[part 1 of 3: package /RB/PT/PCT_TopLvlComposition/SwComponentTypes]
AUTOSAR XML (schema 4-0-3)
package /RB/PT/PCT_TopLvlComposition/SwComponentTypes
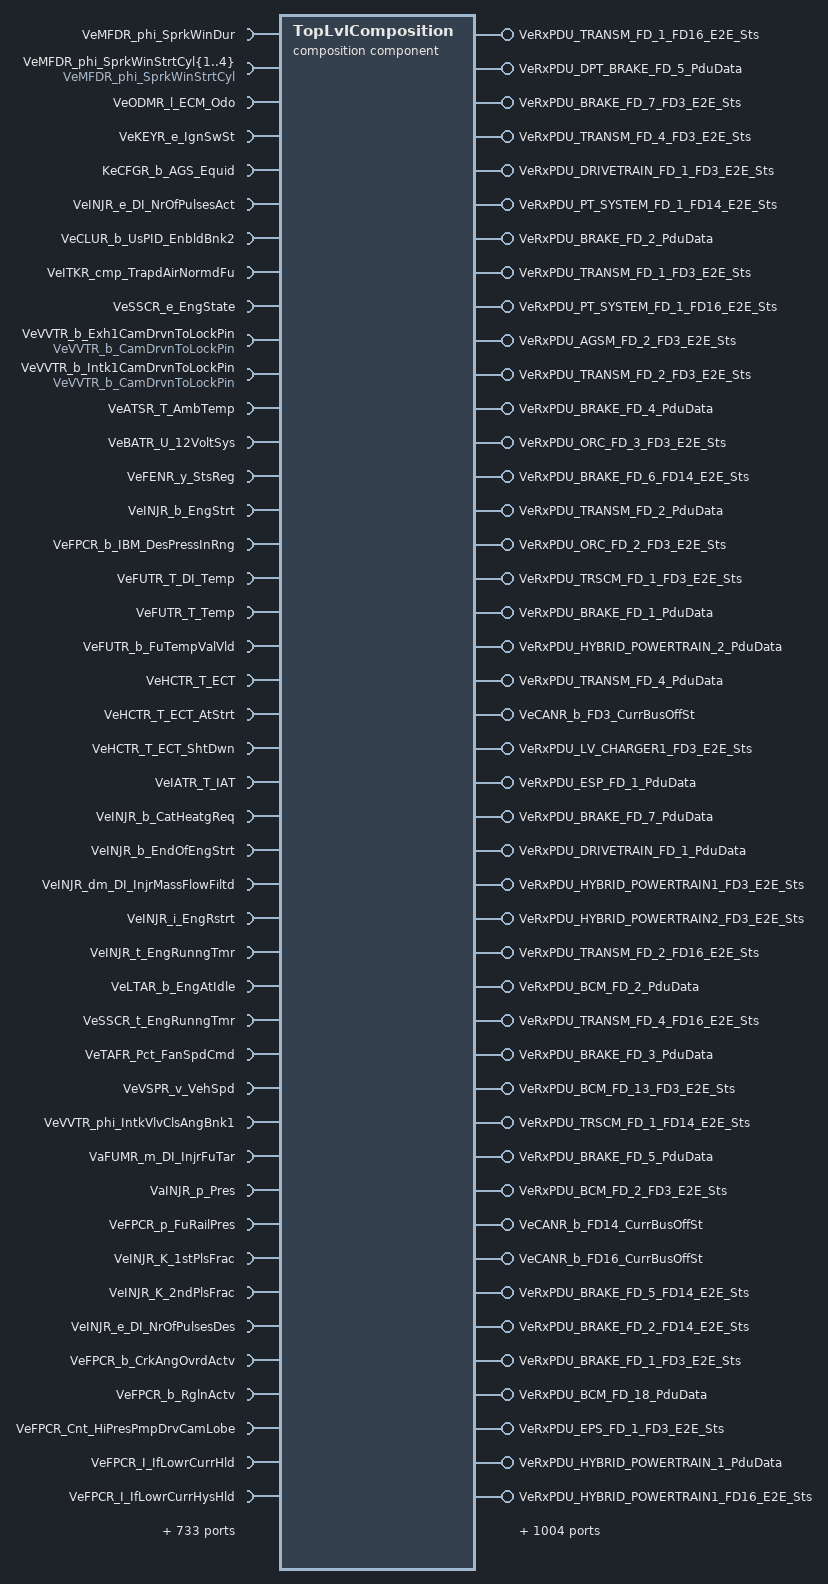
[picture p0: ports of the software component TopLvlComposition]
  composition sw component type TopLvlComposition
    59 x provide port:
      VeRxPDU_TRANSM_FD_1_FD16_E2E_Sts: provided-interface=VeRxPDU_TRANSM_FD_1_FD16_E2E_Sts
      VeRxPDU_DPT_BRAKE_FD_5_PduData: provided-interface=VeRxPDU_DPT_BRAKE_FD_5_PduData
      VeRxPDU_BRAKE_FD_7_FD3_E2E_Sts: provided-interface=VeRxPDU_BRAKE_FD_7_FD3_E2E_Sts
      VeRxPDU_TRANSM_FD_4_FD3_E2E_Sts: provided-interface=VeRxPDU_TRANSM_FD_4_FD3_E2E_Sts
      VeRxPDU_DRIVETRAIN_FD_1_FD3_E2E_Sts: provided-interface=VeRxPDU_DRIVETRAIN_FD_1_FD3_E2E_Sts
      VeRxPDU_PT_SYSTEM_FD_1_FD14_E2E_Sts: provided-interface=VeRxPDU_PT_SYSTEM_FD_1_FD14_E2E_Sts
      VeRxPDU_BRAKE_FD_2_PduData: provided-interface=VeRxPDU_BRAKE_FD_2_PduData
      VeRxPDU_TRANSM_FD_1_FD3_E2E_Sts: provided-interface=VeRxPDU_TRANSM_FD_1_FD3_E2E_Sts
      VeRxPDU_PT_SYSTEM_FD_1_FD16_E2E_Sts: provided-interface=VeRxPDU_PT_SYSTEM_FD_1_FD16_E2E_Sts
      VeRxPDU_AGSM_FD_2_FD3_E2E_Sts: provided-interface=VeRxPDU_AGSM_FD_2_FD3_E2E_Sts
      VeRxPDU_TRANSM_FD_2_FD3_E2E_Sts: provided-interface=VeRxPDU_TRANSM_FD_2_FD3_E2E_Sts
      VeRxPDU_BRAKE_FD_4_PduData: provided-interface=VeRxPDU_BRAKE_FD_4_PduData
      VeRxPDU_ORC_FD_3_FD3_E2E_Sts: provided-interface=VeRxPDU_ORC_FD_3_FD3_E2E_Sts
      VeRxPDU_BRAKE_FD_6_FD14_E2E_Sts: provided-interface=VeRxPDU_BRAKE_FD_6_FD14_E2E_Sts
      VeRxPDU_TRANSM_FD_2_PduData: provided-interface=VeRxPDU_TRANSM_FD_2_PduData
      VeRxPDU_ORC_FD_2_FD3_E2E_Sts: provided-interface=VeRxPDU_ORC_FD_2_FD3_E2E_Sts
      VeRxPDU_TRSCM_FD_1_FD3_E2E_Sts: provided-interface=VeRxPDU_TRSCM_FD_1_FD3_E2E_Sts
      VeRxPDU_BRAKE_FD_1_PduData: provided-interface=VeRxPDU_BRAKE_FD_1_PduData
      VeRxPDU_HYBRID_POWERTRAIN_2_PduData: provided-interface=VeRxPDU_HYBRID_POWERTRAIN_2_PduData
      VeRxPDU_TRANSM_FD_4_PduData: provided-interface=VeRxPDU_TRANSM_FD_4_PduData
      VeCANR_b_FD3_CurrBusOffSt: provided-interface=VeCANR_b_FD3_CurrBusOffSt
      VeRxPDU_LV_CHARGER1_FD3_E2E_Sts: provided-interface=VeRxPDU_LV_CHARGER1_FD3_E2E_Sts
      VeRxPDU_ESP_FD_1_PduData: provided-interface=VeRxPDU_ESP_FD_1_PduData
      VeRxPDU_BRAKE_FD_7_PduData: provided-interface=VeRxPDU_BRAKE_FD_7_PduData
      VeRxPDU_DRIVETRAIN_FD_1_PduData: provided-interface=VeRxPDU_DRIVETRAIN_FD_1_PduData
      VeRxPDU_HYBRID_POWERTRAIN1_FD3_E2E_Sts: provided-interface=VeRxPDU_HYBRID_POWERTRAIN1_FD3_E2E_Sts
      VeRxPDU_HYBRID_POWERTRAIN2_FD3_E2E_Sts: provided-interface=VeRxPDU_HYBRID_POWERTRAIN2_FD3_E2E_Sts
      VeRxPDU_TRANSM_FD_2_FD16_E2E_Sts: provided-interface=VeRxPDU_TRANSM_FD_2_FD16_E2E_Sts
      VeRxPDU_BCM_FD_2_PduData: provided-interface=VeRxPDU_BCM_FD_2_PduData
      VeRxPDU_TRANSM_FD_4_FD16_E2E_Sts: provided-interface=VeRxPDU_TRANSM_FD_4_FD16_E2E_Sts
      VeRxPDU_BRAKE_FD_3_PduData: provided-interface=VeRxPDU_BRAKE_FD_3_PduData
      VeRxPDU_BCM_FD_13_FD3_E2E_Sts: provided-interface=VeRxPDU_BCM_FD_13_FD3_E2E_Sts
      VeRxPDU_TRSCM_FD_1_FD14_E2E_Sts: provided-interface=VeRxPDU_TRSCM_FD_1_FD14_E2E_Sts
      VeRxPDU_BRAKE_FD_5_PduData: provided-interface=VeRxPDU_BRAKE_FD_5_PduData
      VeRxPDU_BCM_FD_2_FD3_E2E_Sts: provided-interface=VeRxPDU_BCM_FD_2_FD3_E2E_Sts
      VeCANR_b_FD14_CurrBusOffSt: provided-interface=VeCANR_b_FD14_CurrBusOffSt
      VeCANR_b_FD16_CurrBusOffSt: provided-interface=VeCANR_b_FD16_CurrBusOffSt
      VeRxPDU_BRAKE_FD_5_FD14_E2E_Sts: provided-interface=VeRxPDU_BRAKE_FD_5_FD14_E2E_Sts
      VeRxPDU_BRAKE_FD_2_FD14_E2E_Sts: provided-interface=VeRxPDU_BRAKE_FD_2_FD14_E2E_Sts
      VeRxPDU_BRAKE_FD_1_FD3_E2E_Sts: provided-interface=VeRxPDU_BRAKE_FD_1_FD3_E2E_Sts
      VeRxPDU_BCM_FD_18_PduData: provided-interface=VeRxPDU_BCM_FD_18_PduData
      VeRxPDU_EPS_FD_1_FD3_E2E_Sts: provided-interface=VeRxPDU_EPS_FD_1_FD3_E2E_Sts
      VeRxPDU_HYBRID_POWERTRAIN_1_PduData: provided-interface=VeRxPDU_HYBRID_POWERTRAIN_1_PduData
      VeRxPDU_HYBRID_POWERTRAIN1_FD16_E2E_Sts: provided-interface=VeRxPDU_HYBRID_POWERTRAIN1_FD16_E2E_Sts
      VeRxPDU_HYBRID_POWERTRAIN2_FD16_E2E_Sts: provided-interface=VeRxPDU_HYBRID_POWERTRAIN2_FD16_E2E_Sts
      VeRxPDU_HYBRID_POWERTRAIN_5_PduData: provided-interface=VeRxPDU_HYBRID_POWERTRAIN_5_PduData
      VeRxPDU_BRAKE_FD_5_FD3_E2E_Sts: provided-interface=VeRxPDU_BRAKE_FD_5_FD3_E2E_Sts
      VeRxPDU_HYBRID_POWERTRAIN5_FD3_E2E_Sts: provided-interface=VeRxPDU_HYBRID_POWERTRAIN5_FD3_E2E_Sts
      VeRxPDU_HYBRID_POWERTRAIN5_FD16_E2E_Sts: provided-interface=VeRxPDU_HYBRID_POWERTRAIN5_FD16_E2E_Sts
      VeRxPDU_ADAS_FD_INFO_FD14_E2E_Sts: provided-interface=VeRxPDU_ADAS_FD_INFO_FD14_E2E_Sts
      VeRxPDU_BRAKE_FD_3_FD3_E2E_Sts: provided-interface=VeRxPDU_BRAKE_FD_3_FD3_E2E_Sts
      VeRxPDU_BCM_FD_9_FD3_E2E_Sts: provided-interface=VeRxPDU_BCM_FD_9_FD3_E2E_Sts
      VeRxPDU_BRAKE_FD_2_FD3_E2E_Sts: provided-interface=VeRxPDU_BRAKE_FD_2_FD3_E2E_Sts
      VeRxPDU_BRAKE_FD_4_FD3_E2E_Sts: provided-interface=VeRxPDU_BRAKE_FD_4_FD3_E2E_Sts
      VeRxPDU_DPT_BRAKE_FD_2_PduData: provided-interface=VeRxPDU_DPT_BRAKE_FD_2_PduData
      VeRxPDU_BCM_FD_18_FD3_E2E_Sts: provided-interface=VeRxPDU_BCM_FD_18_FD3_E2E_Sts
      VeRxPDU_TRANSM_FD_1_PduData: provided-interface=VeRxPDU_TRANSM_FD_1_PduData
      VeLISR_h_DigIonSnsRes1: provided-interface=VeLISR_h_DigIonSnsRes
      VeLISR_h_DigIonSnsRes2: provided-interface=VeLISR_h_DigIonSnsRes
    11 x require port:
      VeMFDR_phi_SprkWinDur: required-interface=VeMFDR_phi_SprkWinDur
      VeMFDR_phi_SprkWinStrtCyl{1..4}: required-interface=VeMFDR_phi_SprkWinStrtCyl
      VeODMR_l_ECM_Odo: required-interface=VeODMR_l_ECM_Odo
      VeKEYR_e_IgnSwSt: required-interface=VeKEYR_e_IgnSwSt
      KeCFGR_b_AGS_Equid: required-interface=KeCFGR_b_AGS_Equid
      VeINJR_e_DI_NrOfPulsesAct: required-interface=VeINJR_e_DI_NrOfPulsesAct
      VeCLUR_b_UsPID_EnbldBnk2: required-interface=VeCLUR_b_UsPID_EnbldBnk2
      VeITKR_cmp_TrapdAirNormdFu: required-interface=VeITKR_cmp_TrapdAirNormdFu
    5 x provide port, all with provided-interface=IFMdulPwrMod:
      MdulPwrMod_{0..3}_Q_1
      MdulPwrMod_1_B_1
    require port VeSSCR_e_EngState: required-interface=VeSSCR_e_EngState
    provide port VeLBPR_p_BaroPress: provided-interface=VeLBPR_p_BaroPress
    require port VeVVTR_b_Exh1CamDrvnToLockPin: required-interface=VeVVTR_b_CamDrvnToLockPin
    require port VeVVTR_b_Intk1CamDrvnToLockPin: required-interface=VeVVTR_b_CamDrvnToLockPin
    72 x provide port:
      VeCAMR_b_Exh1CamInLimpIn: provided-interface=VeCAMR_b_CamInLimpIn
      VeCAMR_b_Intk1CamInLimpIn: provided-interface=VeCAMR_b_CamInLimpIn
      VeCAMR_b_IsExh1CamLockd: provided-interface=VeXXXR_b_IsLockd
      VeCAMR_b_IsIntk1CamLockd: provided-interface=VeXXXR_b_IsLockd
      VeCAMR_phi_Exh1CCLAdjdLkpn: provided-interface=VeCAMR_phi_CCL_AdjdLkpn
      VeCAMR_phi_Exh1CCLPosn: provided-interface=VeCAMR_phi_CCL_Posn
      VeCAMR_phi_Intk1CCLAdjdLkpn: provided-interface=VeCAMR_phi_CCL_AdjdLkpn
      VeCAMR_phi_Intk1CCLPosn: provided-interface=VeCAMR_phi_CCL_Posn
      VeCRKR_b_CrksftUnlckdInRun: provided-interface=VeCRKR_b_CrksftUnlckdInRun
      VeCRKR_b_IsCrksftLockd: provided-interface=VeXXXR_b_IsLockd
      VeCRKR_t_EPP_Prd: provided-interface=VeEPSR_t_EngPwrPlsPrd
      VeEPSR_Cnt_AirPrdtnFuCalcn_Eve: provided-interface=VeEPSR_Cnt_AirPrdtnFuCalcn_Eve
      VeEPSR_Cnt_BDCC_Eve: provided-interface=VeEPSR_Cnt_BDCC_Eve
      VeEPSR_Cnt_BDCE_Eve: provided-interface=VeEPSR_Cnt_BDCE_Eve
      VeEPSR_Cnt_EngStopdEve: provided-interface=VeEPSR_Cnt_EngStopdEve
      VeEPSR_Cnt_FastPahTrqCalcn_Eve: provided-interface=VeEPSR_Cnt_FastPahTrqCalcn_Eve
      VeEPSR_Cnt_FwdRotDtctdEve: provided-interface=VeEPSR_Cnt_FwdRotDtctdEve
      VeEPSR_Cnt_MidEngPwrPlsEve: provided-interface=VeEPSR_Cnt_MidEngPwrPlsEve
      VeEPSR_Cnt_SyncnEve: provided-interface=VeEPSR_Cnt_SyncnEve
      VeEPSR_Cnt_TDCI_Eve: provided-interface=VeEPSR_Cnt_TDCI_Eve
      VeEPSR_Cnt_TDCP_1_Eve: provided-interface=VeEPSR_Cnt_TDCP_1_Eve
      VeEPSR_Cnt_TDCP_Eve: provided-interface=VeEPSR_Cnt_TDCP_Eve
      VeEPSR_b_ESS_SyncStopNotAllwd: provided-interface=VeEPSR_b_ESS_SyncStopNotAllwd
      VeEPSR_b_EngPosnIsFullySyncd: provided-interface=VeEPSR_b_EngPosnIsFullySyncd
      VeEPSR_b_EngRvsRotActv: provided-interface=VeEPSR_b_EngRvsRotActv
      VeEPSR_t_DynFuCtrlWin_EngRotPrd: provided-interface=VeEPSR_t_EngRotPrd
      VeEPSR_t_EngPwrPlsPrd: provided-interface=VeEPSR_t_EngPwrPlsPrd
      VeEPSR_t_MisfWin{1..3}_EngRotPrd: provided-interface=VeEPSR_t_EngRotPrd
      VeRPMR_dn_EngAcceltn: provided-interface=VeRPMR_dn_EngAcceltn
      VeRPMR_dn_EngAcceltnNotFiltd: provided-interface=VeRPMR_dn_EngAcceltnNotFiltd
      VeRPMR_n_EngSpd: provided-interface=VeRPMR_n_EngSpd
      VeRPMR_n_EngSpdFastRate: provided-interface=VeRPMR_n_EngSpdFastRate
      VeRPMR_n_EngSpdResl1: provided-interface=VeRPMR_n_EngSpdResl1
      WrCamCrksftDifExh1: provided-interface=CamCrksftDifSR
      WrCamCrksftDifIntk1: provided-interface=CamCrksftDifSR
      EngMtnMod: provided-interface=IFEngMtnMod
      EngSpdMod: provided-interface=IFEngSpdMod
      CamCrksftDifCmnCS: provided-interface=CamCrksftDifCmnCS
      GetCAMR_b_Exh1CamInLimpIn: provided-interface=GetCAMR_b_CamInLimpIn
      GetCAMR_b_Intk1CamInLimpIn: provided-interface=GetCAMR_b_CamInLimpIn
      GetCAMR_b_IsExh1CamLockd: provided-interface=IFCamPosnEtpuIfCS_IsLockd
      GetCAMR_b_IsIntk1CamLockd: provided-interface=IFCamPosnEtpuIfCS_IsLockd
      GetCAMR_i_Exh1CamEdgeIdx: provided-interface=GetCAMR_i_CamEdgeIdx
      GetCRKR_Cnt_CrksftToothCnt: provided-interface=GetCRKR_Cnt_CrksftToothCnt
      GetCRKR_b_CrksftFltPrsnt: provided-interface=GetCRKR_b_CrksftFltPrsnt
      GetCRKR_b_CrksftIntmLimpIn: provided-interface=GetCRKR_b_CrksftIntmLimpIn
      GetCRKR_b_IsCrksftFwdRotDtctd: provided-interface=GetCRKR_b_IsCrksftFwdRotDtctd
      GetCRKR_b_IsCrksftMtnDtctd: provided-interface=GetCRKR_b_IsCrksftMtnDtctd
      GetCRKR_t_EPP_Prd: provided-interface=GetCRKR_t_EPP_Prd
      GetEPSR_b_EngPosnIsFullySyncd: provided-interface=GetEPSR_b_EngPosnIsFullySyncd
      GetEPSR_b_EngSynchronousEveEnbld: provided-interface=GetEPSR_b_EngSynchronousEveEnbld
      GetEPSR_i_BDCC_FgSeqAtAng: provided-interface=GetEPSR_i_BDCC_FgSeqAtAng
      GetEPSR_i_BDCE_FgSeqAtAng: provided-interface=GetEPSR_i_BDCE_FgSeqAtAng
      GetEPSR_i_CylInFgSeq: provided-interface=GetEPSR_i_CylInFgSeq
      GetEPSR_i_FgSeqAtAng: provided-interface=GetEPSR_i_FgSeqAtAng
      GetEPSR_i_NextCyl: provided-interface=GetEPSR_i_NextCyl
      GetEPSR_i_NextInFgSeq: provided-interface=GetEPSR_i_NextInFgSeq
      GetEPSR_i_PrevInFgSeq: provided-interface=GetEPSR_i_PrevInFgSeq
      GetEPSR_i_TDCP_CylAtAng: provided-interface=GetEPSR_i_TDCP_CylAtAng
      GetEPSR_i_TDCP_FgSeqAtAng: provided-interface=GetEPSR_i_TDCP_FgSeqAtAng
      GetEPSR_phi_BDCC_AngOfCyl: provided-interface=GetEPSR_phi_BDCC_AngOfCyl
      GetEPSR_phi_BDCE_AngOfCyl: provided-interface=GetEPSR_phi_BDCE_AngOfCyl
      GetEPSR_phi_EngPosn: provided-interface=GetEPSR_phi_EngPosn
      GetEPSR_phi_FastPahTrqCalcn_AngOfCyl: provided-interface=GetEPSR_phi_FastPahTrqCalcn_AngOfCyl
      GetEPSR_t_EngPwrPlsPrd: provided-interface=GetEPSR_t_EngPwrPlsPrd
      GetVCMR_b_VVA_ActWrkgModCod: provided-interface=GetVCMR_b_VVA_ActWrkgModCod
      GetLLSR_t_IgnMaxDwell: provided-interface=GetLLSR_t_IgnMaxDwell
      SetLLSR_IgnAng: provided-interface=SetLLSR_IgnAng
      SetLLSR_IgnDwell: provided-interface=SetLLSR_IgnDwell
      SetLLSR_IgnMultiStrike: provided-interface=SetLLSR_IgnMultiStrike
    22 x require port:
      VeATSR_T_AmbTemp: required-interface=VeATSR_T_AmbTemp
      VeBATR_U_12VoltSys: required-interface=VeBATR_U_12VoltSys
      VeFENR_y_StsReg: required-interface=VeFENR_y_StsReg
      VeINJR_b_EngStrt: required-interface=VeINJR_b_EngStrt
      VeFPCR_b_IBM_DesPressInRng: required-interface=VeFPCR_b_IBM_DesPressInRng
      VeFUTR_T_DI_Temp: required-interface=VeFUTR_T_DI_Temp
      VeFUTR_T_Temp: required-interface=VeFUTR_T_Temp
      VeFUTR_b_FuTempValVld: required-interface=VeFUTR_b_FuTempValVld
      VeHCTR_T_ECT: required-interface=VeHCTR_T_ECT
      VeHCTR_T_ECT_AtStrt: required-interface=VeHCTR_T_ECT_AtStrt
      VeHCTR_T_ECT_ShtDwn: required-interface=VeHCTR_T_ECT_ShtDwn
      VeIATR_T_IAT: required-interface=VeIATR_T_IAT
      VeINJR_b_CatHeatgReq: required-interface=VeINJR_b_CatHeatgReq
      VeINJR_b_EndOfEngStrt: required-interface=VeINJR_b_EndOfEngStrt
      VeINJR_dm_DI_InjrMassFlowFiltd: required-interface=VeINJR_dm_DI_InjrMassFlowFiltd
      VeINJR_i_EngRstrt: required-interface=VeINJR_i_EngRstrt
      VeINJR_t_EngRunngTmr: required-interface=VeINJR_t_EngRunngTmr
      VeLTAR_b_EngAtIdle: required-interface=VeLTAR_b_EngAtIdle
      VeSSCR_t_EngRunngTmr: required-interface=VeSSCR_t_EngRunngTmr
      VeTAFR_Pct_FanSpdCmd: required-interface=VeTAFR_Pct_FanSpdCmd
      VeVSPR_v_VehSpd: required-interface=VeVSPR_v_VehSpd
      VeVVTR_phi_IntkVlvClsAngBnk1: required-interface=VeVVTR_phi_IntkVlvClsAngBnk1
    provide port VeIBMR_b_CVO_RailSpReqEnbl: provided-interface=VeIBMR_b_CVO_RailSpReqEnbl
    provide port VeIBMR_p_FuRailPresSetPt: provided-interface=VeIBMR_p_FuRailPresSetPt
    6 x require port:
      VaFUMR_m_DI_InjrFuTar: required-interface=VaFUMR_m_DI_InjrFuTar
      VaINJR_p_Pres: required-interface=VaINJR_p_Pres
      VeFPCR_p_FuRailPres: required-interface=VeFPCR_p_FuRailPres
      VeINJR_K_1stPlsFrac: required-interface=VeINJR_K_1stPlsFrac
      VeINJR_K_2ndPlsFrac: required-interface=VeINJR_K_2ndPlsFrac
      VeINJR_e_DI_NrOfPulsesDes: required-interface=VeINJR_e_DI_NrOfPulsesDes
    126 x provide port:
      GetLLFR_b_FuDlvdCylDI: provided-interface=GetLLFR_b_FuDlvdCyl
      GetLLFR_b_InjAngEndCfgDI: provided-interface=GetLLFR_b_InjAngEndCfg
      GetLLFR_b_InjrEnblReqdForCylDI: provided-interface=GetLLFR_b_InjrEnblReqdForCyl
      GetLLFR_b_InjrEnbldDI: provided-interface=GetLLFR_b_InjrEnbld
      GetLLFR_phi_InjAngDI: provided-interface=GetLLFR_phi_InjAng
      GetLLFR_phi_InjrHardMaxAngDI: provided-interface=GetLLFR_phi_InjrHardMaxAng
      GetLLFR_phi_InjrHardMinAngDI: provided-interface=GetLLFR_phi_InjrHardMinAng
      GetLLFR_t_InjrPlsWidthDlvdDI: provided-interface=GetLLFR_t_InjrPlsWidthDlvd
      SetLLFR_ImdtEnblInjrDI: provided-interface=SetLLFR_ImdtEnblInjr
      SetLLFR_InjAngDI: provided-interface=SetLLFR_InjAng
      SetLLFR_InjAngEndCfgDI: provided-interface=SetLLFR_InjAngEndCfg
      SetLLFR_InjrDsblDI: provided-interface=SetLLFR_InjrDsbl
      SetLLFR_InjrMaxAngDI: provided-interface=SetLLFR_InjrMaxAng
      SetLLFR_InjrMinAngDI: provided-interface=SetLLFR_InjrMinAng
      GetLLFR_Cnt_InjrMaxNumPulses: variation-point={short-label=VP_GetLLFR_Cnt_InjrMaxNumPulses_T4EVO, sw-syscond=( /RB/PT/Common/SwSystemconsts/Adjustables/PSSC009T4EVO_SC == 1)}, provided-interface=GetLLFR_Cnt_InjrMaxNumPulses
      GetLLFR_b_AllInjrEnbld: variation-point={short-label=VP_GetLLFR_b_AllInjrEnbld_T4EVO, sw-syscond=( /RB/PT/Common/SwSystemconsts/Adjustables/PSSC009T4EVO_SC == 1)}, provided-interface=GetLLFR_b_AllInjrEnbld
      GetLLFR_b_AreAnyInjrEnbld: variation-point={short-label=VP_GetLLFR_b_AreAnyInjrEnbld_T4EVO, sw-syscond=( /RB/PT/Common/SwSystemconsts/Adjustables/PSSC009T4EVO_SC == 1)}, provided-interface=GetLLFR_b_AreAnyInjrEnbld
      GetLLFR_b_AreAnyInjrOn: variation-point={short-label=VP_GetLLFR_b_AreAnyInjrOn_T4EVO, sw-syscond=( /RB/PT/Common/SwSystemconsts/Adjustables/PSSC009T4EVO_SC == 1)}, provided-interface=GetLLFR_b_AreAnyInjrOn
      GetLLFR_b_FuDlvdCyl: variation-point={short-label=VP_GetLLFR_b_FuDlvdCyl_T4EVO, sw-syscond=( /RB/PT/Common/SwSystemconsts/Adjustables/PSSC009T4EVO_SC == 1)}, provided-interface=GetLLFR_b_FuDlvdCyl
      GetLLFR_b_InjAngEndCfg: variation-point={short-label=VP_GetLLFR_b_InjAngEndCfg_T4EVO, sw-syscond=( /RB/PT/Common/SwSystemconsts/Adjustables/PSSC009T4EVO_SC == 1)}, provided-interface=GetLLFR_b_InjAngEndCfg
      GetLLFR_b_InjrConjRstrApply: variation-point={short-label=VP_GetLLFR_b_InjrConjRstrApply_T4EVO, sw-syscond=( /RB/PT/Common/SwSystemconsts/Adjustables/PSSC009T4EVO_SC == 1)}, provided-interface=GetLLFR_b_InjrConjRstrApply
      GetLLFR_b_InjrConjRstrDoNotApply: variation-point={short-label=VP_GetLLFR_b_InjrConjRstrDoNotApply_T4EVO, sw-syscond=( /RB/PT/Common/SwSystemconsts/Adjustables/PSSC009T4EVO_SC == 1)}, provided-interface=GetLLFR_b_InjrConjRstrDoNotApply
      GetLLFR_b_InjrDsbld: variation-point={short-label=VP_GetLLFR_b_InjrDsbld_T4EVO, sw-syscond=( /RB/PT/Common/SwSystemconsts/Adjustables/PSSC009T4EVO_SC == 1)}, provided-interface=GetLLFR_b_InjrDsbld
      GetLLFR_b_InjrEnblReqdForCyl: variation-point={short-label=VP_GetLLFR_b_InjrEnblReqdForCyl_T4EVO, sw-syscond=( /RB/PT/Common/SwSystemconsts/Adjustables/PSSC009T4EVO_SC == 1)}, provided-interface=GetLLFR_b_InjrEnblReqdForCyl
      GetLLFR_b_InjrEnbld: variation-point={short-label=VP_GetLLFR_b_InjrEnbld_T4EVO, sw-syscond=( /RB/PT/Common/SwSystemconsts/Adjustables/PSSC009T4EVO_SC == 1)}, provided-interface=GetLLFR_b_InjrEnbld
      GetLLFR_phi_InjAng: variation-point={short-label=VP_GetLLFR_phi_InjAng_T4EVO, sw-syscond=( /RB/PT/Common/SwSystemconsts/Adjustables/PSSC009T4EVO_SC == 1)}, provided-interface=GetLLFR_phi_InjAng
      GetLLFR_phi_InjrHardMaxAng: variation-point={short-label=VP_GetLLFR_phi_InjrHardMaxAng_T4EVO, sw-syscond=( /RB/PT/Common/SwSystemconsts/Adjustables/PSSC009T4EVO_SC == 1)}, provided-interface=GetLLFR_phi_InjrHardMaxAng
      GetLLFR_phi_InjrHardMinAng: variation-point={short-label=VP_GetLLFR_phi_InjrHardMinAng_T4EVO, sw-syscond=( /RB/PT/Common/SwSystemconsts/Adjustables/PSSC009T4EVO_SC == 1)}, provided-interface=GetLLFR_phi_InjrHardMinAng
      GetLLFR_t_InjrPlsWidthDlvd: variation-point={short-label=VP_GetLLFR_t_InjrPlsWidthDlvd_T4EVO, sw-syscond=( /RB/PT/Common/SwSystemconsts/Adjustables/PSSC009T4EVO_SC == 1)}, provided-interface=GetLLFR_t_InjrPlsWidthDlvd
      SetLLFR_ImdtDsblAllInjr: variation-point={short-label=VP_SetLLFR_ImdtDsblAllInjr_T4EVO, sw-syscond=( /RB/PT/Common/SwSystemconsts/Adjustables/PSSC009T4EVO_SC == 1)}, provided-interface=SetLLFR_ImdtDsblAllInjr
      SetLLFR_ImdtEnblInjr: variation-point={short-label=VP_SetLLFR_ImdtEnblInjr_T4EVO, sw-syscond=( /RB/PT/Common/SwSystemconsts/Adjustables/PSSC009T4EVO_SC == 1)}, provided-interface=SetLLFR_ImdtEnblInjr
      SetLLFR_InjAng: variation-point={short-label=VP_SetLLFR_InjAng_T4EVO, sw-syscond=( /RB/PT/Common/SwSystemconsts/Adjustables/PSSC009T4EVO_SC == 1)}, provided-interface=SetLLFR_InjAng
      SetLLFR_InjAngDelt: variation-point={short-label=VP_SetLLFR_InjAngDelt_T4EVO, sw-syscond=( /RB/PT/Common/SwSystemconsts/Adjustables/PSSC009T4EVO_SC == 1)}, provided-interface=SetLLFR_InjAngDelt
      SetLLFR_InjAngEndCfg: variation-point={short-label=VP_SetLLFR_InjAngEndCfg_T4EVO, sw-syscond=( /RB/PT/Common/SwSystemconsts/Adjustables/PSSC009T4EVO_SC == 1)}, provided-interface=SetLLFR_InjAngEndCfg
      SetLLFR_InjrAllw0PlsWidthCmd: variation-point={short-label=VP_SetLLFR_InjrAllw0PlsWidthCmd_T4EVO, sw-syscond=( /RB/PT/Common/SwSystemconsts/Adjustables/PSSC009T4EVO_SC == 1)}, provided-interface=SetLLFR_InjrAllw0PlsWidthCmd
      SetLLFR_InjrDeltLimCfg: variation-point={short-label=VP_SSetLLFR_InjrDeltLimCfg_T4EVO, sw-syscond=( /RB/PT/Common/SwSystemconsts/Adjustables/PSSC009T4EVO_SC == 1)}, provided-interface=SetLLFR_InjrDeltLimCfg
      SetLLFR_InjrDsbl: variation-point={short-label=VP_SetLLFR_InjrDsbl_T4EVO, sw-syscond=( /RB/PT/Common/SwSystemconsts/Adjustables/PSSC009T4EVO_SC == 1)}, provided-interface=SetLLFR_InjrDsbl
      SetLLFR_InjrMaxAng: variation-point={short-label=VP_SetLLFR_InjrMaxAng_T4EVO, sw-syscond=( /RB/PT/Common/SwSystemconsts/Adjustables/PSSC009T4EVO_SC == 1)}, provided-interface=SetLLFR_InjrMaxAng
      SetLLFR_InjrMinAng: variation-point={short-label=VP_SetLLFR_InjrMinAng_T4EVO, sw-syscond=( /RB/PT/Common/SwSystemconsts/Adjustables/PSSC009T4EVO_SC == 1)}, provided-interface=SetLLFR_InjrMinAng
      SetLLFR_InjrMinPlsWidth: variation-point={short-label=VP_SetLLFR_InjrMinPlsWidth_T4EVO, sw-syscond=( /RB/PT/Common/SwSystemconsts/Adjustables/PSSC009T4EVO_SC == 1)}, provided-interface=SetLLFR_InjrMinPlsWidth
      SetLLFR_InjrMinTiBtwnPls: variation-point={short-label=VP_SetLLFR_InjrMinTiBtwnPls_T4EVO, sw-syscond=( /RB/PT/Common/SwSystemconsts/Adjustables/PSSC009T4EVO_SC == 1)}, provided-interface=SetLLFR_InjrMinTiBtwnPls
      SetLLFR_InjrPlsMd: variation-point={short-label=VP_SetLLFR_InjrPlsMd_T4EVO, sw-syscond=( /RB/PT/Common/SwSystemconsts/Adjustables/PSSC009T4EVO_SC == 1)}, provided-interface=SetLLFR_InjrPlsMd
      SetLLFR_InjrPlsOffs: variation-point={short-label=VP_SetLLFR_InjrPlsOffs_T4EVO, sw-syscond=( /RB/PT/Common/SwSystemconsts/Adjustables/PSSC009T4EVO_SC == 1)}, provided-interface=SetLLFR_InjrPlsOffs
      SetLLFR_InjrPlsSeprnDly: variation-point={short-label=VP_SetLLFR_InjrPlsSeprnDly_T4EVO, sw-syscond=( /RB/PT/Common/SwSystemconsts/Adjustables/PSSC009T4EVO_SC == 1)}, provided-interface=SetLLFR_InjrPlsSeprnDly
      SetLLFR_InjrPlsWidth: variation-point={short-label=VP_SetLLFR_InjrPlsWidth_T4EVO, sw-syscond=( /RB/PT/Common/SwSystemconsts/Adjustables/PSSC009T4EVO_SC == 1)}, provided-interface=SetLLFR_InjrPlsWidth
      SetLLFR_InjrSubPlsCmd: variation-point={short-label=VP_SetLLFR_InjrSubPlsCmd_T4EVO, sw-syscond=( /RB/PT/Common/SwSystemconsts/Adjustables/PSSC009T4EVO_SC == 1)}, provided-interface=SetLLFR_InjrSubPlsCmd
      ActuateLLFR_InjrAsyncPls: variation-point={short-label=VP_ActuateLLFR_InjrAsyncPls_T4EVO, sw-syscond=( /RB/PT/Common/SwSystemconsts/Adjustables/PSSC009T4EVO_SC == 1)}, provided-interface=ActuateLLFR_InjrAsyncPls
      WgPosn1: provided-interface=IFAdcInpRawVal
      VeADCR_U_WgPosn1: provided-interface=VsADCR_e_CnvnRes
      AirCdngPSnsr: provided-interface=IFAdcInpRawVal
      ColdCrkCasePSnsr: provided-interface=IFAdcInpRawVal
      CrkBattMonr: provided-interface=IFAdcInpRawVal
      EngCooltT: provided-interface=IFAdcInpRawVal
      FuTankPSnsr: provided-interface=IFAdcInpRawVal
      GdiFuRailP1: provided-interface=IFAdcInpRawVal
      HoodAjar: provided-interface=IFAdcInpRawVal
      IntkAirT: variation-point={short-label=VP_IntkAirT_T4EVO, sw-syscond=( /RB/PT/Common/SwSystemconsts/Adjustables/PSSC009T4EVO_SC == 1)}, provided-interface=IFAdcInpRawVal
      LoPFuSnsr: provided-interface=IFAdcInpRawVal
      CooltInletTemp: provided-interface=IFAdcInpRawVal
      MnfldAirP: provided-interface=IFAdcInpRawVal
      MnfldGasT: variation-point={short-label=VP_MnfldGasT_T4EVO, sw-syscond=( /RB/PT/Common/SwSystemconsts/Adjustables/PSSC009T4EVO_SC == 1)}, provided-interface=IFAdcInpRawVal
      BrkPdlPosnSnsr: variation-point={short-label=VP_BrkPdlPosnSnsr_T4EVO, sw-syscond=( /RB/PT/Common/SwSystemconsts/Adjustables/PSSC009T4EVO_SC == 1)}, provided-interface=IFAdcInpRawVal
      EngSwtBatt: provided-interface=IFAdcInpRawVal
      OilPSnsr: provided-interface=IFAdcInpRawVal
      OilTSnsr: provided-interface=IFAdcInpRawVal
      PedlValSnsr1: provided-interface=IFAdcInpRawVal
      SysU12Volt: provided-interface=IFAdcInpRawVal
      ThrIntkGasT: provided-interface=IFAdcInpRawVal
      ThrIntkP: provided-interface=IFAdcInpRawVal
      ThrPosnSnsr1: provided-interface=IFAdcInpRawVal
      ThrPosnSnsr2: provided-interface=IFAdcInpRawVal
      VeADCR_U_AirCdngPresSnsr: provided-interface=VsADCR_e_CnvnRes
      VeADCR_U_CldCrkCasePresSnsr: provided-interface=VsADCR_e_CnvnRes
      PedlValSnsr2: provided-interface=IFAdcInpRawVal
      VeADCR_U_CrkBattMonr: provided-interface=VsADCR_e_CnvnRes
      VeADCR_U_EngCooltTemp: provided-interface=VsADCR_e_CnvnRes
      VeADCR_U_FuTankPresSnsr: provided-interface=VsADCR_e_CnvnRes
      VeADCR_U_GDI_FuRail1Pres: provided-interface=VsADCR_e_CnvnRes
      VeADCR_U_HoodAjar: provided-interface=VsADCR_e_CnvnRes
      VeADCR_U_IntkAirTemp: variation-point={short-label=VP_VeADCR_U_IntkAirTemp_T4EVO, sw-syscond=( /RB/PT/Common/SwSystemconsts/Adjustables/PSSC009T4EVO_SC == 1)}, provided-interface=VsADCR_e_CnvnRes
      VeADCR_U_LoPresFuSnsr: provided-interface=VsADCR_e_CnvnRes
      VeADCR_U_LTR_TempSnsr: provided-interface=VsADCR_e_CnvnRes
      VeADCR_U_MnfdAirPres: provided-interface=VsADCR_e_CnvnRes
      VeADCR_U_EngSwtBatt: provided-interface=VsADCR_e_CnvnRes
      VeADCR_U_MnfdGasTemp: variation-point={short-label=VP_VeADCR_U_MnfdGasTemp_T4EVO, sw-syscond=( /RB/PT/Common/SwSystemconsts/Adjustables/PSSC009T4EVO_SC == 1)}, provided-interface=VsADCR_e_CnvnRes
      VeADCR_U_BrkPdlPosnSnsr: variation-point={short-label=VP_VeADCR_U_BrkPdlPosnSnsr_T4EVO, sw-syscond=( /RB/PT/Common/SwSystemconsts/Adjustables/PSSC009T4EVO_SC == 1)}, provided-interface=VsADCR_e_CnvnRes
      VeADCR_U_OilPresSnsr: provided-interface=VsADCR_e_CnvnRes
      VeADCR_U_OilTempSnsr: provided-interface=VsADCR_e_CnvnRes
      VeADCR_U_PdlValSnsr1: provided-interface=VsADCR_e_CnvnRes
      VeADCR_U_SysVolt12Volt: provided-interface=VsADCR_e_CnvnRes
      VeADCR_U_PdlValSnsr2: provided-interface=VsADCR_e_CnvnRes
      PedlValSnsr2Aux: provided-interface=IFAdcInpRawVal
      VeADCR_U_ThrIntkGasTempSns: provided-interface=VsADCR_e_CnvnRes
      VeADCR_U_ThrIntkPresSns: provided-interface=VsADCR_e_CnvnRes
      VeADCR_U_TPS1: provided-interface=VsADCR_e_CnvnRes
      VeADCR_U_TPS2: provided-interface=VsADCR_e_CnvnRes
      VeADCR_U_PdlValSnsr2Aux: variation-point={short-label=VP_VeADCR_U_PdlValSnsr2Aux_T4EVO, sw-syscond=( /RB/PT/Common/SwSystemconsts/Adjustables/PSSC009T4EVO_SC == 1)}, provided-interface=VsADCR_e_CnvnRes
      VsADCR_U_CalInp1: provided-interface=VsADCR_e_CnvnRes
      CalInp1: provided-interface=IFAdcInpRawVal
      VsADCR_U_CalInp2: provided-interface=VsADCR_e_CnvnRes
      CalInp2: provided-interface=IFAdcInpRawVal
      VeADCR_U_C3WV: provided-interface=VsADCR_e_CnvnRes
      Coolt3WayVlv: provided-interface=IFAdcInpRawVal
      VeADCR_U_PFIFuRailTemp: provided-interface=VsADCR_e_CnvnRes
      GetADCR_U_PFIFuRailTempAdcInp: provided-interface=IFAdcInpRawVal
      VeADCR_U_PFIFuRailPress: provided-interface=VsADCR_e_CnvnRes
      GetADCR_U_PFIFuRailPressAdcInp: provided-interface=IFAdcInpRawVal
      VeADCR_U_CluSns: provided-interface=VsADCR_e_CnvnRes
      GetADCR_U_CluSnsAdcInp: provided-interface=IFAdcInpRawVal
      VeADCR_U_OilShutOffValveFb: provided-interface=VsADCR_e_CnvnRes
      GetADCR_U_OilShutOffValveFbAdcInp: provided-interface=IFAdcInpRawVal
      VeLLKR_Cnt_MeasmtWin1_SwKnkCh{1..3}: provided-interface=VeLLKR_Cnt_MeasmtWin
      VeLLKR_Cnt_MeasmtWin2_SwKnkCh{1..3}: provided-interface=VeLLKR_Cnt_MeasmtWin
      RequestLLKR_Measmt_SwKnkCh{1..3}: provided-interface=RequestLLKR_Measmt
      UpdateLLKR_FiltCoeff_SwKnkCh{1..3}: provided-interface=UpdateLLKR_FiltCoeff
      UpdateLLKR_MeasmtWinData_SwKnkCh{1..3}: provided-interface=UpdateLLKR_MeasmtWinData
    11 x require port:
      VeFPCR_b_CrkAngOvrdActv: required-interface=VeFPCR_b_CrkAngOvrdActv
      VeFPCR_b_RglnActv: required-interface=VeFPCR_b_RglnActv
      VeFPCR_Cnt_HiPresPmpDrvCamLobe: required-interface=VeFPCR_Cnt_HiPresPmpDrvCamLobe
      VeFPCR_I_IfLowrCurrHld: required-interface=VeFPCR_I_IfLowrCurrHld
      VeFPCR_I_IfLowrCurrHysHld: required-interface=VeFPCR_I_IfLowrCurrHysHld
      VeFPCR_I_IfLowrCurrHysPullIn: required-interface=VeFPCR_I_IfLowrCurrHysPullIn
      VeFPCR_I_IfLowrCurrPullIn: required-interface=VeFPCR_I_IfLowrCurrPullIn
      VeFPCR_phi_IfCrkAng: required-interface=VeFPCR_phi_IfCrkAng
      VeFPCR_phi_IfCrkAngOffs: required-interface=VeFPCR_phi_IfCrkAngOffs
      VeFPCR_phi_IfHldCrkAng: required-interface=VeFPCR_phi_IfHldCrkAng
      VeFPCR_t_IfLowrCurrPullInTi: required-interface=VeFPCR_t_IfLowrCurrPullInTi
    9 x provide port:
      VeLWRR_I_PmpCellUs10MsBnk1: provided-interface=VeLWRR_I_PmpCellUs10MsBnk1
      VeLWRR_I_PmpCellUs10MsBnk2: provided-interface=VeLWRR_I_PmpCellUs10MsBnk2
      VeLWRR_I_PmpCellUsMidEPP_Bnk1: provided-interface=VeLWRR_I_PmpCellUsMidEPP_Bnk1
      VeLWRR_I_PmpCellUsTDC_Bnk1: provided-interface=VeLWRR_I_PmpCellUsTDC_Bnk1
      VeLWRR_I_PmpCellUsTDC_Bnk2: provided-interface=VeLWRR_I_PmpCellUsTDC_Bnk2
      VeLWRR_R_WRO2_CellResistUsBnk1: provided-interface=VeLWRR_R_WRO2_CellResistUsBnk1
      VeLLTR_t_EvapSysPSwtTi: provided-interface=VeLLTR_t_EvapSysPSwtTi
      VeRxPDU_DPT_BRAKE_FD_6_PduData: provided-interface=VeRxPDU_DPT_BRAKE_FD_6_PduData
      VeCANR_b_CCAN12_CurrBusOffSt: provided-interface=VeCANR_b_CCAN12_CurrBusOffSt
    21 x require port:
      SendCANR_CRC_ENGINE1_FD14: required-interface=SendCANR_CRC_ENGINE1_FD14
      SendCANR_MC_ENG1_FD14: required-interface=SendCANR_MC_ENG1_FD14
      SendCANR_ThrmlMngmtActvW_FD14: required-interface=SendCANR_ThrmlMngmtActvW_FD14
      SendCANR_CRC_ENGINE3_FD14: required-interface=SendCANR_CRC_ENGINE3_FD14
      SendCANR_ISASts_FD14: required-interface=SendCANR_ISASts_FD14
      SendCANR_MC_ENG3_FD14: required-interface=SendCANR_MC_ENG3_FD14
      SendCANR_Override_FD14: required-interface=SendCANR_Override_FD14
      SendCANR_SpeedLimitSts_FD14: required-interface=SendCANR_SpeedLimitSts_FD14
      SendCANR_CRC_ENGINE7_FD14: required-interface=SendCANR_CRC_ENGINE7_FD14
      SendCANR_MC_ENG7_FD14: required-interface=SendCANR_MC_ENG7_FD14
      SendCANR_ECM_TRSC_Resp_FD14: required-interface=SendCANR_ECM_TRSC_Resp_FD14
      SendCANR_CRC_ENGINE1_FD14Vld: required-interface=SendCANR_CRC_ENGINE1_FD14Vld
      SendCANR_MC_ENG1_FD14Vld: required-interface=SendCANR_MC_ENG1_FD14Vld
      SendCANR_ThrmlMngmtActvW_FD14Vld: required-interface=SendCANR_ThrmlMngmtActvW_FD14Vld
      SendCANR_CRC_ENGINE3_FD14Vld: required-interface=SendCANR_CRC_ENGINE3_FD14Vld
      SendCANR_ISASts_FD14Vld: required-interface=SendCANR_ISASts_FD14Vld
      SendCANR_MC_ENG3_FD14Vld: required-interface=SendCANR_MC_ENG3_FD14Vld
      SendCANR_Override_FD14Vld: required-interface=SendCANR_Override_FD14Vld
      SendCANR_CRC_ENGINE7_FD14Vld: required-interface=SendCANR_CRC_ENGINE7_FD14Vld
      SendCANR_MC_ENG7_FD14Vld: required-interface=SendCANR_MC_ENG7_FD14Vld
      SendCANR_ECM_TRSC_Resp_FD14Vld: required-interface=SendCANR_ECM_TRSC_Resp_FD14Vld
    12 x provide port:
      VeCANR_y_MsgCtr_ADAS_FD_HMIFD14: provided-interface=VeCANR_y_MsgCtr_ADAS_FD_HMIFD14
      VeCANR_y_CRC_ADAS_FD_HMI_FD14: provided-interface=VeCANR_y_CRC_ADAS_FD_HMI_FD14
      VeCANR_v_Set_Speed_MPH: provided-interface=VeCANR_v_Set_Speed_MPH
      VeCANR_v_Set_Speed_KPH_FD14: provided-interface=VeCANR_v_Set_Speed_KPH_FD14
      VeCANR_e_SelectSpdSts_FD14: provided-interface=VeCANR_e_SelectSpdSts_FD14
      VeCANR_b_Set_Speed_MPH_TO: provided-interface=VeCANR_b_Set_Speed_MPH_TO
      VeCANR_b_Set_Speed_KPH_FD14TO: provided-interface=VeCANR_b_Set_Speed_KPH_FD14TO
      VeCANR_b_SelectSpdSts_FD14TO: provided-interface=VeCANR_b_SelectSpdSts_FD14TO
      VeCANR_b_PrpnSystemActive_FD14TO: provided-interface=VeCANR_b_PrpnSystemActive_FD14TO
      VeCANR_b_PrpnSystemActive_FD14: provided-interface=VeCANR_b_PrpnSystemActive_FD14
      VeCANR_b_MsgCtr_ADAS_FD_HMIFD14TO: provided-interface=VeCANR_b_MsgCtr_ADAS_FD_HMIFD14TO
      VeCANR_b_CRC_ADAS_FD_HMI_FD14TO: provided-interface=VeCANR_b_CRC_ADAS_FD_HMI_FD14TO
    37 x require port:
      SendCANR_SpeedLimitSts_FD14Vld: required-interface=SendCANR_SpeedLimitSts_FD14Vld
      SendCANR_MntncSts_FD3Vld: required-interface=SendCANR_MntncSts_FD3Vld
      SendCANR_MntncSts_FD3: required-interface=SendCANR_MntncSts_FD3
      SendCANR_MinEngSpdCap_FD3Vld: required-interface=SendCANR_MinEngSpdCap_FD3Vld
      SendCANR_MinEngSpdCap_FD3: required-interface=SendCANR_MinEngSpdCap_FD3
      SendCANR_MdsActforANC_FD3Vld: required-interface=SendCANR_MdsActforANC_FD3Vld
      SendCANR_MdsActforANC_FD3: required-interface=SendCANR_MdsActforANC_FD3
      SendCANR_MdsAct_FD3Vld: required-interface=SendCANR_MdsAct_FD3Vld
      SendCANR_MdsAct_FD3: required-interface=SendCANR_MdsAct_FD3
      SendCANR_MC_OBDCONTENTFRAME_FD3Vld: required-interface=SendCANR_MC_OBDCONTENTFRAME_FD3Vld
      SendCANR_MC_OBDCONTENTFRAME_FD3: required-interface=SendCANR_MC_OBDCONTENTFRAME_FD3
      SendCANR_MC_ENGINE_HYBD_FD_4FD3Vld: required-interface=SendCANR_MC_ENGINE_HYBD_FD_4FD3Vld
      SendCANR_MC_ENGINE_HYBD_FD_4FD3: required-interface=SendCANR_MC_ENGINE_HYBD_FD_4FD3
      SendCANR_MC_ENGINE_HYBD_FD_3FD3Vld: required-interface=SendCANR_MC_ENGINE_HYBD_FD_3FD3Vld
      SendCANR_MC_ENGINE_HYBD_FD_3FD3: required-interface=SendCANR_MC_ENGINE_HYBD_FD_3FD3
      SendCANR_MC_ENG8_FD3Vld: required-interface=SendCANR_MC_ENG8_FD3Vld
      SendCANR_MC_ENG8_FD3: required-interface=SendCANR_MC_ENG8_FD3
      SendCANR_MC_ENG7_FD3Vld: required-interface=SendCANR_MC_ENG7_FD3Vld
      SendCANR_MC_ENG7_FD3: required-interface=SendCANR_MC_ENG7_FD3
      SendCANR_MC_ENG6_FD3Vld: required-interface=SendCANR_MC_ENG6_FD3Vld
      SendCANR_MC_ENG6_FD3: required-interface=SendCANR_MC_ENG6_FD3
      SendCANR_MC_ENG3_FD3Vld: required-interface=SendCANR_MC_ENG3_FD3Vld
      SendCANR_MC_ENG3_FD3: required-interface=SendCANR_MC_ENG3_FD3
      SendCANR_MC_ENG1_FD3Vld: required-interface=SendCANR_MC_ENG1_FD3Vld
      SendCANR_MC_ENG1_FD3: required-interface=SendCANR_MC_ENG1_FD3
      SendCANR_MaxEngSpdCap_FD3Vld: required-interface=SendCANR_MaxEngSpdCap_FD3Vld
      SendCANR_MaxEngSpdCap_FD3: required-interface=SendCANR_MaxEngSpdCap_FD3
      SendCANR_MAP_4_BAR_FD3: required-interface=SendCANR_MAP_4_BAR_FD3
      SendCANR_Man_PFW_Timer_FD3Vld: required-interface=SendCANR_Man_PFW_Timer_FD3Vld
      SendCANR_Man_PFW_Timer_FD3: required-interface=SendCANR_Man_PFW_Timer_FD3
      SendCANR_Man_PFW_Stat_FD3Vld: required-interface=SendCANR_Man_PFW_Stat_FD3Vld
      SendCANR_Man_PFW_Stat_FD3: required-interface=SendCANR_Man_PFW_Stat_FD3
      SendCANR_ECM_THA_Resp_FD14Vld: required-interface=SendCANR_ECM_THA_Resp_FD14Vld
      SendCANR_ECM_THA_Resp_FD14: required-interface=SendCANR_ECM_THA_Resp_FD14
      SendCANR_DrvAway_IndicationsFD3Vld: required-interface=SendCANR_DrvAway_IndicationsFD3Vld
      SendCANR_DrvAway_IndicationsFD3: required-interface=SendCANR_DrvAway_IndicationsFD3
      SendCANR_MAP_4_BAR_FD3Vld: required-interface=SendCANR_MAP_4_BAR_FD3Vld
    71 x provide port:
      VeLWRR_R_WRO2_CellResistUsBnk2: provided-interface=VeLWRR_R_WRO2_CellResistUsBnk2
      VeDIOR_b_BrkSwDigInpFiltdVal: variation-point={short-label=VP_VeDIOR_b_BrkSwDigInpFiltdVal_T4EVO, sw-syscond=( /RB/PT/Common/SwSystemconsts/Adjustables/PSSC009T4EVO_SC == 1)}, provided-interface=VeDIOR_b_DigInpFiltdVal
      VeDIOR_b_BrkSwDigInpImdtVal: variation-point={short-label=VP_VeDIOR_b_BrkSwDigInpImdtVal_T4EVO, sw-syscond=( /RB/PT/Common/SwSystemconsts/Adjustables/PSSC009T4EVO_SC == 1)}, provided-interface=VeDIOR_b_DigInpImdtVal
      VeDIOR_b_IgnRunStrtSwDigInpFiltdVal: provided-interface=VeDIOR_b_DigInpFiltdVal
      VeDIOR_b_DynoFuDsblReqSwDigInpImdtVal: variation-point={short-label=VP_VeDIOR_b_DynoFuDsblReqSwDigInpImdtVal_T4EVO, sw-syscond=( /RB/PT/Common/SwSystemconsts/Adjustables/PSSC009T4EVO_SC == 1)}, provided-interface=VeDIOR_b_DigInpImdtVal
      VeDIOR_b_DynoFuDsblReqSwDigInpFiltdVal: variation-point={short-label=VP_VeDIOR_b_DynoFuDsblReqSwDigInpFiltdVal_T4EVO, sw-syscond=( /RB/PT/Common/SwSystemconsts/Adjustables/PSSC009T4EVO_SC == 1)}, provided-interface=VeDIOR_b_DigInpFiltdVal
      VeDIOR_b_IgnRunStrtSwDigInpImdtVal: provided-interface=VeDIOR_b_DigInpImdtVal
      VeDIOR_b_NVLD_SwDigInpFiltdVal: provided-interface=VeDIOR_b_DigInpFiltdVal
      VeDIOR_b_NVLD_SwDigInpImdtVal: provided-interface=VeDIOR_b_DigInpImdtVal
      VeDIOR_b_StrtrRlyFbDigInpFiltdVal: provided-interface=VeDIOR_b_DigInpFiltdVal
      VeDIOR_b_StrtrRlyFbDigInpImdtVal: provided-interface=VeDIOR_b_DigInpImdtVal
      VeDIOR_b_ECM_WakeUpDigInpFiltdVal: provided-interface=VeDIOR_b_DigInpFiltdVal
      VeDIOR_b_ECM_WakeUpDigInpImdtVal: provided-interface=VeDIOR_b_DigInpImdtVal
      SetDIOR_b_AC_CluRlyOutpSt: provided-interface=IFIoHwAbDigOutpSetSt
      SetDIOR_b_DMTLLkPmpOutpSt: variation-point={short-label=VP_SetDIOR_b_DMTLLkPmpOutpSt_T4EVO, sw-syscond=( /RB/PT/Common/SwSystemconsts/Adjustables/PSSC009T4EVO_SC == 1)}, provided-interface=IFIoHwAbDigOutpSetSt
      SetDIOR_b_InrushCircRlyOutpSt: provided-interface=IFIoHwAbDigOutpSetSt
      SetDIOR_b_LoPresFuPmpRlyOutpSt: provided-interface=IFIoHwAbDigOutpSetSt
      SetDIOR_b_MakeUpAirVlvOutpSt: provided-interface=IFIoHwAbDigOutpSetSt
      SetDIOR_b_OBD_PurgVentVlvOutpSt: provided-interface=IFIoHwAbDigOutpSetSt
      SetDIOR_b_SrgSoln1OutpSt: provided-interface=IFIoHwAbDigOutpSetSt
      SetDIOR_b_StrtrRlyOutpSt: provided-interface=IFIoHwAbDigOutpSetSt
      SetDIOR_b_SwilEngMnt1OutpSt: provided-interface=IFIoHwAbDigOutpSetSt
      SetDIOR_b_SwilEngMnt2OutpSt: provided-interface=IFIoHwAbDigOutpSetSt
      SetDIOR_b_RadrFanRlyHiSpdOutpSt: variation-point={short-label=VP_SetDIOR_b_RadrFanRlyHiSpdOutpSt_T4EVO, sw-syscond=( /RB/PT/Common/SwSystemconsts/Adjustables/PSSC009T4EVO_SC == 1)}, provided-interface=IFIoHwAbDigOutpSetSt
      VeDIOR_e_SrgSoln1IndDiagInfo: provided-interface=IFIoHwAbDigOutpDiagInfo
      VeDIOR_e_OBD_PurgVentVlvIndDiagInfo: provided-interface=IFIoHwAbDigOutpDiagInfo
      VeDIOR_e_AC_CluRlyIndDiagInfo: provided-interface=IFIoHwAbDigOutpDiagInfo
      VeDIOR_e_LoPresFuPmpRlyIndDiagInfo: provided-interface=IFIoHwAbDigOutpDiagInfo
      VeDIOR_e_MakeUpAirVlvIndDiagInfo: provided-interface=IFIoHwAbDigOutpDiagInfo
      VeDIOR_e_SwilEngMnt1IndDiagInfo: provided-interface=IFIoHwAbDigOutpDiagInfo
      VeDIOR_e_RadrFanRlyHiSpdIndDiagInfo: provided-interface=IFIoHwAbDigOutpDiagInfo
      VeDIOR_e_StrtrRlyIndDiagInfo: provided-interface=IFIoHwAbDigOutpDiagInfo
      VeDIOR_e_InrushCircRlyIndDiagInfo: provided-interface=IFIoHwAbDigOutpDiagInfo
      VeDIOR_SrgSoln1HwDiagCmn: provided-interface=IFHwDiagCmn
      VeDIOR_OBD_PurgVentVlvHwDiagCmn: provided-interface=IFHwDiagCmn
      VeDIOR_AC_CluRlyHwDiagCmn: provided-interface=IFHwDiagCmn
      VeDIOR_LoPresFuPmpRlyHwDiagCmn: provided-interface=IFHwDiagCmn
      VeDIOR_SwilEngMnt1HwDiagCmn: provided-interface=IFHwDiagCmn
      VeDIOR_RadrFanRlyHiSpdHwDiagCmn: provided-interface=IFHwDiagCmn
      VeDIOR_StrtrRlyHwDiagCmn: provided-interface=IFHwDiagCmn
      VeDIOR_InrushCircRlyHwDiagCmn: provided-interface=IFHwDiagCmn
      VeDIOR_SrgSoln1HwDiagFltCircDtctd: provided-interface=IFHwDiagFltCirc
      VeDIOR_OBD_PurgVentVlvHwDiagFltCircDtctd: provided-interface=IFHwDiagFltCirc
      VeDIOR_AC_CluRlyHwDiagFltCircDtctd: provided-interface=IFHwDiagFltCirc
      VeDIOR_LoPresFuPmpRlyHwDiagFltCircDtctd: provided-interface=IFHwDiagFltCirc
      VeDIOR_SwilEngMnt1HwDiagFltCircDtctd: provided-interface=IFHwDiagFltCirc
      VeDIOR_RadrFanRlyHiSpdHwDiagFltCircDtctd: provided-interface=IFHwDiagFltCirc
      VeDIOR_StrtrRlyHwDiagFltCircDtctd: provided-interface=IFHwDiagFltCirc
      VeDIOR_InrushCircRlyHwDiagFltCircDtctd: provided-interface=IFHwDiagFltCirc
      VeDIOR_SrgSoln1HwDiagFltOutp: provided-interface=IFHwDiagFltOutp
      VeDIOR_OBD_PurgVentVlvHwDiagFltOutp: provided-interface=IFHwDiagFltOutp
      VeDIOR_AC_CluRlyHwDiagFltOutp: provided-interface=IFHwDiagFltOutp
      VeDIOR_LoPresFuPmpRlyHwDiagFltOutp: provided-interface=IFHwDiagFltOutp
      VeDIOR_SwilEngMnt1HwDiagFltOutp: provided-interface=IFHwDiagFltOutp
      VeDIOR_RadrFanRlyHiSpdHwDiagFltOutp: provided-interface=IFHwDiagFltOutp
      VeDIOR_StrtrRlyHwDiagFltOutp: provided-interface=IFHwDiagFltOutp
      VeDIOR_InrushCircRlyHwDiagFltOutp: provided-interface=IFHwDiagFltOutp
      ServDIOR_Hbrdg_Coold_EGR: provided-interface=IFIoHwAbHBrdgServ
      ServDIOR_Hbrdg_DP: provided-interface=IFIoHwAbHBrdgServ
      ServDIOR_Hbrdg_ETC_Motor: provided-interface=IFIoHwAbHBrdgServ
      ServDIOR_Hbrdg_Wg1: provided-interface=IFIoHwAbHBrdgServ
      VeDIOR_h_Hbrdg_Coold_EGR_Sts: provided-interface=IFIoHwAbHBrdgSts
      VeDIOR_h_Hbrdg_DP_Sts: provided-interface=IFIoHwAbHBrdgSts
      VeDIOR_h_Hbrdg_ETC_Motor_Sts: provided-interface=IFIoHwAbHBrdgSts
      VeDIOR_h_Hbrdg_Wg1_Sts: provided-interface=IFIoHwAbHBrdgSts
      VeDIOR_b_Hbrdg_Coold_EGR_DiagFltCircDtctd: provided-interface=IFHwDiagFltCirc
      VeDIOR_b_Hbrdg_ETC_Motor_DiagFltCircDtctd: provided-interface=IFHwDiagFltCirc
      VeDIOR_b_Hbrdg_DP_DiagFltCircDtctd: provided-interface=IFHwDiagFltCirc
      VeDIOR_b_Hbrdg_Wg1_DiagFltCircDtctd: provided-interface=IFHwDiagFltCirc
      VeSPLR_b_BattBackedRAM_Init: provided-interface=VeSPLR_b_BattBackedRAM_Init
      VeDEVR_b_DevlpmtToolEnbld: provided-interface=VeDEVR_b_DevlpmtToolEnbld
    require port VeFPCR_p_AbsValFiltd: required-interface=VeFPCR_p_AbsValFiltd
    require port VeMAPR_p_IntkMnfdPres: required-interface=VeMAPR_p_IntkMnfdPres
    40 x provide port:
      VeDIOR_h_FPCMFb1_PwmInp: provided-interface=VeDIOR_h_PwmInp
      VeDIOR_b_FPCM_Fb1_PWM_Inp_TO_Sts: provided-interface=VeDIOR_b_PwmInp_TiOutSts
      VeDIOR_Pct_FPCM_Fb1_PWM_Inp_DC: provided-interface=VeDIOR_Pct_PwmInp_DC
      VeDIOR_e_ElecPhsrMtrCmdOutpIndDiagInfo: variation-point={short-label=VP_VeDIOR_e_ElecPhsrMtrCmdOutpIndDiagInfo_T4EVO, sw-syscond=( /RB/PT/Common/SwSystemconsts/Adjustables/PSSC009T4EVO_SC == 1)}, provided-interface=IFIoHwAbPwmOutpDiagInfo
      SetDIOR_e_ElecPhsrMtrCmdOutpOutpOps: variation-point={short-label=VP_SetDIOR_e_ElecPhsrMtrCmdOutpOutpOps_T4EVO, sw-syscond=( /RB/PT/Common/SwSystemconsts/Adjustables/PSSC009T4EVO_SC == 1)}, provided-interface=IFIoHwAbPWMOutpSet
      VeDIOR_e_FuPmpCtlMdulCmdIndDiagInfo: provided-interface=IFIoHwAbPwmOutpDiagInfo
      SetDIOR_e_FuPmpCtlMdulCmdOutpOps: provided-interface=IFIoHwAbPWMOutpSet
      SetDIOR_e_PurgSolnOutpOps: provided-interface=IFIoHwAbPWMOutpSet
      VeDIOR_e_PurgSolnIndDiagInfo: provided-interface=IFIoHwAbPwmOutpDiagInfo
      SetDIOR_e_RadrFanCtrlPwmOutpOps: provided-interface=IFIoHwAbPWMOutpSet
      VeDIOR_e_RadrFanCtrlPwmIndDiagInfo: provided-interface=IFIoHwAbPwmOutpDiagInfo
      SetDIOR_e_VvtExh1OutpOps: provided-interface=IFIoHwAbPWMOutpSet
      VeDIOR_e_VvtExh1IndDiagInfo: provided-interface=IFIoHwAbPwmOutpDiagInfo
      SetDIOR_e_VarOilSolnOutpOps: provided-interface=IFIoHwAbPWMOutpSet
      VeDIOR_e_VarOilSolnIndDiagInfo: provided-interface=IFIoHwAbPwmOutpDiagInfo
      VeDIOR_PurgSoln_HwDiagFltOutp: provided-interface=IFHwDiagFltOutp
      VeDIOR_RadrFanCtrlPwm_HwDiagFltOutp: provided-interface=IFHwDiagFltOutp
      VeDIOR_VarOilSoln_HwDiagFltOutp: provided-interface=IFHwDiagFltOutp
      VeDIOR_VvtExh1_HwDiagFltOutp: provided-interface=IFHwDiagFltOutp
      VeDIOR_ElecPhsrMtrCmd_HwDiagFltOutp: variation-point={short-label=VP_VeDIOR_ElecPhsrMtrCmd_HwDiagFltOutp_T4EVO, sw-syscond=( /RB/PT/Common/SwSystemconsts/Adjustables/PSSC009T4EVO_SC == 1)}, provided-interface=IFHwDiagFltOutp
      VeDIOR_PurgSoln_HwDiagCmn: provided-interface=IFHwDiagCmn
      VeDIOR_RadrFanCtrlPwm_HwDiagCmn: provided-interface=IFHwDiagCmn
      VeDIOR_VarOilSoln_HwDiagCmn: provided-interface=IFHwDiagCmn
      VeDIOR_VvtExh1_HwDiagCmn: provided-interface=IFHwDiagCmn
      VeDIOR_ElecPhsrMtrCmd_HwDiagCmn: variation-point={short-label=VP_VeDIOR_ElecPhsrMtrCmd_HwDiagCmn_T4EVO, sw-syscond=( /RB/PT/Common/SwSystemconsts/Adjustables/PSSC009T4EVO_SC == 1)}, provided-interface=IFHwDiagCmn
      VeDIOR_ElecPhsrMtrCmd_HwDiagFltCircDtctd: variation-point={short-label=VP_VeDIOR_ElecPhsrMtrCmd_HwDiagFltCircDtctd_T4EVO, sw-syscond=( /RB/PT/Common/SwSystemconsts/Adjustables/PSSC009T4EVO_SC == 1)}, provided-interface=IFHwDiagFltCirc
      VeDIOR_FuPmpCtlMdulCmd_HwDiagFltCircDtctd: provided-interface=IFHwDiagFltCirc
      VeDIOR_PurgSoln_HwDiagFltCircDtctd: provided-interface=IFHwDiagFltCirc
      VeDIOR_RadrFanCtrlPwm_HwDiagFltCircDtctd: provided-interface=IFHwDiagFltCirc
      VeDIOR_VarOilSoln_HwDiagFltCircDtctd: provided-interface=IFHwDiagFltCirc
      VeDIOR_VvtExh1_HwDiagFltCircDtctd: provided-interface=IFHwDiagFltCirc
      VeDIOR_FuPmpCtlMdulCmd_HwDiagFltOutp: provided-interface=IFHwDiagFltOutp
      VeDIOR_FuPmpCtlMdulCmd_HwDiagCmn: provided-interface=IFHwDiagCmn
      VeSPLR_b_BattDiscnctSts: provided-interface=VeSPLR_b_BattDiscnctSts
      VeSPLR_g_PwrSplyInfo: provided-interface=VeSPLR_g_PwrSplyInfo
      VeSPLR_b_PwrSplyDiagInfo: provided-interface=VeSPLR_b_PwrSplyDiagInfo
      PwrSplyOps: provided-interface=IFPwrSplyOps
      GetSNTR_e_DP_VlvPosnSns: provided-interface=GetSNTR_MsgData
      GetSNTR_e_MAF_Hum_Snsr: provided-interface=GetSNTR_MsgData
      GetSNTR_e_EGRCoolr_DeltAbsPresSnsr: provided-interface=GetSNTR_MsgData
    require port KeCFGR_b_MAF_Hum_SnsrEquid: required-interface=IO_ChEquid
    require port KeCFGR_b_EGRCoolr_DeltAbsPresSnsrEquid: required-interface=IO_ChEquid
    require port KeCFGR_b_DP_VlvPosnSnsChEquid: required-interface=IO_ChEquid
    16 x provide port:
      VeRPMR_b_EngStopd: provided-interface=VeRPMR_b_EngStopd
      VeEPSR_Cnt_PreMidEPP_Eve: provided-interface=VeEPSR_Cnt_PreMidEPP_Eve
      VeEPSR_Cnt_NewBurstAvailEve: provided-interface=VeEPSR_Cnt_NewBurstAvailEve
      VeRPMR_b_PrimSpdSnsrFailr: provided-interface=VeRPMR_b_SpdSnsrFailr
      VeRPMR_b_SecdSpdSnsrFailr: provided-interface=VeRPMR_b_SpdSnsrFailr
      VeEPSR_Cnt_SyncnLostEve: provided-interface=VeEPSR_Cnt_SyncnLostEve
      GetCRKR_Cnt_CamBurstCnt: provided-interface=GetCRKR_Cnt_CamBurstCnt
      GetEPSR_i_FgSeqOfCyl: provided-interface=GetEPSR_i_FgSeqOfCyl
      GetEPSR_i_PrevCyl: provided-interface=GetEPSR_i_PrevCyl
      GetRPMR_b_EngStopd: provided-interface=GetRPMR_b_EngStopd
      GetRPMR_b_EngStrtThdExcdd: provided-interface=GetRPMR_b_EngStrtThdExcdd
      GetCAMR_e_Exh1CamSt: provided-interface=IFCamPosnEtpuIfCS_GetSt
      VeCAMR_b_ElecPhsrDirIntk1: provided-interface=VeCAMR_b_ElecPhsrDir
      VeCAMR_cnt_ElecPhsrFbTotDstIntk1: provided-interface=VeCAMR_cnt_ElecPhsrFbTotDst
      VeCAMR_t_ElecPhsrFbMeasFrqIntk1: provided-interface=VeCAMR_t_ElecPhsrFbMeasFrq
      VeINJR_b_RelsCond_CVO_BasAdpn: provided-interface=VeINJR_b_RelsCond_CVO_BasAdpn
    require port VeINJR_b_RelsCL_Ctrl: required-interface=VeINJR_b_RelsCL_Ctrl
    require port VeINJR_b_Rels_CVO_BasAdpn: required-interface=VeINJR_b_Rels_CVO_BasAdpn
    14 x provide port:
      VeLWRR_b_WRO2_RdyUsBnk1: provided-interface=VeLWRR_b_WRO2_RdyUsBnk1
      VeLWRR_b_WRO2_RdyUsBnk2: provided-interface=VeLWRR_b_WRO2_RdyUsBnk2
      VeOXSR_U_FiltdOutpVoltDsBnk1: provided-interface=VeOXSR_U_FiltdOutpVoltDsBnk1
      VeOXSR_U_FiltdOutpVoltDsBnk2: provided-interface=VeOXSR_U_FiltdOutpVoltDsBnk2
      VeOXSR_U_OutpVoltDsBnk1: provided-interface=VeOXSR_U_OutpVoltDsBnk1
      VeOXSR_U_OutpVoltDsBnk2: provided-interface=VeOXSR_U_OutpVoltDsBnk2
      VeOXSR_b_RdngRdyDsBnk1: provided-interface=VeOXSR_b_RdngRdyDsBnk1
      VeOXSR_b_RdngRdyDsBnk2: provided-interface=VeOXSR_b_RdngRdyDsBnk2
      VeOXTR_T_DsBnk1Temp: provided-interface=VeOXTR_T_DsBnk1Temp
      VeOXTR_T_DsBnk2Temp: provided-interface=VeOXTR_T_DsBnk2Temp
      VeOXTR_T_UsBnk1Temp: provided-interface=VeOXTR_T_UsBnk1Temp
      VeOXTR_T_UsBnk2Temp: provided-interface=VeOXTR_T_UsBnk2Temp
      VeWRSR_b_ResistCalcnVldUsBnk1: provided-interface=VeWRSR_b_ResistCalcnVldUsBnk1
      VeWRSR_b_ResistCalcnVldUsBnk2: provided-interface=VeWRSR_b_ResistCalcnVldUsBnk2
    12 x require port:
      VeBARR_p_Baro: required-interface=VeBARR_p_Baro
      VeCATR_T_CatTempBnk1: required-interface=VeCATR_T_CatTempBnk1
      VeCATR_T_CatTempBnk2: required-interface=VeCATR_T_CatTempBnk2
      VeEEQR_r_ExhPhiTarBnk1: required-interface=VeEEQR_r_ExhPhiTarBnk1
      VeEXHR_T_UsCatTempBnk1: required-interface=VeEXHR_T_UsCatTempBnk1
      VeEXHR_T_UsCatTempBnk2: required-interface=VeEXHR_T_UsCatTempBnk2
      VeEXHR_dm_ExhMassFlowBnk1: required-interface=VeEXHR_dm_ExhMassFlowBnk1
      VeEXHR_dm_ExhMassFlowBnk2: required-interface=VeEXHR_dm_ExhMassFlowBnk2
      VeEXHR_dm_UsCatMassFlowBnk1: required-interface=VeEXHR_dm_UsCatMassFlowBnk1
      VeFSOR_b_EngInFullFSO: required-interface=VeFSOR_b_EngInFullFSO
      VeSPDR_b_EngSpdCtrlIsActv: required-interface=VeSPDR_b_EngSpdCtrlIsActv
      VeEXHR_dm_UsCatMassFlowBnk2: required-interface=VeEXHR_dm_UsCatMassFlowBnk2
    19 x provide port:
      KeCRKR_b_BidrnlPosnSnsrEquid: parameter-provide-com-spec{init-value=KeCRKR_b_BidrnlPosnSnsrEquid_KeCRKR_b_BidrnlPosnSnsrEquid:0, parameter=KeCRKR_b_BidrnlPosnSnsrEquid}, provided-interface=KeCRKR_b_BidrnlPosnSnsrEquid
      VeDIOR_h_AllGrPosnSnsr1_PwmInp: provided-interface=VeDIOR_h_PwmInp
      VeDIOR_h_AllGrPosnSnsr2_PwmInp: provided-interface=VeDIOR_h_PwmInp
      VeDIOR_Pct_AllGrPosnSnsr1_PWM_Inp_DC: provided-interface=VeDIOR_Pct_PwmInp_DC
      VeDIOR_Pct_AllGrPosnSnsr2_PWM_Inp_DC: provided-interface=VeDIOR_Pct_PwmInp_DC
      VeDIOR_b_AllGrPosnSnsr1_PWM_Inp_TO_Sts: provided-interface=VeDIOR_b_PwmInp_TiOutSts
      VeDIOR_b_AllGrPosnSnsr2_PWM_Inp_TO_Sts: provided-interface=VeDIOR_b_PwmInp_TiOutSts
      VeCAMR_t_CamTiInSpdWinExh1: provided-interface=VeCAMR_t_CamTiInSpdWin
      VeCAMR_t_CamTiInSpdWinIntk1: provided-interface=VeCAMR_t_CamTiInSpdWin
      VeRPMR_b_SpdSnsrCohrncyFailr: provided-interface=VeRPMR_b_SpdSnsrFailr
      VeRPMR_b_CrksftSpdSnsrCohrncy: provided-interface=SpdSnsrCohrncy
      VeRPMR_b_Exh1CamSpdSnsrCohrncy: provided-interface=SpdSnsrCohrncy
      VeRPMR_b_Intk1CamSpdSnsrCohrncy: provided-interface=SpdSnsrCohrncy
      VeRPMR_e_EngSpdChkSts: provided-interface=VeRPMR_e_EngSpdChkSts
      VeRPMR_e_PrimSecdSpdSnsrSts: provided-interface=VeRPMR_e_PrimSecdSpdSnsrSts
      VeDIOR_SwilEngMnt2_HwDiagCmn: provided-interface=IFHwDiagCmn
      VeDIOR_SwilEngMnt2_HwDiagFltCircDtctd: provided-interface=IFHwDiagFltCirc
      VeDIOR_SwilEngMnt2_HwDiagFltOutp: provided-interface=IFHwDiagFltOutp
      GetCRKR_b_CrksftUnlckdInRun: provided-interface=GetCRKR_b_CrksftUnlckdInRun
    48 x require port:
      KeCFGR_b_WgPosn1AdcInpEquid: required-interface=IO_ChEquid
      KeCFGR_b_AirCdngPSnsrAdcInpEquid: required-interface=IO_ChEquid
      KeCFGR_b_CcoldCrkCasePSnsrAdcInpEquid: required-interface=IO_ChEquid
      KeCFGR_b_CrkBattMonrAdcInpEquid: required-interface=IO_ChEquid
      KeCFGR_b_EngCooltTAdcInpEquid: required-interface=IO_ChEquid
      KeCFGR_b_FuTankPSnsrAdcInpEquid: required-interface=IO_ChEquid
      KeCFGR_b_GdiFuRailP1AdcInpEquid: required-interface=IO_ChEquid
      KeCFGR_b_VarGeomTrbFbAdcInpEquid: required-interface=IO_ChEquid
      KeCFGR_b_HoodAjarAdcInpEquid: required-interface=IO_ChEquid
      KeCFGR_b_IntkAirTAdcInpEquid: variation-point={short-label=VP_KeCFGR_b_IntkAirTAdcInpEquid_T4EVO, sw-syscond=( /RB/PT/Common/SwSystemconsts/Adjustables/PSSC009T4EVO_SC == 1)}, required-interface=IO_ChEquid
      KeCFGR_b_LoPFuSnsrAdcInpEquid: required-interface=IO_ChEquid
      KeCFGR_b_CooltInletTempAdcInpEquid: required-interface=IO_ChEquid
      KeCFGR_b_MnfldAirPAdcInpEquid: required-interface=IO_ChEquid
      KeCFGR_b_EngSwtBattAdcInpEquid: required-interface=IO_ChEquid
      KeCFGR_b_MnfldGasTAdcInpEquid: variation-point={short-label=VP_KeCFGR_b_MnfldGasTAdcInpEquid_T4EVO, sw-syscond=( /RB/PT/Common/SwSystemconsts/Adjustables/PSSC009T4EVO_SC == 1)}, required-interface=IO_ChEquid
      KeCFGR_b_BrkPdlPosnSnsrAdcInpEquid: variation-point={short-label=VP_KeCFGR_b_BrkPdlPosnSnsrAdcInpEquid_T4EVO, sw-syscond=( /RB/PT/Common/SwSystemconsts/Adjustables/PSSC009T4EVO_SC == 1)}, required-interface=IO_ChEquid
      KeCFGR_b_OilPSnsrAdcInpEquid: required-interface=IO_ChEquid
      KeCFGR_b_OilTSnsrAdcInpEquid: required-interface=IO_ChEquid
      KeCFGR_b_PedlValSnsr1AdcInpEquid: required-interface=IO_ChEquid
      KeCFGR_b_SysU12VoltAdcInpEquid: required-interface=IO_ChEquid
      KeCFGR_b_PedlValSnsr2AdcInpEquid: required-interface=IO_ChEquid
      KeCFGR_b_ThrIntkGasTAdcInpEquid: required-interface=IO_ChEquid
      KeCFGR_b_ThrIntkPAdcInpEquid: required-interface=IO_ChEquid
      KeCFGR_b_ThrPosnSnsr1AdcInpEquid: required-interface=IO_ChEquid
      KeCFGR_b_ThrPosnSnsr2AdcInpEquid: required-interface=IO_ChEquid
      KeCFGR_b_CoolInletTempAdcInpEquid: required-interface=IO_ChEquid
      KeCFGR_b_CalInp2AdcInpEquid: required-interface=IO_ChEquid
      KeCFGR_b_CalInp1AdcInpEquid: required-interface=IO_ChEquid
      KeCFGR_b_Coolt3WayVlvAdcInpEquid: required-interface=IO_ChEquid
      KeCFGR_b_PFIFuRailTempAdcInpEquid: required-interface=IO_ChEquid
      KeCFGR_b_PFIFuRailPressAdcInpEquid: required-interface=IO_ChEquid
      KeCFGR_b_CluSnsAdcInpEquid: required-interface=IO_ChEquid
      KeCFGR_b_OilShutOffValveFbAdcInpEquid: required-interface=IO_ChEquid
      KeCFGR_b_BrkSwDigInpEquid: variation-point={short-label=VP_KeCFGR_b_BrkSwDigInpEquid_T4EVO, sw-syscond=( /RB/PT/Common/SwSystemconsts/Adjustables/PSSC009T4EVO_SC == 1)}, required-interface=IO_ChEquid
      KeCFGR_b_IgnRunStrtDigInpEquid: required-interface=IO_ChEquid
      KeCFGR_b_NVLDDigInpEquid: required-interface=IO_ChEquid
      KeCFGR_b_StrtrRlyFbDigInpEquid: required-interface=IO_ChEquid
      KeCFGR_b_ECM_WakeUpDigInpEquid: required-interface=IO_ChEquid
      KeCFGR_b_DynoFuDsblReqDigInpEquid: variation-point={short-label=VP_KeCFGR_b_DynoFuDsblReqDigInpEquid_T4EVO, sw-syscond=( /RB/PT/Common/SwSystemconsts/Adjustables/PSSC009T4EVO_SC == 1)}, required-interface=IO_ChEquid
      KeCFGR_b_CluInterLockDigInpEquid: required-interface=IO_ChEquid
      KeCFGR_b_WgHbrdgEquid: required-interface=IO_ChEquid
      KeDIOR_b_ETC_Equid: required-interface=IO_ChEquid
      KeDIOR_b_Coold_EGR_Equid: required-interface=IO_ChEquid
      KeDIOR_b_DP_Equid: required-interface=IO_ChEquid
      KeCFGR_b_VarGeomTrbEquid: required-interface=IO_ChEquid
      KsSNTR_h_MAF_Hum_Snsr_SENTCfg: required-interface=SENTIfCfg
      KsSNTR_h_DP_VlvPosnSns_SENTCfg: required-interface=SENTIfCfg
      KsSNTR_h_EGRCoolr_DeltAbsPresSnsr_SENTCfg: required-interface=SENTIfCfg
    14 x provide port:
      VeDIOR_t_ECM_WakeUpDigInpOffTi: provided-interface=VeDIOR_t_DigInpOffTi
      VeDIOR_b_CluInterLockSwDigInpFiltdVal: provided-interface=VeDIOR_b_DigInpFiltdVal
      VeDIOR_b_CluInterLockSwDigInpImdtVal: provided-interface=VeDIOR_b_DigInpImdtVal
      VeDIOR_t_CluInterLockSwDigInpOffTi: provided-interface=VeDIOR_t_DigInpOffTi
      VeDIOR_AlterFieCtrl_HwDiagCmn: provided-interface=IFHwDiagCmn
      SetDIOR_e_AlterFieCtrlOutpOps: provided-interface=IFIoHwAbPWMOutpSet
      VeDIOR_e_AlterFieCtrlIndDiagInfo: provided-interface=IFIoHwAbPwmOutpDiagInfo
      VeDIOR_AlterFieCtrl_HwDiagFltCircDtctd: provided-interface=IFHwDiagFltCirc
      VeDIOR_AlterFieCtrl_HwDiagFltOutp: provided-interface=IFHwDiagFltOutp
      VeDIOR_HTR_MeclWtrPmpActr_HwDiagCmn: provided-interface=IFHwDiagCmn
      SetDIOR_e_HTR_MeclWtrPmpActrOutpOps: provided-interface=IFIoHwAbPWMOutpSet
      VeDIOR_e_HTR_MeclWtrPmpActrIndDiagInfo: provided-interface=IFIoHwAbPwmOutpDiagInfo
      VeDIOR_HTR_MeclWtrPmpActr_HwDiagFltCircDtctd: provided-interface=IFHwDiagFltCirc
      VeDIOR_HTR_MeclWtrPmpActr_HwDiagFltOutp: provided-interface=IFHwDiagFltOutp
    8 x require port, all with required-interface=IO_ChEquid:
      KeCFGR_b_ElecPhsrMtrCmd_ChEquid
      KeCFGR_b_FuPmpCtlMdulCmd_ChEquid
      KeCFGR_b_PurgSoln_ChEquid
      KeCFGR_b_RadrFanCtrlPwm_ChEquid
      KeCFGR_b_VarOilSoln_ChEquid
      KeCFGR_b_VvtExh1_ChEquid
      KeCFGR_b_AlterFieCtrl_ChEquid
      KeCFGR_b_HTR_MeclWtrPmpActr_ChEquid
    provide port GetLLSR_phi_IgnAng: provided-interface=GetLLSR_phi_IgnAng
    provide port GetLLSR_b_IgnPinSts: provided-interface=GetLLSR_b_IgnPinSts
    4 x require port:
      VeACRR_Pct_PdlPosn: required-interface=VeACRR_Pct_PdlPosn
      VeSSCR_t_TotEngLifeTiRunngTmr: required-interface=VeSSCR_t_TotEngLifeTiRunngTmr
      EeODMR_l_Servid_9TotDistLifeTi: required-interface=EeODMR_l_Servid_9TotDistLifeTi
      VeODMR_l_VehOdo: required-interface=VeODMR_l_VehOdo
    135 x provide port:
      VeDIOR_b_Hbrdg_VarGeomTrb_DiagCmn: provided-interface=IFHwDiagCmn
      VeDIOR_b_Hbrdg_VarGeomTrb_DiagFltCircDftlDtctd: provided-interface=IFHwDiagFltCircDftl
      VeDIOR_b_Hbrdg_VarGeomTrb_DiagFltCircDtctd: provided-interface=IFHwDiagFltCirc
      VeDIOR_b_Hbrdg_VarGeomTrb_DiagFltOutp: provided-interface=IFHwDiagFltOutp
      VeDIOR_h_Hbrdg_VarGeomTrb_Sts: provided-interface=IFIoHwAbHBrdgSts
      ServDIOR_Hbrdg_VarGeomTrb: provided-interface=IFIoHwAbHBrdgServ
      Pp_BasSvrApl_stCarShpConf: provided-interface=BasSvrApl_stCarShpConf
      Pp_BasSvrAppl_AutonomyLvl: provided-interface=BasSvrAppl_AutonomyLvl
      Pp_BasSvrAppl_CrsCtlLogic: provided-interface=BasSvrAppl_CrsCtlLogic
      Pp_BasSvrAppl_lTire: provided-interface=BasSvrAppl_lTire
      Pp_BasSvrAppl_st4LoBtn: provided-interface=BasSvrAppl_st4LoBtn
      Pp_BasSvrAppl_stAdapCrCtl: provided-interface=BasSvrAppl_stAdaptCtrl
      Pp_BasSvrAppl_stAdvdDrvrProgBtn: provided-interface=BasSvrAppl_stAdvdDrvrProgBtn
      Pp_BasSvrAppl_stAntiInclSens: provided-interface=BasSvrAppl_stAntiInclSens
      Pp_BasSvrAppl_stASCMPrsnt: provided-interface=BasSvrAppl_stASCMPrsnt
      Pp_BasSvrAppl_stAxlRat: provided-interface=BasSvrAppl_stAxlRat
      Pp_BasSvrAppl_stbsm_fnct_1hdc: provided-interface=BasSvrAppl_stbsm_fnct_1hdc
      Pp_BasSvrAppl_stCANNod0Pres: provided-interface=BasSvrAppl_stCANNode0Pres
      Pp_BasSvrAppl_stCANNode10Pres: provided-interface=BasSvrAppl_stCANNode10Pres
      Pp_BasSvrAppl_stCANNode11Pres: provided-interface=BasSvrAppl_stCANNode11Pres
      Pp_BasSvrAppl_stCANNode124Pres: provided-interface=BasSvrAppl_stCANNode124Pres
      Pp_BasSvrAppl_stCANNode13Pres: provided-interface=BasSvrAppl_stCANNode13Pres
      Pp_BasSvrAppl_stCANNode1Pres: provided-interface=BasSvrAppl_stCANNode1Pres
      Pp_BasSvrAppl_stCANNode22Pres: provided-interface=BasSvrAppl_stCANNode22Pres
      Pp_BasSvrAppl_stCANNode26Pres: provided-interface=BasSvrAppl_stCANNode26Pres
      Pp_BasSvrAppl_stCANNode2Pres: provided-interface=BasSvrAppl_stCANNode2Pres
      Pp_BasSvrAppl_stCANNode3Pres: provided-interface=BasSvrAppl_stCANNode3Pres
      Pp_BasSvrAppl_stCANNode53Pres: provided-interface=BasSvrAppl_stCANNode53Pres
      Pp_BasSvrAppl_stCANNode57Pres: provided-interface=BasSvrAppl_stCANNode57Pres
      Pp_BasSvrAppl_stCANNode65Pres: provided-interface=BasSvrAppl_stCANNode65Pres
      Pp_BasSvrAppl_stCANNode6Pres: provided-interface=BasSvrAppl_stCANNode6Pres
      Pp_BasSvrAppl_stClimateTyp: provided-interface=BasSvrAppl_stClimateTyp
      Pp_BasSvrAppl_stCrCtlPres: provided-interface=BasSvrAppl_stCrCtlPres
      Pp_BasSvrAppl_stCtyCode: provided-interface=BasSvrAppl_stCtyCode
      Pp_BasSvrAppl_stDriverSide: provided-interface=BasSvrAppl_stDriverSide
      Pp_BasSvrAppl_stDrvModes: provided-interface=BasSvrAppl_stDrvModes
      Pp_BasSvrAppl_stDrvStyleSel: provided-interface=BasSvrAppl_stDrvStyleSel
      Pp_BasSvrAppl_stDTCMPrsnt: provided-interface=BasSvrAppl_stDTCMPrsnt
      Pp_BasSvrAppl_stEngType: provided-interface=BasSvrAppl_stEngType
      Pp_BasSvrAppl_stEOLNode0Pres: provided-interface=BasSvrAppl_stEOLNode0Pres
      Pp_BasSvrAppl_stEOLNode105Pres: provided-interface=BasSvrAppl_stEOLNode105Pres
      Pp_BasSvrAppl_stEOLNode10Pres: provided-interface=BasSvrAppl_stEOLNode10Pres
      Pp_BasSvrAppl_stEOLNode112Pres: provided-interface=BasSvrAppl_stEOLNode112Pres
      Pp_BasSvrAppl_stEOLNode119Pres: provided-interface=BasSvrAppl_stEOLNode119Pres
      Pp_BasSvrAppl_stEOLNode11Pres: provided-interface=BasSvrAppl_stEOLNode11Pres
      Pp_BasSvrAppl_stEOLNode120Pres: provided-interface=BasSvrAppl_stEOLNode120Pres
      Pp_BasSvrAppl_stEOLNode124Pres: provided-interface=BasSvrAppl_stEOLNode124Pres
      Pp_BasSvrAppl_stEOLNode126Pres: provided-interface=BasSvrAppl_stEOLNode126Pres
      Pp_BasSvrAppl_stEOLNode127Pres: provided-interface=BasSvrAppl_stEOLNode127Pres
      Pp_BasSvrAppl_stEOLNode17Pres: provided-interface=BasSvrAppl_stEOLNode17Pres
      Pp_BasSvrAppl_stEOLNode18Pres: provided-interface=BasSvrAppl_stEOLNode18Pres
      Pp_BasSvrAppl_stEOLNode1Pres: provided-interface=BasSvrAppl_stEOLNode1Pres
      Pp_BasSvrAppl_stEOLNode{22..24}Pres: provided-interface=BasSvrAppl_stEOLNode{22..24}Pres
      Pp_BasSvrAppl_stEOLNode26Pres: provided-interface=BasSvrAppl_stEOLNode26Pres
      Pp_BasSvrAppl_stEOLNode27Pres: provided-interface=BasSvrAppl_stEOLNode27Pres
      Pp_BasSvrAppl_stEOLNode29Pres: provided-interface=BasSvrAppl_stEOLNode29Pres
      Pp_BasSvrAppl_stEOLNode2Pres: provided-interface=BasSvrAppl_stEOLNode2Pres
      Pp_BasSvrAppl_stEOLNode31Pres: provided-interface=BasSvrAppl_stEOLNode31Pres
      Pp_BasSvrAppl_stEOLNode35Pres: provided-interface=BasSvrAppl_stEOLNode35Pres
      Pp_BasSvrAppl_stEOLNode36Pres: provided-interface=BasSvrAppl_stEOLNode36Pres
      Pp_BasSvrAppl_stEOLNode3Pres: provided-interface=BasSvrAppl_stEOLNode3Pres
      Pp_BasSvrAppl_stEOLNode46Pres: provided-interface=BasSvrAppl_stEOLNode46Pres
      Pp_BasSvrAppl_stEOLNode50Pres: provided-interface=BasSvrAppl_stEOLNode50Pres
      Pp_BasSvrAppl_stEOLNode53Pres: provided-interface=BasSvrAppl_stEOLNode53Pres
      Pp_BasSvrAppl_stEOLNode{60..63}Pres: provided-interface=BasSvrAppl_stEOLNode{60..63}Pres
      Pp_BasSvrAppl_stEOLNode65Pres: provided-interface=BasSvrAppl_stEOLNode65Pres
      Pp_BasSvrAppl_stEOLNode67Pres: provided-interface=BasSvrAppl_stEOLNode67Pres
      Pp_BasSvrAppl_stEOLNode69Pres: provided-interface=BasSvrAppl_stEOLNode69Pres
      Pp_BasSvrAppl_stEOLNode6Pres: provided-interface=BasSvrAppl_stEOLNode6Pres
      Pp_BasSvrAppl_stEOLNode70Pres: provided-interface=BasSvrAppl_stEOLNode70Pres
      Pp_BasSvrAppl_stEOLNode74Pres: provided-interface=BasSvrAppl_stEOLNode74Pres
      Pp_BasSvrAppl_stEOLNode75Pres: provided-interface=BasSvrAppl_stEOLNode75Pres
      Pp_BasSvrAppl_stEOLNode78Pres: provided-interface=BasSvrAppl_stEOLNode78Pres
      Pp_BasSvrAppl_stEOLNode79Pres: provided-interface=BasSvrAppl_stEOLNode79Pres
      Pp_BasSvrAppl_stEOLNode7Pres: provided-interface=BasSvrAppl_stEOLNode7Pres
      Pp_BasSvrAppl_stEOLNode83Pres: provided-interface=BasSvrAppl_stEOLNode83Pres
      Pp_BasSvrAppl_stEOLNode84Pres: provided-interface=BasSvrAppl_stEOLNode84Pres
      Pp_BasSvrAppl_stEOLNode8Pres: provided-interface=BasSvrAppl_stEOLNode8Pres
      Pp_BasSvrAppl_stEOLNode90Pres: provided-interface=BasSvrAppl_stEOLNode90Pres
      Pp_BasSvrAppl_stEOLNode91Pres: provided-interface=BasSvrAppl_stEOLNode91Pres
      Pp_BasSvrAppl_stEOLNode{93..98}Pres: provided-interface=BasSvrAppl_stEOLNode{93..98}Pres
      Pp_BasSvrAppl_stFuelType: provided-interface=BasSvrAppl_stFuelType
      Pp_BasSvrAppl_stGearBoxTyp: provided-interface=BasSvrAppl_stGearBoxTyp
      Pp_BasSvrAppl_stGearBoxVarTyp: provided-interface=BasSvrAppl_stGearBoxVarTyp
      Pp_BasSvrAppl_stGearShiftIdctr: provided-interface=BasSvrAppl_stGearShiftIdctr
      Pp_BasSvrAppl_stgGearBox: provided-interface=BasSvrAppl_stgGearBox
      Pp_BasSvrAppl_stHybridType: provided-interface=BasSvrAppl_stHybridType
      Pp_BasSvrAppl_stIgnPreStrtLogic: provided-interface=BasSvrAppl_stIgnPreStrtLogic
      Pp_BasSvrAppl_stKeylsGo: provided-interface=BasSvrAppl_stKeylsGo
      Pp_BasSvrAppl_stNrOfDoor: provided-interface=BasSvrAppl_stNrOfDoor
      Pp_BasSvrAppl_stPAMCfg: provided-interface=BasSvrAppl_stPAMCfg
      Pp_BasSvrAppl_stPrkBrkSysVar: provided-interface=BasSvrAppl_stPrkBrkSysVar
      Pp_BasSvrAppl_stProxiConfigCode: provided-interface=BasSvrAppl_stProxiConfigCode
      Pp_BasSvrAppl_stProxiProductionDate: provided-interface=BasSvrAppl_stProxiProductionDate
      Pp_BasSvrAppl_stProxiTesterCode: provided-interface=BasSvrAppl_stProxiTesterCode
      Pp_BasSvrAppl_stPtlAutPrkgSys: provided-interface=BasSvrAppl_stPtlAutPrkgSys
      Pp_BasSvrAppl_stRemoteStart: provided-interface=BasSvrAppl_stRemoteStart
      Pp_BasSvrAppl_stSAMPres: provided-interface=BasSvrAppl_stSAMPres
      Pp_BasSvrAppl_stShftrTypeVar: provided-interface=BasSvrAppl_stShftrTypeVar
      Pp_BasSvrAppl_stSRT: provided-interface=BasSvrAppl_stSRT
      Pp_BasSvrAppl_stStpStrtlPres: provided-interface=BasSvrAppl_stStpStrtlPres
      Pp_BasSvrAppl_stTHRat: provided-interface=BasSvrAppl_stTHRat
      Pp_BasSvrAppl_stTrrnSelMode: provided-interface=BasSvrAppl_stTrrnSelMode
      Pp_BasSvrAppl_stVehLineConf: provided-interface=BasSvrAppl_stVehLineConf
      Pp_DcmDspUDS_ratSpdMtrTolr: provided-interface=DcmDspUDS_ratSpdMtrTolr
      Pp_DcmDspUDS_rTCaseLow: provided-interface=DcmDspUDS_rTCaseLow
      Pp_DcmDspUDS_stCANNod24Pres: provided-interface=DcmDspUDS_stCANNod24Pres
      Pp_DcmDspUDS_stDrvTrnVar: provided-interface=DcmDspUDS_stDrvTrnVar
      Pp_DcmDspUDS_stFOTATyp: provided-interface=DcmDspUDS_stFOTATyp
      Pp_DcmDspUDS_stHillDscntCtrl: provided-interface=DcmDspUDS_stHillDscntCtrl
      Pp_DcmDspUDS_stIncrSpdConst: provided-interface=DcmDspUDS_stIncrSpdConst
      Pp_DcmDspUDS_stLLimPres: provided-interface=DcmDspUDS_stLLimPres
      Pp_DcmDspUDS_stMdlYr: provided-interface=DcmDspUDS_stMdlYr
      Pp_DcmDspUDS_stProxiConfigCodeTstrVal: provided-interface=DcmDspUDS_stProxiConfigCodeTstrVal
      Pp_DcmDspUds_stSelSpdCtrlFeat: provided-interface=DcmDspUds_stSelSpdCtrlFeat
      Pp_DcmDspUDS_stTachoFiltgTyp: provided-interface=DcmDspUDS_stTachoFiltgTyp
      Pp_DcmDspUDS_stTrlrHitchAssiPres: provided-interface=DcmDspUDS_stTrlrHitchAssiPres
      Pp_DcmDspUDS_stTrlrRvsSteerPres: provided-interface=DcmDspUDS_stTrlrRvsSteerPres
      Pp_DcmDspUDS_stTSR: provided-interface=DcmDspUDS_stTSR
      VeDIOR_h_ElecPhsrDiag_PwmInp: provided-interface=VeDIOR_h_PwmInp
      VeDIOR_Pct_ElecPhsrDiag_PWM_Inp_DC: provided-interface=VeDIOR_Pct_PwmInp_DC
      VeDIOR_b_ElecPhsrDiag_PWM_Inp_TO_Sts: provided-interface=VeDIOR_b_PwmInp_TiOutSts
      VeDIOR_h_OilLvlSnsr_PwmInp: provided-interface=VeDIOR_h_PwmInp
      VeDIOR_Pct_OilLvlSnsr_PWM_Inp_DC: provided-interface=VeDIOR_Pct_PwmInp_DC
      VeDIOR_b_OilLvlSnsr_PWM_Inp_TO_Sts: provided-interface=VeDIOR_b_PwmInp_TiOutSts
    16 x require port, all with required-interface=IO_ChEquid:
      KeCFGR_b_OilLvlSnsr_ChEquid
      KeCFGR_b_ElecPhsrDiag_ChEquid
      KeCFGR_b_SwKnkCddCh{1..3}Equid
      KeCFGR_b_StrtrRly_ChEquid
      KeCFGR_b_DMTLLkPmp_ChEquid
      KeCFGR_b_SwilEngMnt1_ChEquid
      KeCFGR_b_SrgSoln1_ChEquid
      KeCFGR_b_SwilEngMnt2_ChEquid
      KeCFGR_b_VapBlockingVlv_ChEquid
      KeCFGR_b_OBD_PurgVentVlv_ChEquid
      KeCFGR_b_InrushCircRly_ChEquid
      KeCFGR_b_AC_CluRly_ChEquid
      KeCFGR_b_LoPresFuPmpRly_ChEquid
      KeCFGR_b_FPCMFb1_ChEquid
    6 x provide port:
      VeADCR_U_FiveVoltAux: provided-interface=VsADCR_e_CnvnRes
      VeADCR_U_FiveVoltOutp: provided-interface=VsADCR_e_CnvnRes
      FiveVoltAux: provided-interface=IFAdcInpRawVal
      FiveVoltOutp: provided-interface=IFAdcInpRawVal
      CheckSPLR_b_BattBackedRAM_Init: provided-interface=CheckSPLR_b_BattBackedRAM_Init
      VeSPLR_b_MdulIdVld: provided-interface=VeSPLR_b_MdulIdVld
    require port KeCFGR_b_FiveVoltAuxAdcInpEquid: required-interface=IO_ChEquid
    require port KeCFGR_b_FiveVoltOutpAdcInpEquid: required-interface=IO_ChEquid
    require port KeCFGR_b_FiveVoltSnsAdcInpEquid: required-interface=IO_ChEquid
    38 x provide port:
      FiveVoltSns: provided-interface=IFAdcInpRawVal
      VeADCR_U_FiveVoltSns: provided-interface=VsADCR_e_CnvnRes
      VeADCR_U_VarGeomTrbFb: provided-interface=VsADCR_e_CnvnRes
      GetADCR_U_VarGeomTrbFb: provided-interface=IFAdcInpRawVal
      VeDIOR_t_BrkSwDigInpOffTi: provided-interface=VeDIOR_t_DigInpOffTi
      VeDIOR_t_DynoFuDsblReqSwDigInpOffTi: provided-interface=VeDIOR_t_DigInpOffTi
      VeDIOR_t_IgnRunStrtSwDigInpOffTi: provided-interface=VeDIOR_t_DigInpOffTi
      VeDIOR_t_NVLD_SwDigInpOffTi: provided-interface=VeDIOR_t_DigInpOffTi
      VeDIOR_t_StrtrRlyFbDigInpOffTi: provided-interface=VeDIOR_t_DigInpOffTi
      VeDIOR_e_SwilEngMnt2IndDiagInfo: provided-interface=IFIoHwAbDigOutpDiagInfo
      VeDIOR_MakeUpAirVlv_HwDiagCmn: provided-interface=IFHwDiagCmn
      VeDIOR_MakeUpAirVlv_HwDiagFltCircDtctd: provided-interface=IFHwDiagFltCirc
      VeDIOR_MakeUpAirVlv_HwDiagFltOutp: provided-interface=IFHwDiagFltOutp
      SetDIOR_b_OilShutOffVlvOutpSt: provided-interface=IFIoHwAbDigOutpSetSt
      VeDIOR_e_OilShutOffVlvIndDiagInfo: provided-interface=IFIoHwAbDigOutpDiagInfo
      VeDIOR_OilShutOffVlv_HwDiagCmn: provided-interface=IFHwDiagCmn
      VeDIOR_OilShutOffVlv_HwDiagFltCircDtctd: provided-interface=IFHwDiagFltCirc
      VeDIOR_OilShutOffVlv_HwDiagFltOutp: provided-interface=IFHwDiagFltOutp
      SetDIOR_b_SecdAirShutOffSoln1OutpSt: provided-interface=IFIoHwAbDigOutpSetSt
      VeDIOR_e_SecdAirShutOffSoln1IndDiagInfo: provided-interface=IFIoHwAbDigOutpDiagInfo
      VeDIOR_SecdAirShutOffSoln1_HwDiagCmn: provided-interface=IFHwDiagCmn
      VeDIOR_SecdAirShutOffSoln1_HwDiagFltCircDtctd: provided-interface=IFHwDiagFltCirc
      VeDIOR_SecdAirShutOffSoln1_HwDiagFltOutp: provided-interface=IFHwDiagFltOutp
      SetDIOR_b_SecdAirPmpRlyOutpSt: provided-interface=IFIoHwAbDigOutpSetSt
      VeDIOR_e_SecdAirPmpRlyIndDiagInfo: provided-interface=IFIoHwAbDigOutpDiagInfo
      VeDIOR_SecdAirPmpRly_HwDiagCmn: provided-interface=IFHwDiagCmn
      VeDIOR_SecdAirPmpRly_HwDiagFltCircDtctd: provided-interface=IFHwDiagFltCirc
      VeDIOR_SecdAirPmpRly_HwDiagFltOutp: provided-interface=IFHwDiagFltOutp
      SetDIOR_b_VapBlockingVlvOutpSt: provided-interface=IFIoHwAbDigOutpSetSt
      VeDIOR_e_VapBlockingVlvIndDiagInfo: provided-interface=IFIoHwAbDigOutpDiagInfo
      VeDIOR_VapBlockingVlv_HwDiagCmn: provided-interface=IFHwDiagCmn
      VeDIOR_VapBlockingVlv_HwDiagFltCircDtctd: provided-interface=IFHwDiagFltCirc
      VeDIOR_VapBlockingVlv_HwDiagFltOutp: provided-interface=IFHwDiagFltOutp
      SetDIOR_b_ElectcVacPmpRlyOutpSt: provided-interface=IFIoHwAbDigOutpSetSt
      VeDIOR_e_ElectcVacPmpRlyIndDiagInfo: provided-interface=IFIoHwAbDigOutpDiagInfo
      VeDIOR_ElectcVacPmpRly_HwDiagCmn: provided-interface=IFHwDiagCmn
      VeDIOR_ElectcVacPmpRly_HwDiagFltCircDtctd: provided-interface=IFHwDiagFltCirc
      VeDIOR_ElectcVacPmpRly_HwDiagFltOutp: provided-interface=IFHwDiagFltOutp
    6 x require port, all with required-interface=IO_ChEquid:
      KeCFGR_b_MakeUpAirVlv_ChEquid
      KeCFGR_b_RadrFanRlyHiSpd_ChEquid
      KeCFGR_b_OilShutOffVlv_ChEquid
      KeCFGR_b_SecdAirShutOffSoln1_ChEquid
      KeCFGR_b_SecdAirPmpRly_ChEquid
      KeCFGR_b_ElectcVacPmpRly_ChEquid
    12 x provide port:
      VeDIOR_b_Hbrdg_Coold_EGR_DiagCmn: provided-interface=IFHwDiagCmn
      VeDIOR_b_Hbrdg_Coold_EGR_DiagFltCircDftlDtctd: provided-interface=IFHwDiagFltCircDftl
      VeDIOR_b_Hbrdg_Coold_EGR_DiagFltOutp: provided-interface=IFHwDiagFltOutp
      VeDIOR_b_Hbrdg_DP_DiagCmn: provided-interface=IFHwDiagCmn
      VeDIOR_b_Hbrdg_DP_DiagFltCircDftlDtctd: provided-interface=IFHwDiagFltCircDftl
      VeDIOR_b_Hbrdg_DP_DiagFltOutp: provided-interface=IFHwDiagFltOutp
      VeDIOR_b_Hbrdg_ETC_Motor_DiagCmn: provided-interface=IFHwDiagCmn
      VeDIOR_b_Hbrdg_ETC_Motor_DiagFltCircDftlDtctd: provided-interface=IFHwDiagFltCircDftl
      VeDIOR_b_Hbrdg_ETC_Motor_DiagFltOutp: provided-interface=IFHwDiagFltOutp
      VeDIOR_b_Hbrdg_Wg1_DiagCmn: provided-interface=IFHwDiagCmn
      VeDIOR_b_Hbrdg_Wg1_DiagFltCircDftlDtctd: provided-interface=IFHwDiagFltCircDftl
      VeDIOR_b_Hbrdg_Wg1_DiagFltOutp: provided-interface=IFHwDiagFltOutp
    require port KeCFGR_b_AllGrPosnSnsr1_ChEquid: required-interface=IO_ChEquid
    require port KeCFGR_b_AllGrPosnSnsr2_ChEquid: required-interface=IO_ChEquid
    5 x provide port, all with provided-interface=IFCmplxPwmInpVal:
      VeDIOR_t_FPCM_Fb1_PWM_Inp_PrdPW_Cohrnt
      VeDIOR_t_OilLvlSnsr_PWM_Inp_PrdPW_Cohrnt
      VeDIOR_t_AllGrPosnSnsr1_PWM_Inp_PrdPW_Cohrnt
      VeDIOR_t_AllGrPosnSnsr2_PWM_Inp_PrdPW_Cohrnt
      VeDIOR_t_ElecPhsrDiag_PWM_Inp_PrdPW_Cohrnt
    require port VeBATR_U_12VoltSysAct: required-interface=VeBATR_U_12VoltSysAct
    require port VeBATR_U_12VoltSysSw: required-interface=VeBATR_U_12VoltSysSw
    require port VeFLVR_Pct_FuLvlSca: required-interface=VeFLVR_Pct_FuLvlSca
    8 x provide port:
      VeDMRR_g_EnblCondSts: provided-interface=VeDMRR_g_EnblCondSts
      GetDIOR_b_IgnRunStrtSwFiltdVal: provided-interface=IFDigInpVal
      GetDMRR_g_EnblCondSts: provided-interface=GetDMRR_g_EnblCondSts
      VeDIDR_Cnt_Mode4Rst: provided-interface=IF_rbm_Dsm_Conf_FcmClrCntr
      VeCANR_b_CRC_Hyb_Therm_Cmd_FD16TO: provided-interface=VeCANR_b_CRC_Hyb_Therm_Cmd_FD16TO
      VeCANR_b_MC_Hyb_Therm_Cmd_FD16TO: provided-interface=VeCANR_b_MC_Hyb_Therm_Cmd_FD16TO
      VeCANR_y_CRC_Hyb_Therm_Cmd_FD16: provided-interface=VeCANR_y_CRC_Hyb_Therm_Cmd_FD16
      VeCANR_y_MC_Hyb_Therm_Cmd_FD16: provided-interface=VeCANR_y_MC_Hyb_Therm_Cmd_FD16
    573 x require port:
      SendCANR_AccelPdlPosn_OBD_FD16: required-interface=SendCANR_AccelPdlPosn_OBD_FD16
      SendCANR_AccelPdlPosn_OBD_FD16Vld: required-interface=SendCANR_AccelPdlPosn_OBD_FD16Vld
      SendCANR_AtmrcPressure_W_FD16: required-interface=SendCANR_AtmrcPressure_W_FD16
      SendCANR_AtmrcPressure_W_FD16Vld: required-interface=SendCANR_AtmrcPressure_W_FD16Vld
      SendCANR_AtmrcPrsrFailSts_WFD16: required-interface=SendCANR_AtmrcPrsrFailSts_WFD16
      SendCANR_AtmrcPrsrFailSts_WFD16Vld: required-interface=SendCANR_AtmrcPrsrFailSts_WFD16Vld
      SendCANR_CARB_PERM_FD16: required-interface=SendCANR_CARB_PERM_FD16
      SendCANR_CARB_PERM_FD16Vld: required-interface=SendCANR_CARB_PERM_FD16Vld
      SendCANR_CRC_ENGINE1_FD16: required-interface=SendCANR_CRC_ENGINE1_FD16
      SendCANR_CRC_ENGINE1_FD16Vld: required-interface=SendCANR_CRC_ENGINE1_FD16Vld
      SendCANR_CRC_ENGINE3_FD16: required-interface=SendCANR_CRC_ENGINE3_FD16
      SendCANR_CRC_ENGINE3_FD16Vld: required-interface=SendCANR_CRC_ENGINE3_FD16Vld
      SendCANR_CRC_ENGINE6_FD16: required-interface=SendCANR_CRC_ENGINE6_FD16
      SendCANR_CRC_ENGINE6_FD16Vld: required-interface=SendCANR_CRC_ENGINE6_FD16Vld
      SendCANR_CRC_ENGINE7_FD16: required-interface=SendCANR_CRC_ENGINE7_FD16
      SendCANR_CRC_ENGINE7_FD16Vld: required-interface=SendCANR_CRC_ENGINE7_FD16Vld
      SendCANR_CRC_ENGINE8_FD16: required-interface=SendCANR_CRC_ENGINE8_FD16
      SendCANR_CRC_ENGINE8_FD16Vld: required-interface=SendCANR_CRC_ENGINE8_FD16Vld
      SendCANR_CRC_ENG_HYBD_FD_3FD16: required-interface=SendCANR_CRC_ENG_HYBD_FD_3FD16
      SendCANR_CRC_ENG_HYBD_FD_3FD16Vld: required-interface=SendCANR_CRC_ENG_HYBD_FD_3FD16Vld
      SendCANR_CRC_ENG_HYBD_FD_4FD16: required-interface=SendCANR_CRC_ENG_HYBD_FD_4FD16
      SendCANR_CRC_ENG_HYBD_FD_4FD16Vld: required-interface=SendCANR_CRC_ENG_HYBD_FD_4FD16Vld
      SendCANR_CRC_OBDCNTNFRAMEFD16: required-interface=SendCANR_CRC_OBDCNTNFRAMEFD16
      SendCANR_CRC_OBDCNTNFRAMEFD16Vld: required-interface=SendCANR_CRC_OBDCNTNFRAMEFD16Vld
      SendCANR_CarbWarmUp_FD16: required-interface=SendCANR_CarbWarmUp_FD16
      SendCANR_CarbWarmUp_FD16Vld: required-interface=SendCANR_CarbWarmUp_FD16Vld
      SendCANR_CldStrtDenominatorFD16: required-interface=SendCANR_CldStrtDenominatorFD16
      SendCANR_CldStrtDenominatorFD16Vld: required-interface=SendCANR_CldStrtDenominatorFD16Vld
      SendCANR_CompressorSts_FD16: required-interface=SendCANR_CompressorSts_FD16
      SendCANR_CompressorSts_FD16Vld: required-interface=SendCANR_CompressorSts_FD16Vld
      SendCANR_CruiseControlSts_FD16: required-interface=SendCANR_CruiseControlSts_FD16
      SendCANR_CruiseControlSts_FD16Vld: required-interface=SendCANR_CruiseControlSts_FD16Vld
      SendCANR_CruiseCtrlLampSts_FD16: required-interface=SendCANR_CruiseCtrlLampSts_FD16
      SendCANR_CruiseCtrlLampSts_FD16Vld: required-interface=SendCANR_CruiseCtrlLampSts_FD16Vld
      SendCANR_EngCltTmpV_FD16: required-interface=SendCANR_EngCltTmpV_FD16
      SendCANR_EngCltTmpV_FD16Vld: required-interface=SendCANR_EngCltTmpV_FD16Vld
      SendCANR_EngCltTmp_FD16: required-interface=SendCANR_EngCltTmp_FD16
      SendCANR_EngCltTmp_FD16Vld: required-interface=SendCANR_EngCltTmp_FD16Vld
      SendCANR_EngMaxRPM_W_FD16: required-interface=SendCANR_EngMaxRPM_W_FD16
      SendCANR_EngMaxRPM_W_FD16Vld: required-interface=SendCANR_EngMaxRPM_W_FD16Vld
      SendCANR_EngOffTmPTV_FD16: required-interface=SendCANR_EngOffTmPTV_FD16
      SendCANR_EngOffTmPTV_FD16Vld: required-interface=SendCANR_EngOffTmPTV_FD16Vld
      SendCANR_EngOffTmPT_FD16: required-interface=SendCANR_EngOffTmPT_FD16
      SendCANR_EngOffTmPT_FD16Vld: required-interface=SendCANR_EngOffTmPT_FD16Vld
      SendCANR_EngOilTempFD16: required-interface=SendCANR_EngOilTempFD16
      SendCANR_EngOilTempFD16Vld: required-interface=SendCANR_EngOilTempFD16Vld
      SendCANR_EngSpd_FD16: required-interface=SendCANR_EngSpd_FD16
      SendCANR_EngSpd_FD16Vld: required-interface=SendCANR_EngSpd_FD16Vld
      SendCANR_EngTqACCCapabilityFD16: required-interface=SendCANR_EngTqACCCapabilityFD16
      SendCANR_EngTqACCCapabilityFD16Vld: required-interface=SendCANR_EngTqACCCapabilityFD16Vld
      SendCANR_EngTqCapbltyMaxTqFD16: required-interface=SendCANR_EngTqCapbltyMaxTqFD16
      SendCANR_EngTqCapbltyMaxTqFD16Vld: required-interface=SendCANR_EngTqCapbltyMaxTqFD16Vld
      SendCANR_EngTqCapbltyMinTqFD16: required-interface=SendCANR_EngTqCapbltyMinTqFD16
      SendCANR_EngTqCapbltyMinTqFD16Vld: required-interface=SendCANR_EngTqCapbltyMinTqFD16Vld
      SendCANR_EngTqCpbtEngOpMdFD16: required-interface=SendCANR_EngTqCpbtEngOpMdFD16
      SendCANR_EngTqCpbtEngOpMdFD16Vld: required-interface=SendCANR_EngTqCpbtEngOpMdFD16Vld
      SendCANR_EngTqCpbtFrmCntrFD16: required-interface=SendCANR_EngTqCpbtFrmCntrFD16
      SendCANR_EngTqCpbtFrmCntrFD16Vld: required-interface=SendCANR_EngTqCpbtFrmCntrFD16Vld
      SendCANR_EngTqCpbtMaxOffTqFD16: required-interface=SendCANR_EngTqCpbtMaxOffTqFD16
      SendCANR_EngTqCpbtMaxOffTqFD16Vld: required-interface=SendCANR_EngTqCpbtMaxOffTqFD16Vld
      SendCANR_EngTqCpbtMinRunTqFD16: required-interface=SendCANR_EngTqCpbtMinRunTqFD16
      SendCANR_EngTqCpbtMinRunTqFD16Vld: required-interface=SendCANR_EngTqCpbtMinRunTqFD16Vld
      SendCANR_EngTqCpbtRefEngSpdFD16: required-interface=SendCANR_EngTqCpbtRefEngSpdFD16
      SendCANR_EngTqCpbtRefEngSpdFD16Vld: required-interface=SendCANR_EngTqCpbtRefEngSpdFD16Vld
      SendCANR_EngineOFFTime_FD16: required-interface=SendCANR_EngineOFFTime_FD16
      SendCANR_EngineOFFTime_FD16Vld: required-interface=SendCANR_EngineOFFTime_FD16Vld
      SendCANR_EngineWaterTemp_FD16: required-interface=SendCANR_EngineWaterTemp_FD16
      SendCANR_EngineWaterTemp_FD16Vld: required-interface=SendCANR_EngineWaterTemp_FD16Vld
      SendCANR_GenDenominator_FD16: required-interface=SendCANR_GenDenominator_FD16
      SendCANR_GenDenominator_FD16Vld: required-interface=SendCANR_GenDenominator_FD16Vld
      SendCANR_IgnCntrTrue_FD16: required-interface=SendCANR_IgnCntrTrue_FD16
      SendCANR_IgnCntrTrue_FD16Vld: required-interface=SendCANR_IgnCntrTrue_FD16Vld
      SendCANR_Inp_ICC_Fail_FD16: required-interface=SendCANR_Inp_ICC_Fail_FD16
      SendCANR_Inp_ICC_Fail_FD16Vld: required-interface=SendCANR_Inp_ICC_Fail_FD16Vld
      SendCANR_InputsGDFail_FD16: required-interface=SendCANR_InputsGDFail_FD16
      SendCANR_InputsGDFail_FD16Vld: required-interface=SendCANR_InputsGDFail_FD16Vld
      SendCANR_LoadOBD_FD16: required-interface=SendCANR_LoadOBD_FD16
      SendCANR_LoadOBD_FD16Vld: required-interface=SendCANR_LoadOBD_FD16Vld
      SendCANR_MC_ENG1FD16: required-interface=SendCANR_MC_ENG1FD16
      SendCANR_MC_ENG1FD16Vld: required-interface=SendCANR_MC_ENG1FD16Vld
      SendCANR_MC_ENG7_FD16: required-interface=SendCANR_MC_ENG7_FD16
      SendCANR_MC_ENG7_FD16Vld: required-interface=SendCANR_MC_ENG7_FD16Vld
      SendCANR_MC_ENG8_FD16: required-interface=SendCANR_MC_ENG8_FD16
      SendCANR_MC_ENG8_FD16Vld: required-interface=SendCANR_MC_ENG8_FD16Vld
      SendCANR_MC_ENGINE3_FD16: required-interface=SendCANR_MC_ENGINE3_FD16
      SendCANR_MC_ENGINE3_FD16Vld: required-interface=SendCANR_MC_ENGINE3_FD16Vld
      SendCANR_MC_ENG_HYBD_FD_3FD16: required-interface=SendCANR_MC_ENG_HYBD_FD_3FD16
      SendCANR_MC_ENG_HYBD_FD_3FD16Vld: required-interface=SendCANR_MC_ENG_HYBD_FD_3FD16Vld
      SendCANR_MC_ENG_HYBD_FD_4FD16: required-interface=SendCANR_MC_ENG_HYBD_FD_4FD16
      SendCANR_MC_ENG_HYBD_FD_4FD16Vld: required-interface=SendCANR_MC_ENG_HYBD_FD_4FD16Vld
      SendCANR_MC_OBDCONTENTFRAMEFD16: required-interface=SendCANR_MC_OBDCONTENTFRAMEFD16
      SendCANR_MC_OBDCONTENTFRAMEFD16Vld: required-interface=SendCANR_MC_OBDCONTENTFRAMEFD16Vld
      SendCANR_MaxEngSpdCap_FD16: required-interface=SendCANR_MaxEngSpdCap_FD16
      SendCANR_MaxEngSpdCap_FD16Vld: required-interface=SendCANR_MaxEngSpdCap_FD16Vld
      SendCANR_MdsAct_FD16: required-interface=SendCANR_MdsAct_FD16
      SendCANR_MdsAct_FD16Vld: required-interface=SendCANR_MdsAct_FD16Vld
      SendCANR_MinEngSpdCap_FD16: required-interface=SendCANR_MinEngSpdCap_FD16
      SendCANR_MinEngSpdCap_FD16Vld: required-interface=SendCANR_MinEngSpdCap_FD16Vld
      SendCANR_MsgCtr_ENGINE6_FD16: required-interface=SendCANR_MsgCtr_ENGINE6_FD16
      SendCANR_MsgCtr_ENGINE6_FD16Vld: required-interface=SendCANR_MsgCtr_ENGINE6_FD16Vld
      SendCANR_OAT_PT_EstV_FD16: required-interface=SendCANR_OAT_PT_EstV_FD16
      SendCANR_OAT_PT_EstV_FD16Vld: required-interface=SendCANR_OAT_PT_EstV_FD16Vld
      SendCANR_OAT_PT_Est_FD16: required-interface=SendCANR_OAT_PT_Est_FD16
      SendCANR_OAT_PT_Est_FD16Vld: required-interface=SendCANR_OAT_PT_Est_FD16Vld
      SendCANR_SelectorSysFailStsFD16: required-interface=SendCANR_SelectorSysFailStsFD16
      SendCANR_SelectorSysFailStsFD16Vld: required-interface=SendCANR_SelectorSysFailStsFD16Vld
      SendCANR_ServiceHybSys_FD16: required-interface=SendCANR_ServiceHybSys_FD16
      SendCANR_ServiceHybSys_FD16Vld: required-interface=SendCANR_ServiceHybSys_FD16Vld
      SendCANR_SpStDispstat_FD16: required-interface=SendCANR_SpStDispstat_FD16
      SendCANR_SpStDispstat_FD16Vld: required-interface=SendCANR_SpStDispstat_FD16Vld
      SendCANR_SpStSwStat_FD16: required-interface=SendCANR_SpStSwStat_FD16
      SendCANR_SpStSwStat_FD16Vld: required-interface=SendCANR_SpStSwStat_FD16Vld
      SendCANR_StartRlyECMFbFaultFD16: required-interface=SendCANR_StartRlyECMFbFaultFD16
      SendCANR_StartRlyECMFbFaultFD16Vld: required-interface=SendCANR_StartRlyECMFbFaultFD16Vld
      SendCANR_TerModeDesiredStatFD16: required-interface=SendCANR_TerModeDesiredStatFD16
      SendCANR_TerModeDesiredStatFD16Vld: required-interface=SendCANR_TerModeDesiredStatFD16Vld
      SendCANR_TerrainHMIRq_ECM_FD16: required-interface=SendCANR_TerrainHMIRq_ECM_FD16
      SendCANR_TerrainHMIRq_ECM_FD16Vld: required-interface=SendCANR_TerrainHMIRq_ECM_FD16Vld
      SendCANR_ThrmlMngmtActive_WFD16: required-interface=SendCANR_ThrmlMngmtActive_WFD16
      SendCANR_ThrmlMngmtActive_WFD16Vld: required-interface=SendCANR_ThrmlMngmtActive_WFD16Vld
      SendCANR_TransWarmUpMin_RPMFD16: required-interface=SendCANR_TransWarmUpMin_RPMFD16
      SendCANR_TransWarmUpMin_RPMFD16Vld: required-interface=SendCANR_TransWarmUpMin_RPMFD16Vld
      SendCANR_TransWarmUpReq_FD16: required-interface=SendCANR_TransWarmUpReq_FD16
      SendCANR_TransWarmUpReq_FD16Vld: required-interface=SendCANR_TransWarmUpReq_FD16Vld
      SendCANR_TrnModeStat_ECMFD16: required-interface=SendCANR_TrnModeStat_ECMFD16
      SendCANR_TrnModeStat_ECMFD16Vld: required-interface=SendCANR_TrnModeStat_ECMFD16Vld
      SendCANR_Trns_DrvMdReq_ECM_FD16: required-interface=SendCANR_Trns_DrvMdReq_ECM_FD16
      SendCANR_Trns_DrvMdReq_ECM_FD16Vld: required-interface=SendCANR_Trns_DrvMdReq_ECM_FD16Vld
      SendCANR_VehicleSetSpeed_W_FD16: required-interface=SendCANR_VehicleSetSpeed_W_FD16
      SendCANR_VehicleSetSpeed_W_FD16Vld: required-interface=SendCANR_VehicleSetSpeed_W_FD16Vld
      SendCANR_ACPressureFailSts_FD3: required-interface=SendCANR_ACPressureFailSts_FD3
      SendCANR_ACPressureFailSts_FD3Vld: required-interface=SendCANR_ACPressureFailSts_FD3Vld
      SendCANR_ACPressure_FD3: required-interface=SendCANR_ACPressure_FD3
      SendCANR_ACPressure_FD3Vld: required-interface=SendCANR_ACPressure_FD3Vld
      SendCANR_AFTER_RUN_STATUS_FD3: required-interface=SendCANR_AFTER_RUN_STATUS_FD3
      SendCANR_AFTER_RUN_STATUS_FD3Vld: required-interface=SendCANR_AFTER_RUN_STATUS_FD3Vld
      SendCANR_AGS2Posn_FD3: required-interface=SendCANR_AGS2Posn_FD3
      SendCANR_AGS2Posn_FD3Vld: required-interface=SendCANR_AGS2Posn_FD3Vld
      SendCANR_AGSposn_FD3: required-interface=SendCANR_AGSposn_FD3
      SendCANR_AGSposn_FD3Vld: required-interface=SendCANR_AGSposn_FD3Vld
      SendCANR_AM_ECM_Prsnt_FD3: required-interface=SendCANR_AM_ECM_Prsnt_FD3
      SendCANR_AM_ECM_Prsnt_FD3Vld: required-interface=SendCANR_AM_ECM_Prsnt_FD3Vld
      SendCANR_AccelPdlPosn_OBD_FD3: required-interface=SendCANR_AccelPdlPosn_OBD_FD3
      SendCANR_AccelPdlPosn_OBD_FD3Vld: required-interface=SendCANR_AccelPdlPosn_OBD_FD3Vld
      SendCANR_AdblueRemainDist_FD3: required-interface=SendCANR_AdblueRemainDist_FD3
      SendCANR_AdblueRemainDist_FD3Vld: required-interface=SendCANR_AdblueRemainDist_FD3Vld
      SendCANR_Adblue_FL_LVL_FD3: required-interface=SendCANR_Adblue_FL_LVL_FD3
      SendCANR_Adblue_FL_LVL_FD3Vld: required-interface=SendCANR_Adblue_FL_LVL_FD3Vld
      SendCANR_Adblue_Stat_FD3: required-interface=SendCANR_Adblue_Stat_FD3
      SendCANR_Adblue_Stat_FD3Vld: required-interface=SendCANR_Adblue_Stat_FD3Vld
      SendCANR_AfterRunReq_FD3: required-interface=SendCANR_AfterRunReq_FD3
      SendCANR_AfterRunReq_FD3Vld: required-interface=SendCANR_AfterRunReq_FD3Vld
      SendCANR_AftrRnClntPmpFaiStsFD3: required-interface=SendCANR_AftrRnClntPmpFaiStsFD3
      SendCANR_AftrRnClntPmpFaiStsFD3Vld: required-interface=SendCANR_AftrRnClntPmpFaiStsFD3Vld
      SendCANR_AtmPresrFailSts_W_FD3: required-interface=SendCANR_AtmPresrFailSts_W_FD3
      SendCANR_AtmPresrFailSts_W_FD3Vld: required-interface=SendCANR_AtmPresrFailSts_W_FD3Vld
      SendCANR_AtmPressure_W_FD3: required-interface=SendCANR_AtmPressure_W_FD3
      SendCANR_AtmPressure_W_FD3Vld: required-interface=SendCANR_AtmPressure_W_FD3Vld
      SendCANR_AxleInAir_Stat_FD3: required-interface=SendCANR_AxleInAir_Stat_FD3
      SendCANR_AxleInAir_Stat_FD3Vld: required-interface=SendCANR_AxleInAir_Stat_FD3Vld
      SendCANR_BarPrsAbsV_FD3: required-interface=SendCANR_BarPrsAbsV_FD3
      SendCANR_BarPrsAbsV_FD3Vld: required-interface=SendCANR_BarPrsAbsV_FD3Vld
      SendCANR_BarPrsAbs_FD3: required-interface=SendCANR_BarPrsAbs_FD3
      SendCANR_BarPrsAbs_FD3Vld: required-interface=SendCANR_BarPrsAbs_FD3Vld
      SendCANR_BoostVacGauge_FD3: required-interface=SendCANR_BoostVacGauge_FD3
      SendCANR_BoostVacGauge_FD3Vld: required-interface=SendCANR_BoostVacGauge_FD3Vld
      SendCANR_BrkSw1Stat_FD3: required-interface=SendCANR_BrkSw1Stat_FD3
      SendCANR_BrkSw1Stat_FD3Vld: required-interface=SendCANR_BrkSw1Stat_FD3Vld
      SendCANR_BrkSw2Stat_FD3: required-interface=SendCANR_BrkSw2Stat_FD3
      SendCANR_BrkSw2Stat_FD3Vld: required-interface=SendCANR_BrkSw2Stat_FD3Vld
      SendCANR_CARB_PERM_FD3: required-interface=SendCANR_CARB_PERM_FD3
      SendCANR_CARB_PERM_FD3Vld: required-interface=SendCANR_CARB_PERM_FD3Vld
      SendCANR_CC_SetSpdDspl_KPH_FD3: required-interface=SendCANR_CC_SetSpdDspl_KPH_FD3
      SendCANR_CC_SetSpdDspl_KPH_FD3Vld: required-interface=SendCANR_CC_SetSpdDspl_KPH_FD3Vld
      SendCANR_CC_SetSpdDspl_MPH_FD3: required-interface=SendCANR_CC_SetSpdDspl_MPH_FD3
      SendCANR_CC_SetSpdDspl_MPH_FD3Vld: required-interface=SendCANR_CC_SetSpdDspl_MPH_FD3Vld
      SendCANR_COOLING_REQ_STATUS_FD3: required-interface=SendCANR_COOLING_REQ_STATUS_FD3
      SendCANR_COOLING_REQ_STATUS_FD3Vld: required-interface=SendCANR_COOLING_REQ_STATUS_FD3Vld
      SendCANR_CRC_ENGINE1_FD3: required-interface=SendCANR_CRC_ENGINE1_FD3
      SendCANR_CRC_ENGINE1_FD3Vld: required-interface=SendCANR_CRC_ENGINE1_FD3Vld
      SendCANR_CRC_ENGINE3_FD3: required-interface=SendCANR_CRC_ENGINE3_FD3
      SendCANR_CRC_ENGINE3_FD3Vld: required-interface=SendCANR_CRC_ENGINE3_FD3Vld
      SendCANR_CRC_ENGINE6_FD3: required-interface=SendCANR_CRC_ENGINE6_FD3
      SendCANR_CRC_ENGINE6_FD3Vld: required-interface=SendCANR_CRC_ENGINE6_FD3Vld
      SendCANR_CRC_ENGINE7_FD3: required-interface=SendCANR_CRC_ENGINE7_FD3
      SendCANR_CRC_ENGINE7_FD3Vld: required-interface=SendCANR_CRC_ENGINE7_FD3Vld
      SendCANR_CRC_ENGINE8_FD3: required-interface=SendCANR_CRC_ENGINE8_FD3
      SendCANR_CRC_ENGINE8_FD3Vld: required-interface=SendCANR_CRC_ENGINE8_FD3Vld
      SendCANR_CRC_ENGINE_HYB_FD_3FD3: required-interface=SendCANR_CRC_ENGINE_HYB_FD_3FD3
      SendCANR_CRC_ENGINE_HYB_FD_3FD3Vld: required-interface=SendCANR_CRC_ENGINE_HYB_FD_3FD3Vld
      SendCANR_CRC_ENGINE_HYB_FD_4FD3: required-interface=SendCANR_CRC_ENGINE_HYB_FD_4FD3
      SendCANR_CRC_ENGINE_HYB_FD_4FD3Vld: required-interface=SendCANR_CRC_ENGINE_HYB_FD_4FD3Vld
      SendCANR_CRC_OBDCONTENTFRAMEFD3: required-interface=SendCANR_CRC_OBDCONTENTFRAMEFD3
      SendCANR_CRC_OBDCONTENTFRAMEFD3Vld: required-interface=SendCANR_CRC_OBDCONTENTFRAMEFD3Vld
      SendCANR_CarbWarmUp_FD3: required-interface=SendCANR_CarbWarmUp_FD3
      SendCANR_CarbWarmUp_FD3Vld: required-interface=SendCANR_CarbWarmUp_FD3Vld
      SendCANR_CatHtgStateActive_FD3: required-interface=SendCANR_CatHtgStateActive_FD3
      SendCANR_CatHtgStateActive_FD3Vld: required-interface=SendCANR_CatHtgStateActive_FD3Vld
      SendCANR_CatTempMaint_FD3: required-interface=SendCANR_CatTempMaint_FD3
      SendCANR_CatTempMaint_FD3Vld: required-interface=SendCANR_CatTempMaint_FD3Vld
      SendCANR_CldStrtDenominator_FD3: required-interface=SendCANR_CldStrtDenominator_FD3
      SendCANR_CldStrtDenominator_FD3Vld: required-interface=SendCANR_CldStrtDenominator_FD3Vld
      SendCANR_CompressorSts_FD3: required-interface=SendCANR_CompressorSts_FD3
      SendCANR_CompressorSts_FD3Vld: required-interface=SendCANR_CompressorSts_FD3Vld
      SendCANR_CoolLo_FD3: required-interface=SendCANR_CoolLo_FD3
      SendCANR_CoolLo_FD3Vld: required-interface=SendCANR_CoolLo_FD3Vld
      SendCANR_CoolVlvPos_FD3: required-interface=SendCANR_CoolVlvPos_FD3
      SendCANR_CoolVlvPos_FD3Vld: required-interface=SendCANR_CoolVlvPos_FD3Vld
      SendCANR_CountDown_FD3: required-interface=SendCANR_CountDown_FD3
      SendCANR_CountDown_FD3Vld: required-interface=SendCANR_CountDown_FD3Vld
      SendCANR_CruiseCntrlLampStsFD3: required-interface=SendCANR_CruiseCntrlLampStsFD3
      SendCANR_CruiseCntrlLampStsFD3Vld: required-interface=SendCANR_CruiseCntrlLampStsFD3Vld
      SendCANR_CruiseControlSts_FD3: required-interface=SendCANR_CruiseControlSts_FD3
      SendCANR_CruiseControlSts_FD3Vld: required-interface=SendCANR_CruiseControlSts_FD3Vld
      SendCANR_DEF_LOW_FD3: required-interface=SendCANR_DEF_LOW_FD3
      SendCANR_DEF_LOW_FD3Vld: required-interface=SendCANR_DEF_LOW_FD3Vld
      SendCANR_DPF_Man_Stat_FD3: required-interface=SendCANR_DPF_Man_Stat_FD3
      SendCANR_DPF_Man_Stat_FD3Vld: required-interface=SendCANR_DPF_Man_Stat_FD3Vld
      SendCANR_DefFuelEcon_FD3: required-interface=SendCANR_DefFuelEcon_FD3
      SendCANR_DefFuelEcon_FD3Vld: required-interface=SendCANR_DefFuelEcon_FD3Vld
      SendCANR_DistOilLifeRst_FD3: required-interface=SendCANR_DistOilLifeRst_FD3
      SendCANR_DistOilLifeRst_FD3Vld: required-interface=SendCANR_DistOilLifeRst_FD3Vld
      SendCANR_DrvAway_Alert_FD3: required-interface=SendCANR_DrvAway_Alert_FD3
      SendCANR_DrvAway_Alert_FD3Vld: required-interface=SendCANR_DrvAway_Alert_FD3Vld
      SendCANR_DrvAway_Inhibit_FD3: required-interface=SendCANR_DrvAway_Inhibit_FD3
      SendCANR_DrvAway_Inhibit_FD3Vld: required-interface=SendCANR_DrvAway_Inhibit_FD3Vld
      SendCANR_EB_ACC_AVLBL_FD3: required-interface=SendCANR_EB_ACC_AVLBL_FD3
      SendCANR_EB_ACC_AVLBL_FD3Vld: required-interface=SendCANR_EB_ACC_AVLBL_FD3Vld
      SendCANR_EB_Pwr_FD3: required-interface=SendCANR_EB_Pwr_FD3
      SendCANR_EB_Pwr_FD3Vld: required-interface=SendCANR_EB_Pwr_FD3Vld
      SendCANR_EB_Stat3_FD3: required-interface=SendCANR_EB_Stat3_FD3
      SendCANR_EB_Stat3_FD3Vld: required-interface=SendCANR_EB_Stat3_FD3Vld
      SendCANR_ECMWkSiteInvtrStsFD3: required-interface=SendCANR_ECMWkSiteInvtrStsFD3
      SendCANR_ECMWkSiteInvtrStsFD3Vld: required-interface=SendCANR_ECMWkSiteInvtrStsFD3Vld
      SendCANR_ECM_AirflowRequest_FD3: required-interface=SendCANR_ECM_AirflowRequest_FD3
      SendCANR_ECM_AirflowRequest_FD3Vld: required-interface=SendCANR_ECM_AirflowRequest_FD3Vld
      SendCANR_ECM_FOTA_Conflict_FD3: required-interface=SendCANR_ECM_FOTA_Conflict_FD3
      SendCANR_ECM_FOTA_Conflict_FD3Vld: required-interface=SendCANR_ECM_FOTA_Conflict_FD3Vld
      SendCANR_ECM_HMI_Timer_RQ_FD3: required-interface=SendCANR_ECM_HMI_Timer_RQ_FD3
      SendCANR_ECM_HMI_Timer_RQ_FD3Vld: required-interface=SendCANR_ECM_HMI_Timer_RQ_FD3Vld
      SendCANR_ECM_HoodAjar_FD3: required-interface=SendCANR_ECM_HoodAjar_FD3
      SendCANR_ECM_HoodAjar_FD3Vld: required-interface=SendCANR_ECM_HoodAjar_FD3Vld
      SendCANR_ECM_MSG_RQ_FD3: required-interface=SendCANR_ECM_MSG_RQ_FD3
      SendCANR_ECM_MSG_RQ_FD3Vld: required-interface=SendCANR_ECM_MSG_RQ_FD3Vld
      SendCANR_ECM_THA_Resp_FD3: required-interface=SendCANR_ECM_THA_Resp_FD3
      SendCANR_ECM_THA_Resp_FD3Vld: required-interface=SendCANR_ECM_THA_Resp_FD3Vld
      SendCANR_ECM_TRSC_Resp_FD3: required-interface=SendCANR_ECM_TRSC_Resp_FD3
      SendCANR_ECM_TRSC_Resp_FD3Vld: required-interface=SendCANR_ECM_TRSC_Resp_FD3Vld
      SendCANR_ECM_Thrml_AADReq_FD3: required-interface=SendCANR_ECM_Thrml_AADReq_FD3
      SendCANR_ECM_Thrml_AADReq_FD3Vld: required-interface=SendCANR_ECM_Thrml_AADReq_FD3Vld
      SendCANR_ECM_WARN_BTO_1_FD3: required-interface=SendCANR_ECM_WARN_BTO_1_FD3
      SendCANR_ECM_WARN_BTO_1_FD3Vld: required-interface=SendCANR_ECM_WARN_BTO_1_FD3Vld
      SendCANR_ECM_WARN_BTO_FD3: required-interface=SendCANR_ECM_WARN_BTO_FD3
      SendCANR_ECM_WARN_BTO_FD3Vld: required-interface=SendCANR_ECM_WARN_BTO_FD3Vld
      SendCANR_ECM_WARN_FD3: required-interface=SendCANR_ECM_WARN_FD3
      SendCANR_ECM_WARN_FD3Vld: required-interface=SendCANR_ECM_WARN_FD3Vld
      SendCANR_ENGINE_RESET_FD3: required-interface=SendCANR_ENGINE_RESET_FD3
      SendCANR_ENGINE_RESET_FD3Vld: required-interface=SendCANR_ENGINE_RESET_FD3Vld
      SendCANR_ESP_TrqRqEnabl_FD3: required-interface=SendCANR_ESP_TrqRqEnabl_FD3
      SendCANR_ESP_TrqRqEnabl_FD3Vld: required-interface=SendCANR_ESP_TrqRqEnabl_FD3Vld
      SendCANR_ETCFailSts_FD3: required-interface=SendCANR_ETCFailSts_FD3
      SendCANR_ETCFailSts_FD3Vld: required-interface=SendCANR_ETCFailSts_FD3Vld
      SendCANR_EngBrkStat_FD3: required-interface=SendCANR_EngBrkStat_FD3
      SendCANR_EngBrkStat_FD3Vld: required-interface=SendCANR_EngBrkStat_FD3Vld
      SendCANR_EngChmRq_FD3: required-interface=SendCANR_EngChmRq_FD3
      SendCANR_EngChmRq_FD3Vld: required-interface=SendCANR_EngChmRq_FD3Vld
      SendCANR_EngCltTmpV_FD3: required-interface=SendCANR_EngCltTmpV_FD3
      SendCANR_EngCltTmpV_FD3Vld: required-interface=SendCANR_EngCltTmpV_FD3Vld
      SendCANR_EngCltTmp_FD3: required-interface=SendCANR_EngCltTmp_FD3
      SendCANR_EngCltTmp_FD3Vld: required-interface=SendCANR_EngCltTmp_FD3Vld
      SendCANR_EngHalfCylSpdMaxLimFD3: required-interface=SendCANR_EngHalfCylSpdMaxLimFD3
      SendCANR_EngHalfCylSpdMaxLimFD3Vld: required-interface=SendCANR_EngHalfCylSpdMaxLimFD3Vld
      SendCANR_EngHalfCylSpdMinLimFD3: required-interface=SendCANR_EngHalfCylSpdMinLimFD3
      SendCANR_EngHalfCylSpdMinLimFD3Vld: required-interface=SendCANR_EngHalfCylSpdMinLimFD3Vld
      SendCANR_EngIntAirTmpV_FD3: required-interface=SendCANR_EngIntAirTmpV_FD3
      SendCANR_EngIntAirTmpV_FD3Vld: required-interface=SendCANR_EngIntAirTmpV_FD3Vld
      SendCANR_EngIntAirTmp_FD3: required-interface=SendCANR_EngIntAirTmp_FD3
      SendCANR_EngIntAirTmp_FD3Vld: required-interface=SendCANR_EngIntAirTmp_FD3Vld
      SendCANR_EngLoad_OBD_ePT_FD3: required-interface=SendCANR_EngLoad_OBD_ePT_FD3
      SendCANR_EngLoad_OBD_ePT_FD3Vld: required-interface=SendCANR_EngLoad_OBD_ePT_FD3Vld
      SendCANR_EngMaxRPM_W_FD3: required-interface=SendCANR_EngMaxRPM_W_FD3
      SendCANR_EngMaxRPM_W_FD3Vld: required-interface=SendCANR_EngMaxRPM_W_FD3Vld
      SendCANR_EngOffTmPTV_FD3: required-interface=SendCANR_EngOffTmPTV_FD3
      SendCANR_EngOffTmPTV_FD3Vld: required-interface=SendCANR_EngOffTmPTV_FD3Vld
      SendCANR_EngOffTmPT_FD3: required-interface=SendCANR_EngOffTmPT_FD3
      SendCANR_EngOffTmPT_FD3Vld: required-interface=SendCANR_EngOffTmPT_FD3Vld
      SendCANR_EngOutofFuel_FD3: required-interface=SendCANR_EngOutofFuel_FD3
      SendCANR_EngOutofFuel_FD3Vld: required-interface=SendCANR_EngOutofFuel_FD3Vld
      SendCANR_EngTqACCCapabilityFD3: required-interface=SendCANR_EngTqACCCapabilityFD3
      SendCANR_EngTqACCCapabilityFD3Vld: required-interface=SendCANR_EngTqACCCapabilityFD3Vld
      SendCANR_EngTqCapbltyMaxTq_FD3: required-interface=SendCANR_EngTqCapbltyMaxTq_FD3
      SendCANR_EngTqCapbltyMaxTq_FD3Vld: required-interface=SendCANR_EngTqCapbltyMaxTq_FD3Vld
      SendCANR_EngTqCapbltyMinTq_FD3: required-interface=SendCANR_EngTqCapbltyMinTq_FD3
      SendCANR_EngTqCapbltyMinTq_FD3Vld: required-interface=SendCANR_EngTqCapbltyMinTq_FD3Vld
      SendCANR_EngTqCpbtEngOpMd_FD3: required-interface=SendCANR_EngTqCpbtEngOpMd_FD3
      SendCANR_EngTqCpbtEngOpMd_FD3Vld: required-interface=SendCANR_EngTqCpbtEngOpMd_FD3Vld
      SendCANR_EngTqCpbtFrmCntr_FD3: required-interface=SendCANR_EngTqCpbtFrmCntr_FD3
      SendCANR_EngTqCpbtFrmCntr_FD3Vld: required-interface=SendCANR_EngTqCpbtFrmCntr_FD3Vld
      SendCANR_EngTqCpbtRefEngSpd_FD3: required-interface=SendCANR_EngTqCpbtRefEngSpd_FD3
      SendCANR_EngTqCpbtRefEngSpd_FD3Vld: required-interface=SendCANR_EngTqCpbtRefEngSpd_FD3Vld
      SendCANR_EngTqCpbtyMaxOffTqFD3: required-interface=SendCANR_EngTqCpbtyMaxOffTqFD3
      SendCANR_EngTqCpbtyMaxOffTqFD3Vld: required-interface=SendCANR_EngTqCpbtyMaxOffTqFD3Vld
      SendCANR_EngTqCpbtyMinRunTqFD3: required-interface=SendCANR_EngTqCpbtyMinRunTqFD3
      SendCANR_EngTqCpbtyMinRunTqFD3Vld: required-interface=SendCANR_EngTqCpbtyMinRunTqFD3Vld
      SendCANR_EngineMntnSts_FD3: required-interface=SendCANR_EngineMntnSts_FD3
      SendCANR_EngineMntnSts_FD3Vld: required-interface=SendCANR_EngineMntnSts_FD3Vld
      SendCANR_EngineOFFTime_FD3: required-interface=SendCANR_EngineOFFTime_FD3
      SendCANR_EngineOFFTime_FD3Vld: required-interface=SendCANR_EngineOFFTime_FD3Vld
      SendCANR_EngineOilCritical_FD3: required-interface=SendCANR_EngineOilCritical_FD3
      SendCANR_EngineOilCritical_FD3Vld: required-interface=SendCANR_EngineOilCritical_FD3Vld
      SendCANR_EngineOilLevel_FD3: required-interface=SendCANR_EngineOilLevel_FD3
      SendCANR_EngineOilLevel_FD3Vld: required-interface=SendCANR_EngineOilLevel_FD3Vld
      SendCANR_EngineOilMin_FD3: required-interface=SendCANR_EngineOilMin_FD3
      SendCANR_EngineOilMin_FD3Vld: required-interface=SendCANR_EngineOilMin_FD3Vld
      SendCANR_EngineOilOverfill_FD3: required-interface=SendCANR_EngineOilOverfill_FD3
      SendCANR_EngineOilOverfill_FD3Vld: required-interface=SendCANR_EngineOilOverfill_FD3Vld
      SendCANR_EngineOilTempFD3: required-interface=SendCANR_EngineOilTempFD3
      SendCANR_EngineOilTempFD3Vld: required-interface=SendCANR_EngineOilTempFD3Vld
      SendCANR_EngineOperatingModeFD3: required-interface=SendCANR_EngineOperatingModeFD3
      SendCANR_EngineOperatingModeFD3Vld: required-interface=SendCANR_EngineOperatingModeFD3Vld
      SendCANR_EngineWaterTemp_FD3: required-interface=SendCANR_EngineWaterTemp_FD3
      SendCANR_EngineWaterTemp_FD3Vld: required-interface=SendCANR_EngineWaterTemp_FD3Vld
      SendCANR_EstCatCnvTmp_FD3: required-interface=SendCANR_EstCatCnvTmp_FD3
      SendCANR_EstCatCnvTmp_FD3Vld: required-interface=SendCANR_EstCatCnvTmp_FD3Vld
      SendCANR_ExhaustTemperature_FD3: required-interface=SendCANR_ExhaustTemperature_FD3
      SendCANR_ExhaustTemperature_FD3Vld: required-interface=SendCANR_ExhaustTemperature_FD3Vld
      SendCANR_FANStatus_FD3: required-interface=SendCANR_FANStatus_FD3
      SendCANR_FANStatus_FD3Vld: required-interface=SendCANR_FANStatus_FD3Vld
      SendCANR_FuelConsumption_GAGFD3: required-interface=SendCANR_FuelConsumption_GAGFD3
      SendCANR_FuelConsumption_GAGFD3Vld: required-interface=SendCANR_FuelConsumption_GAGFD3Vld
      SendCANR_FuelFltrAck_FD3: required-interface=SendCANR_FuelFltrAck_FD3
      SendCANR_FuelFltrAck_FD3Vld: required-interface=SendCANR_FuelFltrAck_FD3Vld
      SendCANR_FuelFltrLeft_FD3: required-interface=SendCANR_FuelFltrLeft_FD3
      SendCANR_FuelFltrLeft_FD3Vld: required-interface=SendCANR_FuelFltrLeft_FD3Vld
      SendCANR_FuelFltrRq_FD3: required-interface=SendCANR_FuelFltrRq_FD3
      SendCANR_FuelFltrRq_FD3Vld: required-interface=SendCANR_FuelFltrRq_FD3Vld
      SendCANR_FuelMM_Sts_FD3: required-interface=SendCANR_FuelMM_Sts_FD3
      SendCANR_FuelMM_Sts_FD3Vld: required-interface=SendCANR_FuelMM_Sts_FD3Vld
      SendCANR_GF_Charge_FD3: required-interface=SendCANR_GF_Charge_FD3
      SendCANR_GF_Charge_FD3Vld: required-interface=SendCANR_GF_Charge_FD3Vld
      SendCANR_GPFServiceSts_FD3: required-interface=SendCANR_GPFServiceSts_FD3
      SendCANR_GPFServiceSts_FD3Vld: required-interface=SendCANR_GPFServiceSts_FD3Vld
      SendCANR_GearShiftIndicationFD3: required-interface=SendCANR_GearShiftIndicationFD3
      SendCANR_GearShiftIndicationFD3Vld: required-interface=SendCANR_GearShiftIndicationFD3Vld
      SendCANR_GenDenominator_FD3: required-interface=SendCANR_GenDenominator_FD3
      SendCANR_GenDenominator_FD3Vld: required-interface=SendCANR_GenDenominator_FD3Vld
      SendCANR_HOOD_AJAR_STATUS_FD3: required-interface=SendCANR_HOOD_AJAR_STATUS_FD3
      SendCANR_HOOD_AJAR_STATUS_FD3Vld: required-interface=SendCANR_HOOD_AJAR_STATUS_FD3Vld
      SendCANR_HP_MODE_STS_FD3: required-interface=SendCANR_HP_MODE_STS_FD3
      SendCANR_HP_MODE_STS_FD3Vld: required-interface=SendCANR_HP_MODE_STS_FD3Vld
      SendCANR_HighPresrFuelSysFlrFD3: required-interface=SendCANR_HighPresrFuelSysFlrFD3
      SendCANR_HighPresrFuelSysFlrFD3Vld: required-interface=SendCANR_HighPresrFuelSysFlrFD3Vld
      SendCANR_HoursOilLifeRst_FD3: required-interface=SendCANR_HoursOilLifeRst_FD3
      SendCANR_ISASts_FD3: required-interface=SendCANR_ISASts_FD3
      SendCANR_ISASts_FD3Vld: required-interface=SendCANR_ISASts_FD3Vld
      SendCANR_IdleShutDwnAppl_FD3: required-interface=SendCANR_IdleShutDwnAppl_FD3
      SendCANR_IdleShutDwnAppl_FD3Vld: required-interface=SendCANR_IdleShutDwnAppl_FD3Vld
      SendCANR_IdleShutDwnApply_FD3: required-interface=SendCANR_IdleShutDwnApply_FD3
      SendCANR_IdleShutDwnApply_FD3Vld: required-interface=SendCANR_IdleShutDwnApply_FD3Vld
      SendCANR_IgnCntrFuelEngTrue_FD3: required-interface=SendCANR_IgnCntrFuelEngTrue_FD3
      SendCANR_IgnCntrFuelEngTrue_FD3Vld: required-interface=SendCANR_IgnCntrFuelEngTrue_FD3Vld
      SendCANR_IgnCntrTrue_FD3: required-interface=SendCANR_IgnCntrTrue_FD3
      SendCANR_IgnCntrTrue_FD3Vld: required-interface=SendCANR_IgnCntrTrue_FD3Vld
      SendCANR_InpICCFuelEng_Fail_FD3: required-interface=SendCANR_InpICCFuelEng_Fail_FD3
      SendCANR_InpICCFuelEng_Fail_FD3Vld: required-interface=SendCANR_InpICCFuelEng_Fail_FD3Vld
      SendCANR_Inp_ICC_Fail_FD3: required-interface=SendCANR_Inp_ICC_Fail_FD3
      SendCANR_Inp_ICC_Fail_FD3Vld: required-interface=SendCANR_Inp_ICC_Fail_FD3Vld
      SendCANR_InputsGDFail_FD3: required-interface=SendCANR_InputsGDFail_FD3
      SendCANR_InputsGDFail_FD3Vld: required-interface=SendCANR_InputsGDFail_FD3Vld
      SendCANR_KNK_MG_TRIGGER_FD3: required-interface=SendCANR_KNK_MG_TRIGGER_FD3
      SendCANR_KNK_MG_TRIGGER_FD3Vld: required-interface=SendCANR_KNK_MG_TRIGGER_FD3Vld
      SendCANR_LTR_PumpSpeedAct_FD3: required-interface=SendCANR_LTR_PumpSpeedAct_FD3
      SendCANR_LTR_PumpSpeedAct_FD3Vld: required-interface=SendCANR_LTR_PumpSpeedAct_FD3Vld
      SendCANR_LTR_TARGET_TEMP_FD3: required-interface=SendCANR_LTR_TARGET_TEMP_FD3
      SendCANR_LTR_TARGET_TEMP_FD3Vld: required-interface=SendCANR_LTR_TARGET_TEMP_FD3Vld
      SendCANR_LeakCheckTimerValueFD3: required-interface=SendCANR_LeakCheckTimerValueFD3
      SendCANR_LeakCheckTimerValueFD3Vld: required-interface=SendCANR_LeakCheckTimerValueFD3Vld
      SendCANR_LeakTestRequest_FD3: required-interface=SendCANR_LeakTestRequest_FD3
      SendCANR_LeakTestRequest_FD3Vld: required-interface=SendCANR_LeakTestRequest_FD3Vld
      SendCANR_LeakTestSts_FD3: required-interface=SendCANR_LeakTestSts_FD3
      SendCANR_LeakTestSts_FD3Vld: required-interface=SendCANR_LeakTestSts_FD3Vld
      SendCANR_LgsDgCldStCndFltPrFD3: required-interface=SendCANR_LgsDgCldStCndFltPrFD3
      SendCANR_LgsDgCldStCndFltPrFD3Vld: required-interface=SendCANR_LgsDgCldStCndFltPrFD3Vld
      SendCANR_LgsDiagCldStrCndMetFD3: required-interface=SendCANR_LgsDiagCldStrCndMetFD3
      SendCANR_LgsDiagCldStrCndMetFD3Vld: required-interface=SendCANR_LgsDiagCldStrCndMetFD3Vld
      SendCANR_LgsDiagStdCdFltPrs_FD3: required-interface=SendCANR_LgsDiagStdCdFltPrs_FD3
      SendCANR_LgsDiagStdCdFltPrs_FD3Vld: required-interface=SendCANR_LgsDiagStdCdFltPrs_FD3Vld
      SendCANR_LgsDiagStndCondMet_FD3: required-interface=SendCANR_LgsDiagStndCondMet_FD3
      SendCANR_LgsDiagStndCondMet_FD3Vld: required-interface=SendCANR_LgsDiagStndCondMet_FD3Vld
      SendCANR_LoadOBD_FD3: required-interface=SendCANR_LoadOBD_FD3
      SendCANR_LoadOBD_FD3Vld: required-interface=SendCANR_LoadOBD_FD3Vld
      SendCANR_Lv1CrsCtrlOff_FD3: required-interface=SendCANR_Lv1CrsCtrlOff_FD3
      SendCANR_Lv1CrsCtrlOff_FD3Vld: required-interface=SendCANR_Lv1CrsCtrlOff_FD3Vld
      SendCANR_ThrottlePosition_FD3: required-interface=SendCANR_ThrottlePosition_FD3
      SendCANR_RawTPS2_FD3: required-interface=SendCANR_RawTPS2_FD3
      SendCANR_RawTPS1_FD3: required-interface=SendCANR_RawTPS1_FD3
      SendCANR_RawPVS2_FD3: required-interface=SendCANR_RawPVS2_FD3
      SendCANR_RawPVS1_FD3: required-interface=SendCANR_RawPVS1_FD3
      SendCANR_ThrmlMngmtActvW_FD3: required-interface=SendCANR_ThrmlMngmtActvW_FD3
      SendCANR_VehicleSetSpeed_W_FD3: required-interface=SendCANR_VehicleSetSpeed_W_FD3
      SendCANR_TransWarmUpMin_RPM_FD3: required-interface=SendCANR_TransWarmUpMin_RPM_FD3
      SendCANR_TransWarmUpReq_FD3: required-interface=SendCANR_TransWarmUpReq_FD3
      SendCANR_OIL_TEMP_IND_RQ_FD3: required-interface=SendCANR_OIL_TEMP_IND_RQ_FD3
      SendCANR_OIL_TEMP_CHM_RQ_FD3: required-interface=SendCANR_OIL_TEMP_CHM_RQ_FD3
      SendCANR_OIL_IND_LMP_FLSH_FD3: required-interface=SendCANR_OIL_IND_LMP_FLSH_FD3
      SendCANR_OilLifeLeft_FD3: required-interface=SendCANR_OilLifeLeft_FD3
      SendCANR_OilLifeLeftRst_FD3: required-interface=SendCANR_OilLifeLeftRst_FD3
      SendCANR_Override_FD3: required-interface=SendCANR_Override_FD3
      SendCANR_SpeedLimitSts_FD3: required-interface=SendCANR_SpeedLimitSts_FD3
      SendCANR_StrtRlyECMFdbckFltFD3: required-interface=SendCANR_StrtRlyECMFdbckFltFD3
      SendCANR_StrPrctnInhibit_FD3: required-interface=SendCANR_StrPrctnInhibit_FD3
      SendCANR_StrerPrctnTime_FD3: required-interface=SendCANR_StrerPrctnTime_FD3
      SendCANR_TerrainModeStat_ECMFD3: required-interface=SendCANR_TerrainModeStat_ECMFD3
      SendCANR_SAMInfo_FD3: required-interface=SendCANR_SAMInfo_FD3
      SendCANR_Selector_SysFailStsFD3: required-interface=SendCANR_Selector_SysFailStsFD3
      SendCANR_Terrain_HMI_Rq_ECM_FD3: required-interface=SendCANR_Terrain_HMI_Rq_ECM_FD3
      SendCANR_TerModeDesiredStat_FD3: required-interface=SendCANR_TerModeDesiredStat_FD3
      SendCANR_PCPM_PumpSpeedAct_FD3: required-interface=SendCANR_PCPM_PumpSpeedAct_FD3
      SendCANR_OilLifeSts_FD3: required-interface=SendCANR_OilLifeSts_FD3
      SendCANR_SpStDispstat_FD3: required-interface=SendCANR_SpStDispstat_FD3
      SendCANR_SpStIndRq_FD3: required-interface=SendCANR_SpStIndRq_FD3
      SendCANR_SpStSwStat_FD3: required-interface=SendCANR_SpStSwStat_FD3
      SendCANR_OIL_PRESS_FD3: required-interface=SendCANR_OIL_PRESS_FD3
      SendCANR_RefuelEvent_FD3: required-interface=SendCANR_RefuelEvent_FD3
      SendCANR_RefuelIndication_FD3: required-interface=SendCANR_RefuelIndication_FD3
      SendCANR_PECP_PumpFlowReq_FD3: required-interface=SendCANR_PECP_PumpFlowReq_FD3
      SendCANR_RadFanReq_FD3: required-interface=SendCANR_RadFanReq_FD3
      SendCANR_ServiceHybSys_FD3: required-interface=SendCANR_ServiceHybSys_FD3
      SendCANR_OAT_PT_Est_FD3: required-interface=SendCANR_OAT_PT_Est_FD3
      SendCANR_OAT_PT_EstV_FD3: required-interface=SendCANR_OAT_PT_EstV_FD3
      SendCANR_PTO_Acc_Intlk_FD3: required-interface=SendCANR_PTO_Acc_Intlk_FD3
      SendCANR_PTO_Active_FD3: required-interface=SendCANR_PTO_Active_FD3
      SendCANR_PTO_AutoRsm_FD3: required-interface=SendCANR_PTO_AutoRsm_FD3
      SendCANR_PTO_ENGD_RQ_FD3: required-interface=SendCANR_PTO_ENGD_RQ_FD3
      SendCANR_PTOHighIdleEnable_FD3: required-interface=SendCANR_PTOHighIdleEnable_FD3
      SendCANR_PTO_High_Idle_RPM_FD3: required-interface=SendCANR_PTO_High_Idle_RPM_FD3
      SendCANR_PTO_HornRq_FD3: required-interface=SendCANR_PTO_HornRq_FD3
      SendCANR_PTO_Incab_FD3: required-interface=SendCANR_PTO_Incab_FD3
      SendCANR_PTO_MaxVehSpd_FD3: required-interface=SendCANR_PTO_MaxVehSpd_FD3
      SendCANR_PTO_Md_FD3: required-interface=SendCANR_PTO_Md_FD3
      SendCANR_PTOParkBrkRequired_FD3: required-interface=SendCANR_PTOParkBrkRequired_FD3
      SendCANR_PTO_Ramp_Rate_FD3: required-interface=SendCANR_PTO_Ramp_Rate_FD3
      SendCANR_PTORemoteRPMMethod_FD3: required-interface=SendCANR_PTORemoteRPMMethod_FD3
      SendCANR_PTO_RPM{1..3}_FD3: required-interface=SendCANR_PTO_RPM{1..3}_FD3
      SendCANR_PTO_SingleRPM_FD3: required-interface=SendCANR_PTO_SingleRPM_FD3
      SendCANR_PTO_Sts_FD3: required-interface=SendCANR_PTO_Sts_FD3
      SendCANR_PTO_Target_Gear_FD3: required-interface=SendCANR_PTO_Target_Gear_FD3
      SendCANR_PTO_TYPES_FD3: required-interface=SendCANR_PTO_TYPES_FD3
      SendCANR_PTWkSiteInvtrCapECMFD3: required-interface=SendCANR_PTWkSiteInvtrCapECMFD3
      SendCANR_PTWkSiteInvtrStsECMFD3: required-interface=SendCANR_PTWkSiteInvtrStsECMFD3
      SendCANR_TerModIntrfcBtnECM_FD3: required-interface=SendCANR_TerModIntrfcBtnECM_FD3
      SendCANR_TrnsDrvMdCfgStsECMFD3: required-interface=SendCANR_TrnsDrvMdCfgStsECMFD3
      SendCANR_Trns_DrvMdReq_ECM_FD3: required-interface=SendCANR_Trns_DrvMdReq_ECM_FD3
      SendCANR_PerfShftRq_HUD_FD3: required-interface=SendCANR_PerfShftRq_HUD_FD3
      SendCANR_PSI_EnableSts_FD3: required-interface=SendCANR_PSI_EnableSts_FD3
      SendCANR_PSI_Gr{1..5}_RPM_FD3: required-interface=SendCANR_PSI_Gr{1..5}_RPM_FD3
      SendCANR_PSI_Max_RPM_FD3: required-interface=SendCANR_PSI_Max_RPM_FD3
      SendCANR_RACE_CLDWN_BAT_STATFD3: required-interface=SendCANR_RACE_CLDWN_BAT_STATFD3
      SendCANR_RACE_CLDWN_DEA_TIMEFD3: required-interface=SendCANR_RACE_CLDWN_DEA_TIMEFD3
      SendCANR_RACE_CLDWN_SEL_FD3: required-interface=SendCANR_RACE_CLDWN_SEL_FD3
      SendCANR_SYSTEM_STATUS_FD3: required-interface=SendCANR_SYSTEM_STATUS_FD3
      SendCANR_SEIU_Enbl_FD3: required-interface=SendCANR_SEIU_Enbl_FD3
      SendCANR_SEIU_RPM_FD3: required-interface=SendCANR_SEIU_RPM_FD3
      SendCANR_SEIU_Sts_FD3: required-interface=SendCANR_SEIU_Sts_FD3
      SendCANR_PF_RgnActv_FD3: required-interface=SendCANR_PF_RgnActv_FD3
      SendCANR_PFW_Stat_FD3: required-interface=SendCANR_PFW_Stat_FD3
      SendCANR_PrcntCplt_FD3: required-interface=SendCANR_PrcntCplt_FD3
      SendCANR_PreHtIndLmp_On_Rq: required-interface=SendCANR_PreHtIndLmp_On_Rq
      SendCANR_PreHtlmpEVICOnRq_FD3: required-interface=SendCANR_PreHtlmpEVICOnRq_FD3
      SendCANR_RapidCbnWrmupStat_FD3: required-interface=SendCANR_RapidCbnWrmupStat_FD3
      SendCANR_RemainDistUnt_FD3: required-interface=SendCANR_RemainDistUnt_FD3
      SendCANR_SRV_AIR_FLTR_FD3: required-interface=SendCANR_SRV_AIR_FLTR_FD3
      SendCANR_SRV_CCV_FLTR_FD3: required-interface=SendCANR_SRV_CCV_FLTR_FD3
      SendCANR_WtrFuelIndLmpOnRq_FD3: required-interface=SendCANR_WtrFuelIndLmpOnRq_FD3
      SendCANR_StrtRlyBCMFdbckFltFD3: required-interface=SendCANR_StrtRlyBCMFdbckFltFD3
      SendCANR_RevOilLifeRst_FD3: required-interface=SendCANR_RevOilLifeRst_FD3
      SendCANR_OilPressureSts_FD3: required-interface=SendCANR_OilPressureSts_FD3
      SendCANR_ThrottlePosition_FD3Vld: required-interface=SendCANR_ThrottlePosition_FD3Vld
      SendCANR_RawTPS2_FD3Vld: required-interface=SendCANR_RawTPS2_FD3Vld
      SendCANR_RawTPS1_FD3Vld: required-interface=SendCANR_RawTPS1_FD3Vld
      SendCANR_RawPVS2_FD3Vld: required-interface=SendCANR_RawPVS2_FD3Vld
      SendCANR_RawPVS1_FD3Vld: required-interface=SendCANR_RawPVS1_FD3Vld
      SendCANR_ThrmlMngmtActvW_FD3Vld: required-interface=SendCANR_ThrmlMngmtActvW_FD3Vld
      SendCANR_VehicleSetSpeed_W_FD3Vld: required-interface=SendCANR_VehicleSetSpeed_W_FD3Vld
      SendCANR_TransWarmUpMin_RPM_FD3Vld: required-interface=SendCANR_TransWarmUpMin_RPM_FD3Vld
      SendCANR_TransWarmUpReq_FD3Vld: required-interface=SendCANR_TransWarmUpReq_FD3Vld
      SendCANR_OIL_TEMP_IND_RQ_FD3Vld: required-interface=SendCANR_OIL_TEMP_IND_RQ_FD3Vld
      SendCANR_OIL_TEMP_CHM_RQ_FD3Vld: required-interface=SendCANR_OIL_TEMP_CHM_RQ_FD3Vld
      SendCANR_OIL_IND_LMP_FLSH_FD3Vld: required-interface=SendCANR_OIL_IND_LMP_FLSH_FD3Vld
      SendCANR_OilLifeLeft_FD3Vld: required-interface=SendCANR_OilLifeLeft_FD3Vld
      SendCANR_OilLifeLeftRst_FD3Vld: required-interface=SendCANR_OilLifeLeftRst_FD3Vld
      SendCANR_Override_FD3Vld: required-interface=SendCANR_Override_FD3Vld
      SendCANR_SpeedLimitSts_FD3Vld: required-interface=SendCANR_SpeedLimitSts_FD3Vld
      SendCANR_StrtRlyECMFdbckFltFD3Vld: required-interface=SendCANR_StrtRlyECMFdbckFltFD3Vld
      SendCANR_StrPrctnInhibit_FD3Vld: required-interface=SendCANR_StrPrctnInhibit_FD3Vld
      SendCANR_StrerPrctnTime_FD3Vld: required-interface=SendCANR_StrerPrctnTime_FD3Vld
      SendCANR_TerrainModeStat_ECMFD3Vld: required-interface=SendCANR_TerrainModeStat_ECMFD3Vld
      SendCANR_SAMInfo_FD3Vld: required-interface=SendCANR_SAMInfo_FD3Vld
      SendCANR_Selector_SysFailStsFD3Vld: required-interface=SendCANR_Selector_SysFailStsFD3Vld
      SendCANR_Terrain_HMI_Rq_ECM_FD3Vld: required-interface=SendCANR_Terrain_HMI_Rq_ECM_FD3Vld
      SendCANR_TerModeDesiredStat_FD3Vld: required-interface=SendCANR_TerModeDesiredStat_FD3Vld
      SendCANR_OilPressureSts_FD3Vld: required-interface=SendCANR_OilPressureSts_FD3Vld
      SendCANR_OilLifeSts_FD3Vld: required-interface=SendCANR_OilLifeSts_FD3Vld
      SendCANR_SpStDispstat_FD3Vld: required-interface=SendCANR_SpStDispstat_FD3Vld
      SendCANR_SpStIndRq_FD3Vld: required-interface=SendCANR_SpStIndRq_FD3Vld
      SendCANR_SpStSwStat_FD3Vld: required-interface=SendCANR_SpStSwStat_FD3Vld
      SendCANR_OIL_PRESS_FD3Vld: required-interface=SendCANR_OIL_PRESS_FD3Vld
      SendCANR_RefuelEvent_FD3Vld: required-interface=SendCANR_RefuelEvent_FD3Vld
      SendCANR_RefuelIndication_FD3Vld: required-interface=SendCANR_RefuelIndication_FD3Vld
      SendCANR_PECP_PumpFlowReq_FD3Vld: required-interface=SendCANR_PECP_PumpFlowReq_FD3Vld
      SendCANR_RadFanReq_FD3Vld: required-interface=SendCANR_RadFanReq_FD3Vld
      SendCANR_ServiceHybSys_FD3Vld: required-interface=SendCANR_ServiceHybSys_FD3Vld
      SendCANR_OAT_PT_Est_FD3Vld: required-interface=SendCANR_OAT_PT_Est_FD3Vld
      SendCANR_OAT_PT_EstV_FD3Vld: required-interface=SendCANR_OAT_PT_EstV_FD3Vld
      SendCANR_PTO_Acc_Intlk_FD3Vld: required-interface=SendCANR_PTO_Acc_Intlk_FD3Vld
      SendCANR_PTO_Active_FD3Vld: required-interface=SendCANR_PTO_Active_FD3Vld
      SendCANR_PTO_AutoRsm_FD3Vld: required-interface=SendCANR_PTO_AutoRsm_FD3Vld
      SendCANR_PTO_ENGD_RQ_FD3Vld: required-interface=SendCANR_PTO_ENGD_RQ_FD3Vld
      SendCANR_PTOHighIdleEnable_FD3Vld: required-interface=SendCANR_PTOHighIdleEnable_FD3Vld
      SendCANR_PTO_High_Idle_RPM_FD3Vld: required-interface=SendCANR_PTO_High_Idle_RPM_FD3Vld
      SendCANR_PTO_HornRq_FD3Vld: required-interface=SendCANR_PTO_HornRq_FD3Vld
      SendCANR_PTO_Incab_FD3Vld: required-interface=SendCANR_PTO_Incab_FD3Vld
      SendCANR_PTO_MaxVehSpd_FD3Vld: required-interface=SendCANR_PTO_MaxVehSpd_FD3Vld
      SendCANR_PTO_Md_FD3Vld: required-interface=SendCANR_PTO_Md_FD3Vld
      SendCANR_PTOParkBrkRequired_FD3Vld: required-interface=SendCANR_PTOParkBrkRequired_FD3Vld
      SendCANR_PTO_Ramp_Rate_FD3Vld: required-interface=SendCANR_PTO_Ramp_Rate_FD3Vld
      SendCANR_PTORemoteRPMMethod_FD3Vld: required-interface=SendCANR_PTORemoteRPMMethod_FD3Vld
      SendCANR_PTO_RPM{1..3}_FD3Vld: required-interface=SendCANR_PTO_RPM{1..3}_FD3Vld
      SendCANR_PTO_SingleRPM_FD3Vld: required-interface=SendCANR_PTO_SingleRPM_FD3Vld
      SendCANR_PTO_Sts_FD3Vld: required-interface=SendCANR_PTO_Sts_FD3Vld
      SendCANR_PTO_Target_Gear_FD3Vld: required-interface=SendCANR_PTO_Target_Gear_FD3Vld
      SendCANR_PTWkSiteInvtrCapECMFD3Vld: required-interface=SendCANR_PTWkSiteInvtrCapECMFD3Vld
      SendCANR_PTWkSiteInvtrStsECMFD3Vld: required-interface=SendCANR_PTWkSiteInvtrStsECMFD3Vld
      SendCANR_TerModIntrfcBtnECM_FD3Vld: required-interface=SendCANR_TerModIntrfcBtnECM_FD3Vld
      SendCANR_TrnsDrvMdCfgStsECMFD3Vld: required-interface=SendCANR_TrnsDrvMdCfgStsECMFD3Vld
      SendCANR_Trns_DrvMdReq_ECM_FD3Vld: required-interface=SendCANR_Trns_DrvMdReq_ECM_FD3Vld
      SendCANR_PerfShftRq_HUD_FD3Vld: required-interface=SendCANR_PerfShftRq_HUD_FD3Vld
      SendCANR_PCPM_PumpSpeedAct_FD3Vld: required-interface=SendCANR_PCPM_PumpSpeedAct_FD3Vld
      SendCANR_PSI_EnableSts_FD3Vld: required-interface=SendCANR_PSI_EnableSts_FD3Vld
      SendCANR_PSI_Gr{1..5}_RPM_FD3Vld: required-interface=SendCANR_PSI_Gr{1..5}_RPM_FD3Vld
      SendCANR_PSI_Max_RPM_FD3Vld: required-interface=SendCANR_PSI_Max_RPM_FD3Vld
      SendCANR_RACE_CLDWN_BAT_STATFD3Vld: required-interface=SendCANR_RACE_CLDWN_BAT_STATFD3Vld
      SendCANR_RACE_CLDWN_DEA_TIMEFD3Vld: required-interface=SendCANR_RACE_CLDWN_DEA_TIMEFD3Vld
      SendCANR_RACE_CLDWN_SEL_FD3Vld: required-interface=SendCANR_RACE_CLDWN_SEL_FD3Vld
      SendCANR_SYSTEM_STATUS_FD3Vld: required-interface=SendCANR_SYSTEM_STATUS_FD3Vld
      SendCANR_SEIU_Enbl_FD3Vld: required-interface=SendCANR_SEIU_Enbl_FD3Vld
      SendCANR_SEIU_RPM_FD3Vld: required-interface=SendCANR_SEIU_RPM_FD3Vld
      SendCANR_SEIU_Sts_FD3Vld: required-interface=SendCANR_SEIU_Sts_FD3Vld
      SendCANR_PF_RgnActv_FD3Vld: required-interface=SendCANR_PF_RgnActv_FD3Vld
      SendCANR_PFW_Stat_FD3Vld: required-interface=SendCANR_PFW_Stat_FD3Vld
      SendCANR_PrcntCplt_FD3Vld: required-interface=SendCANR_PrcntCplt_FD3Vld
      SendCANR_PreHtIndLmp_On_RqVld: required-interface=SendCANR_PreHtIndLmp_On_RqVld
      SendCANR_PreHtlmpEVICOnRq_FD3Vld: required-interface=SendCANR_PreHtlmpEVICOnRq_FD3Vld
      SendCANR_RapidCbnWrmupStat_FD3Vld: required-interface=SendCANR_RapidCbnWrmupStat_FD3Vld
      SendCANR_RemainDistUnt_FD3Vld: required-interface=SendCANR_RemainDistUnt_FD3Vld
      SendCANR_SRV_AIR_FLTR_FD3Vld: required-interface=SendCANR_SRV_AIR_FLTR_FD3Vld
      SendCANR_SRV_CCV_FLTR_FD3Vld: required-interface=SendCANR_SRV_CCV_FLTR_FD3Vld
      SendCANR_WtrFuelIndLmpOnRq_FD3Vld: required-interface=SendCANR_WtrFuelIndLmpOnRq_FD3Vld
      SendCANR_StrtRlyBCMFdbckFltFD3Vld: required-interface=SendCANR_StrtRlyBCMFdbckFltFD3Vld
      SendCANR_RevOilLifeRst_FD3Vld: required-interface=SendCANR_RevOilLifeRst_FD3Vld
      SendCANR_PTO_TYPES_FD3Vld: required-interface=SendCANR_PTO_TYPES_FD3Vld
    423 x provide port:
      VeCANR_v_Set_Speed_KPH_FD3: provided-interface=VeCANR_v_Set_Speed_KPH_FD3
      VeCANR_y_CRC_ADAS_FD_HMI_FD3: provided-interface=VeCANR_y_CRC_ADAS_FD_HMI_FD3
      VeCANR_y_MC_ADAS_FD_HMI_FD3: provided-interface=VeCANR_y_MC_ADAS_FD_HMI_FD3
      VeCANR_e_TSRSts_FD3: provided-interface=VeCANR_e_TSRSts_FD3
      VeCANR_U_FL_Lvl_RawAD_Src_FD3: provided-interface=VeCANR_U_FL_Lvl_RawAD_Src_FD3
      VeCANR_e_FL_Z_Accel_Stat_SrcFD3: provided-interface=VeCANR_e_FL_Z_Accel_Stat_SrcFD3
      VeCANR_U_FR_Lvl_RawAD_Src_FD3: provided-interface=VeCANR_U_FR_Lvl_RawAD_Src_FD3
      VeCANR_e_FR_Lvl_Stat_Src_FD3: provided-interface=VeCANR_e_FR_Lvl_Stat_Src_FD3
      VeCANR_e_FR_Z_Accel_Stat_SrcFD3: provided-interface=VeCANR_e_FR_Z_Accel_Stat_SrcFD3
      VeCANR_e_RC_Z_Accel_Stat_SrcFD3: provided-interface=VeCANR_e_RC_Z_Accel_Stat_SrcFD3
      VeCANR_U_RL_Lvl_RawAD_Src_FD3: provided-interface=VeCANR_U_RL_Lvl_RawAD_Src_FD3
      VeCANR_e_RL_Lvl_Stat_Src_FD3: provided-interface=VeCANR_e_RL_Lvl_Stat_Src_FD3
      VeCANR_U_RR_Lvl_RawAD_Src_FD3: provided-interface=VeCANR_U_RR_Lvl_RawAD_Src_FD3
      VeCANR_e_RR_Lvl_Stat_Src_FD3: provided-interface=VeCANR_e_RR_Lvl_Stat_Src_FD3
      VeCANR_d_Z_Aclrn_FL_Src_FD3: provided-interface=VeCANR_d_Z_Aclrn_FL_Src_FD3
      VeCANR_d_Z_Aclrn_FR_Src_FD3: provided-interface=VeCANR_d_Z_Aclrn_FR_Src_FD3
      VeCANR_d_Z_Aclrn_RC_Src_FD3: provided-interface=VeCANR_d_Z_Aclrn_RC_Src_FD3
      VeCANR_e_ASCM_Stat_FD3: provided-interface=VeCANR_e_ASCM_Stat_FD3
      VeCANR_b_CompressorACReqSts_FD3: provided-interface=VeCANR_b_CompressorACReqSts_FD3
      VeCANR_e_CmdIgnSts_FD3: provided-interface=VeCANR_e_CmdIgnSts_FD3
      VeCANR_e_SpSt_Pad1_FD3: provided-interface=VeCANR_e_SpSt_Pad1_FD3
      VeCANR_T_ExternalTempC_FD3: provided-interface=VeCANR_T_ExternalTempC_FD3
      VeCANR_e_StopStartClimateInfFD3: provided-interface=VeCANR_e_StopStartClimateInfFD3
      VeCANR_I_AcOutputCurrentSts_FD3: provided-interface=VeCANR_I_AcOutputCurrentSts_FD3
      VeCANR_e_Parallel_PrkAstPad1FD3: provided-interface=VeCANR_e_Parallel_PrkAstPad1FD3
      VeCANR_U_A2D_DRV_TEMP_DR_POSFD3: provided-interface=VeCANR_U_A2D_DRV_TEMP_DR_POSFD3
      VeCANR_b_PARK_BRK_EGD_FD3: provided-interface=VeCANR_b_PARK_BRK_EGD_FD3
      VeCANR_e_Sport_Request_FD3: provided-interface=VeCANR_e_Sport_Request_FD3
      VeCANR_e_TerrainSwStat_FD3: provided-interface=VeCANR_e_TerrainSwStat_FD3
      VeCANR_e_Tow_Request_FD3: provided-interface=VeCANR_e_Tow_Request_FD3
      VeCANR_e_GlobDrvMdRq_BCM_FD3: provided-interface=VeCANR_e_GlobDrvMdRq_BCM_FD3
      VeCANR_e_Left_Button_BCM_FD3: provided-interface=VeCANR_e_Left_Button_BCM_FD3
      VeCANR_e_PowerShot_BCM_FD3: provided-interface=VeCANR_e_PowerShot_BCM_FD3
      VeCANR_e_Right_Button_BCM_FD3: provided-interface=VeCANR_e_Right_Button_BCM_FD3
      VeCANR_e_TerrainMdInfcBtnBCMFD3: provided-interface=VeCANR_e_TerrainMdInfcBtnBCMFD3
      VeCANR_e_Trns_DrvMdReq_BCM_FD3: provided-interface=VeCANR_e_Trns_DrvMdReq_BCM_FD3
      VeCANR_e_Command_15Sts_FD3: provided-interface=VeCANR_e_Command_15Sts_FD3
      VeCANR_P_PowerDraw_FD3: provided-interface=VeCANR_P_PowerDraw_FD3
      VeCANR_b_WorksitInverterActvFD3: provided-interface=VeCANR_b_WorksitInverterActvFD3
      VeCANR_Pct_DRV_TEMP_DR_PSPCTFD3: provided-interface=VeCANR_Pct_DRV_TEMP_DR_PSPCTFD3
      VeCANR_b_HAS_OnOffSts_FD3: provided-interface=VeCANR_b_HAS_OnOffSts_FD3
      VeCANR_e_HVAC_CLNT_FLW_MIN_FD3: provided-interface=VeCANR_e_HVAC_CLNT_FLW_MIN_FD3
      VeCANR_Pct_BlowerDiagnosticsFD3: provided-interface=VeCANR_Pct_BlowerDiagnosticsFD3
      VeCANR_f_Blower_Speed_FD3: provided-interface=VeCANR_f_Blower_Speed_FD3
      VeCANR_e_ITBM_DSP_RQ_FD3: provided-interface=VeCANR_e_ITBM_DSP_RQ_FD3
      VeCANR_e_ITBM_TrlrStat_FD3: provided-interface=VeCANR_e_ITBM_TrlrStat_FD3
      VeCANR_U_Battery_Volt_1_FD3: provided-interface=VeCANR_U_Battery_Volt_1_FD3
      VeCANR_U_Battery_Volt_2_FD3: provided-interface=VeCANR_U_Battery_Volt_2_FD3
      VeCANR_U_ExtrnlTempADVoltageFD3: provided-interface=VeCANR_U_ExtrnlTempADVoltageFD3
      VeCANR_b_BCMSAMFailSts_FD3: provided-interface=VeCANR_b_BCMSAMFailSts_FD3
      VeCANR_U_FUEL_VOLT_FD3: provided-interface=VeCANR_U_FUEL_VOLT_FD3
      VeCANR_U_FUEL_VOLT2_FD3: provided-interface=VeCANR_U_FUEL_VOLT2_FD3
      VeCANR_U_VoltageMax_FD3: provided-interface=VeCANR_U_VoltageMax_FD3
      VeCANR_U_VoltageMin_FD3: provided-interface=VeCANR_U_VoltageMin_FD3
      VeCANR_e_AM_ECM_Trace_FD3: provided-interface=VeCANR_e_AM_ECM_Trace_FD3
      VeCANR_y_CRC_BCM4_FD3: provided-interface=VeCANR_y_CRC_BCM4_FD3
      VeCANR_y_MessageCounter_BCM4FD3: provided-interface=VeCANR_y_MessageCounter_BCM4FD3
      VeCANR_e_ChkFuelLevelSts_FD3: provided-interface=VeCANR_e_ChkFuelLevelSts_FD3
      VeCANR_e_ChkFuelLevelSts2_FD3: provided-interface=VeCANR_e_ChkFuelLevelSts2_FD3
      VeCANR_d_IgnitionOnCounter_FD3: provided-interface=VeCANR_d_IgnitionOnCounter_FD3
      VeCANR_e_Not_OK_To_Race_FD3: provided-interface=VeCANR_e_Not_OK_To_Race_FD3
      VeCANR_y_CRC_BRAKE_FD_6_FD3: provided-interface=VeCANR_y_CRC_BRAKE_FD_6_FD3
      VeCANR_e_DrvrRqAxTrqEnbdBSM_FD3: provided-interface=VeCANR_e_DrvrRqAxTrqEnbdBSM_FD3
      VeCANR_M_DrvrRqdAxTrqBSM_FD3: provided-interface=VeCANR_M_DrvrRqdAxTrqBSM_FD3
      VeCANR_y_MsgCtr_BRAKE_FD_6_FD3: provided-interface=VeCANR_y_MsgCtr_BRAKE_FD_6_FD3
      VeCANR_M_TotalAxle_Rq_BSM_FD3: provided-interface=VeCANR_M_TotalAxle_Rq_BSM_FD3
      VeCANR_b_TotalAxleMaxRq_BSM_FD3: provided-interface=VeCANR_b_TotalAxleMaxRq_BSM_FD3
      VeCANR_b_TotalAxleMinRq_BSM_FD3: provided-interface=VeCANR_b_TotalAxleMinRq_BSM_FD3
      VeCANR_e_SPMControlSts_FD3: provided-interface=VeCANR_e_SPMControlSts_FD3
      VeCANR_e_TCASERANGESTATUS_FD3: provided-interface=VeCANR_e_TCASERANGESTATUS_FD3
      VeCANR_y_CRC_DRIVETRAIN3_FD3: provided-interface=VeCANR_y_CRC_DRIVETRAIN3_FD3
      VeCANR_y_MC_DRIVETRAIN3_FD3: provided-interface=VeCANR_y_MC_DRIVETRAIN3_FD3
      VeCANR_e_EPS_Warn_Disp_Rq_FD3: provided-interface=VeCANR_e_EPS_Warn_Disp_Rq_FD3
      VeCANR_e_FOTA_Install_Type_FD3: provided-interface=VeCANR_e_FOTA_Install_Type_FD3
      VeCANR_e_FOTA_Status_FD3: provided-interface=VeCANR_e_FOTA_Status_FD3
      VeCANR_e_GPF_T1_Status_FD3: provided-interface=VeCANR_e_GPF_T1_Status_FD3
      VeCANR_T_GPF_T1_TEMP_FD3: provided-interface=VeCANR_T_GPF_T1_TEMP_FD3
      VeCANR_e_GPF_T2_Status_FD3: provided-interface=VeCANR_e_GPF_T2_Status_FD3
      VeCANR_T_GPF_T2_TEMP_FD3: provided-interface=VeCANR_T_GPF_T2_TEMP_FD3
      VeCANR_b_CODE_CLR_IDCM_FD3: provided-interface=VeCANR_b_CODE_CLR_IDCM_FD3
      VeCANR_b_REPRGDPFCCLR_IDCM_FD3: provided-interface=VeCANR_b_REPRGDPFCCLR_IDCM_FD3
      VeCANR_b_CODE_CLR_BPCM_FD3: provided-interface=VeCANR_b_CODE_CLR_BPCM_FD3
      VeCANR_b_REPRGDPFCCLR_BPCM_FD3: provided-interface=VeCANR_b_REPRGDPFCCLR_BPCM_FD3
      VeCANR_I_HVBatteryCurrent_FD3: provided-interface=VeCANR_I_HVBatteryCurrent_FD3
      VeCANR_b_HVBatteryMILReq_FD3: provided-interface=VeCANR_b_HVBatteryMILReq_FD3
      VeCANR_Pct_HVBatterySOC_FD3: provided-interface=VeCANR_Pct_HVBatterySOC_FD3
      VeCANR_b_HVBatterySOCV_FD3: provided-interface=VeCANR_b_HVBatterySOCV_FD3
      VeCANR_P_HVBatChargePwrInstant: provided-interface=VeCANR_P_HVBatChargePwrInstant
      VeCANR_b_HVBatChargePwrInstantV: provided-interface=VeCANR_b_HVBatChargePwrInstantV
      VeCANR_P_HVBatChargePwrLong: provided-interface=VeCANR_P_HVBatChargePwrLong
      VeCANR_b_HVBatChargePwrLongV: provided-interface=VeCANR_b_HVBatChargePwrLongV
      VeCANR_P_HVBatChargePwrShort: provided-interface=VeCANR_P_HVBatChargePwrShort
      VeCANR_b_HVBatChargePwrShortV: provided-interface=VeCANR_b_HVBatChargePwrShortV
      VeCANR_b_HVBatDischargePwrLongV: provided-interface=VeCANR_b_HVBatDischargePwrLongV
      VeCANR_t_HVBatteryRealTimClkFD3: provided-interface=VeCANR_t_HVBatteryRealTimClkFD3
      VeCANR_b_HVBattRealTimeClkVFD3: provided-interface=VeCANR_b_HVBattRealTimeClkVFD3
      VeCANR_b_HybridMILRequest_FD3: provided-interface=VeCANR_b_HybridMILRequest_FD3
      VeCANR_T_ElecClntHtrInletTemFD3: provided-interface=VeCANR_T_ElecClntHtrInletTemFD3
      VeCANR_P_ElecCoolantHtrPwr_FD3: provided-interface=VeCANR_P_ElecCoolantHtrPwr_FD3
      VeCANR_T_HeaterCoreInletTempFD3: provided-interface=VeCANR_T_HeaterCoreInletTempFD3
      VeCANR_e_HTAuxPmpMontrngRPM_FD3: provided-interface=VeCANR_e_HTAuxPmpMontrngRPM_FD3
      VeCANR_b_HTShtOffVlvReq_FD3: provided-interface=VeCANR_b_HTShtOffVlvReq_FD3
      VeCANR_n_HTAuxPmpRPMAct_FD3: provided-interface=VeCANR_n_HTAuxPmpRPMAct_FD3
      VeCANR_T_PE_CoolTempIn_FD3: provided-interface=VeCANR_T_PE_CoolTempIn_FD3
      VeCANR_T_PE_CoolTempOut_FD3: provided-interface=VeCANR_T_PE_CoolTempOut_FD3
      VeCANR_Pct_RadiatorFanSts_FD3: provided-interface=VeCANR_Pct_RadiatorFanSts_FD3
      VeCANR_Pct_PECP2_PumpSpdAct_FD3: provided-interface=VeCANR_Pct_PECP2_PumpSpdAct_FD3
      VeCANR_Pct_PECP_PumpSpdAct_FD3: provided-interface=VeCANR_Pct_PECP_PumpSpdAct_FD3
      VeCANR_Pct_LTR_PumpFlowReq_FD3: provided-interface=VeCANR_Pct_LTR_PumpFlowReq_FD3
      VeCANR_Pct_AirflowRequest_FD3: provided-interface=VeCANR_Pct_AirflowRequest_FD3
      VeCANR_b_CurrBattFailStatus_FD3: provided-interface=VeCANR_b_CurrBattFailStatus_FD3
      VeCANR_b_IBS3_Error_InternalFD3: provided-interface=VeCANR_b_IBS3_Error_InternalFD3
      VeCANR_b_IBS3_SOF_V_Acrcy_FD3: provided-interface=VeCANR_b_IBS3_SOF_V_Acrcy_FD3
      VeCANR_U_IBS3_SOF_VC_FD3: provided-interface=VeCANR_U_IBS3_SOF_VC_FD3
      VeCANR_U_IBS3_Vbatt_FD3: provided-interface=VeCANR_U_IBS3_Vbatt_FD3
      VeCANR_b_RsErrIBS3_FD3: provided-interface=VeCANR_b_RsErrIBS3_FD3
      VeCANR_b_VoltBattFailStatus_FD3: provided-interface=VeCANR_b_VoltBattFailStatus_FD3
      VeCANR_I_IBS3_Ibatt_FD3: provided-interface=VeCANR_I_IBS3_Ibatt_FD3
      VeCANR_y_CRC_IBS3DATA1_FD3: provided-interface=VeCANR_y_CRC_IBS3DATA1_FD3
      VeCANR_y_MC_IBS3DATA1_FD3: provided-interface=VeCANR_y_MC_IBS3DATA1_FD3
      VeCANR_Pct_IBS3_SOC_FD3: provided-interface=VeCANR_Pct_IBS3_SOC_FD3
      VeCANR_b_IBS3_SOC_Accuracy_FD3: provided-interface=VeCANR_b_IBS3_SOC_Accuracy_FD3
      VeCANR_q_IBS3_SOH_Q_FD3: provided-interface=VeCANR_q_IBS3_SOH_Q_FD3
      VeCANR_b_IBS3_SOH_Q_Acrcy_FD3: provided-interface=VeCANR_b_IBS3_SOH_Q_Acrcy_FD3
      VeCANR_T_IBS3_T_BATT_FD3: provided-interface=VeCANR_T_IBS3_T_BATT_FD3
      VeCANR_b_IBS3_TempFailStatusFD3: provided-interface=VeCANR_b_IBS3_TempFailStatusFD3
      VeCANR_b_IBS3_FLAG_DISCONNCTFD3: provided-interface=VeCANR_b_IBS3_FLAG_DISCONNCTFD3
      VeCANR_b_IMMO_SOP_REQUEST_FD3: provided-interface=VeCANR_b_IMMO_SOP_REQUEST_FD3
      VeCANR_b_IMPACTCommand_FD3: provided-interface=VeCANR_b_IMPACTCommand_FD3
      VeCANR_b_IMPACTConfirm_FD3: provided-interface=VeCANR_b_IMPACTConfirm_FD3
      VeCANR_b_IMPACTThreshold_FD3: provided-interface=VeCANR_b_IMPACTThreshold_FD3
      VeCANR_l_TotalOdometer_FD3: provided-interface=VeCANR_l_TotalOdometer_FD3
      VeCANR_b_WTS_LmpRqOn_FD3: provided-interface=VeCANR_b_WTS_LmpRqOn_FD3
      VeCANR_y_CRC_IPC1_FD3: provided-interface=VeCANR_y_CRC_IPC1_FD3
      VeCANR_y_MessageCounter_IPC1FD3: provided-interface=VeCANR_y_MessageCounter_IPC1FD3
      VeCANR_b_OilChgRst_FD3: provided-interface=VeCANR_b_OilChgRst_FD3
      VeCANR_e_DisplayedSpdLimSts_FD3: provided-interface=VeCANR_e_DisplayedSpdLimSts_FD3
      VeCANR_e_CFG_Manual_DPF_FD3: provided-interface=VeCANR_e_CFG_Manual_DPF_FD3
      VeCANR_b_FuelFltrRst_FD3: provided-interface=VeCANR_b_FuelFltrRst_FD3
      VeCANR_b_Speed_Unit_FD3: provided-interface=VeCANR_b_Speed_Unit_FD3
      VeCANR_e_New_Spd_Zone_Ind_FD3: provided-interface=VeCANR_e_New_Spd_Zone_Ind_FD3
      VeCANR_b_Traffic_Sign_Info_FD3: provided-interface=VeCANR_b_Traffic_Sign_Info_FD3
      VeCANR_b_Dist_Unit_FD3: provided-interface=VeCANR_b_Dist_Unit_FD3
      VeCANR_b_AlternatorFail_PT_FD3: provided-interface=VeCANR_b_AlternatorFail_PT_FD3
      VeCANR_e_APCM_Rq_PT_FD3: provided-interface=VeCANR_e_APCM_Rq_PT_FD3
      VeCANR_p_AtmPressure_PT_FD3: provided-interface=VeCANR_p_AtmPressure_PT_FD3
      VeCANR_e_AWD_Status_PT_FD3: provided-interface=VeCANR_e_AWD_Status_PT_FD3
      VeCANR_b_CrankEnable_PT_FD3: provided-interface=VeCANR_b_CrankEnable_PT_FD3
      VeCANR_y_CRC_PT_SYSTEM_FD_1_FD3: provided-interface=VeCANR_y_CRC_PT_SYSTEM_FD_1_FD3
      VeCANR_b_DriveReady_PT_FD3: provided-interface=VeCANR_b_DriveReady_PT_FD3
      VeCANR_P_DriverPowerReq_PT_FD3: provided-interface=VeCANR_P_DriverPowerReq_PT_FD3
      VeCANR_b_DrvAway_Alert_PT_FD3: provided-interface=VeCANR_b_DrvAway_Alert_PT_FD3
      VeCANR_b_DrvAway_Inhibit_PT_FD3: provided-interface=VeCANR_b_DrvAway_Inhibit_PT_FD3
      VeCANR_b_ESS_RqShftPark_PT_FD3: provided-interface=VeCANR_b_ESS_RqShftPark_PT_FD3
      VeCANR_e_EVCU2_THA_Resp_FD3: provided-interface=VeCANR_e_EVCU2_THA_Resp_FD3
      VeCANR_Pct_GasPdlPsnPT_FD3: provided-interface=VeCANR_Pct_GasPdlPsnPT_FD3
      VeCANR_b_GasPdlPsnFailStsPT_FD3: provided-interface=VeCANR_b_GasPdlPsnFailStsPT_FD3
      VeCANR_e_GearEngaged_PT_FD3: provided-interface=VeCANR_e_GearEngaged_PT_FD3
      VeCANR_e_GearEngdForDispPT_FD3: provided-interface=VeCANR_e_GearEngdForDispPT_FD3
      VeCANR_b_GearIndcnSts_PT_FD3: provided-interface=VeCANR_b_GearIndcnSts_PT_FD3
      VeCANR_b_HAS_SoH_PT_FD3: provided-interface=VeCANR_b_HAS_SoH_PT_FD3
      VeCANR_y_MsgCtr_PT_SYS_FD_1_FD3: provided-interface=VeCANR_y_MsgCtr_PT_SYS_FD_1_FD3
      VeCANR_b_ParkingFailSts_PT_FD3: provided-interface=VeCANR_b_ParkingFailSts_PT_FD3
      VeCANR_b_ParkingSts_PT_FD3: provided-interface=VeCANR_b_ParkingSts_PT_FD3
      VeCANR_Pct_PdlPosActual_PT_FD3: provided-interface=VeCANR_Pct_PdlPosActual_PT_FD3
      VeCANR_b_PtPrplsnActv_PT_FD3: provided-interface=VeCANR_b_PtPrplsnActv_PT_FD3
      VeCANR_b_R_SHFT_LOCK_PT_FD3: provided-interface=VeCANR_b_R_SHFT_LOCK_PT_FD3
      VeCANR_U_RawPVS1_PT_FD3: provided-interface=VeCANR_U_RawPVS1_PT_FD3
      VeCANR_U_RawPVS2_PT_FD3: provided-interface=VeCANR_U_RawPVS2_PT_FD3
      VeCANR_b_ShiftLvrLockReqPT_FD3: provided-interface=VeCANR_b_ShiftLvrLockReqPT_FD3
      VeCANR_e_ShiftLeverPosn_PT_FD3: provided-interface=VeCANR_e_ShiftLeverPosn_PT_FD3
      VeCANR_e_TargetGear_PT_FD3: provided-interface=VeCANR_e_TargetGear_PT_FD3
      VeCANR_e_TerrainModeStat_PT_FD3: provided-interface=VeCANR_e_TerrainModeStat_PT_FD3
      VeCANR_b_TransFailSts_PT_FD3: provided-interface=VeCANR_b_TransFailSts_PT_FD3
      VeCANR_e_TransWarnings_PT_FD3: provided-interface=VeCANR_e_TransWarnings_PT_FD3
      VeCANR_e_TurtleModeSts_PT_FD3: provided-interface=VeCANR_e_TurtleModeSts_PT_FD3
      VeCANR_e_VehSpdOverriddenPT_FD3: provided-interface=VeCANR_e_VehSpdOverriddenPT_FD3
      VeCANR_b_Warn_BTO_PT_FD3: provided-interface=VeCANR_b_Warn_BTO_PT_FD3
      VeCANR_e_IgnPosSts_FD3: provided-interface=VeCANR_e_IgnPosSts_FD3
      VeCANR_phi_LwsAngle_SCCM_FD3: provided-interface=VeCANR_phi_LwsAngle_SCCM_FD3
      VeCANR_dphi_LwsSpeed_SCCM_FD3: provided-interface=VeCANR_dphi_LwsSpeed_SCCM_FD3
      VeCANR_y_Day1_TLM_FD3: provided-interface=VeCANR_y_Day1_TLM_FD3
      VeCANR_y_Day2_TLM_FD3: provided-interface=VeCANR_y_Day2_TLM_FD3
      VeCANR_y_Hour1_TLM_FD3: provided-interface=VeCANR_y_Hour1_TLM_FD3
      VeCANR_y_Hour2_TLM_FD3: provided-interface=VeCANR_y_Hour2_TLM_FD3
      VeCANR_y_Minute1_TLM_FD3: provided-interface=VeCANR_y_Minute1_TLM_FD3
      VeCANR_y_Minute2_TLM_FD3: provided-interface=VeCANR_y_Minute2_TLM_FD3
      VeCANR_y_Month1_TLM_FD3: provided-interface=VeCANR_y_Month1_TLM_FD3
      VeCANR_y_Month2_TLM_FD3: provided-interface=VeCANR_y_Month2_TLM_FD3
      VeCANR_y_Year{1..4}_TLM_FD3: provided-interface=VeCANR_y_Year{1..4}_TLM_FD3
      VeCANR_e_LaunchRPM_Sel_Sett2FD3: provided-interface=VeCANR_e_LaunchRPM_Sel_Sett2FD3
      VeCANR_b_Launch_SftBtnstatusFD3: provided-interface=VeCANR_b_Launch_SftBtnstatusFD3
      VeCANR_n_PSI_Gr{1..5}_RPM_SET_FD3: provided-interface=VeCANR_n_PSI_Gr{1..5}_RPM_SET_FD3
      VeCANR_b_PSI_RPM_Reset_FD3: provided-interface=VeCANR_b_PSI_RPM_Reset_FD3
      VeCANR_e_PSI_Rq_FD3: provided-interface=VeCANR_e_PSI_Rq_FD3
      VeCANR_b_R_CLDWN_ON_OFF_REQFD3: provided-interface=VeCANR_b_R_CLDWN_ON_OFF_REQFD3
      VeCANR_e_GlobDrvMdRq_FD3: provided-interface=VeCANR_e_GlobDrvMdRq_FD3
      VeCANR_b_IdleShutDown_Dsbl_FD3: provided-interface=VeCANR_b_IdleShutDown_Dsbl_FD3
      VeCANR_n_J1939_RPM_RQ_FD3: provided-interface=VeCANR_n_J1939_RPM_RQ_FD3
      VeCANR_b_PosEngdSwStat_FD3: provided-interface=VeCANR_b_PosEngdSwStat_FD3
      VeCANR_b_PTO_IdleSpd{1..3}_FD3: provided-interface=VeCANR_b_PTO_IdleSpd{1..3}_FD3
      VeCANR_b_ExtrnlTempADVoltageFD3TO: provided-interface=VeCANR_b_ExtrnlTempADVoltageFD3TO
      VeCANR_b_CompressorACReqSts_FD3TO: provided-interface=VeCANR_b_CompressorACReqSts_FD3TO
      VeCANR_b_CmdIgnSts_FD3TO: provided-interface=VeCANR_b_CmdIgnSts_FD3TO
      VeCANR_b_BCMSAMFailSts_FD3TO: provided-interface=VeCANR_b_BCMSAMFailSts_FD3TO
      VeCANR_b_CurrBattFailStatus_FD3TO: provided-interface=VeCANR_b_CurrBattFailStatus_FD3TO
      VeCANR_b_FUEL_VOLT_FD3TO: provided-interface=VeCANR_b_FUEL_VOLT_FD3TO
      VeCANR_b_FUEL_VOLT2_FD3TO: provided-interface=VeCANR_b_FUEL_VOLT2_FD3TO
      VeCANR_b_HVBatteryRealTimClkFD3TO: provided-interface=VeCANR_b_HVBatteryRealTimClkFD3TO
      VeCANR_b_HVBattRealTimeClkVFD3TO: provided-interface=VeCANR_b_HVBattRealTimeClkVFD3TO
      VeCANR_b_IBS3_Error_InternalFD3TO: provided-interface=VeCANR_b_IBS3_Error_InternalFD3TO
      VeCANR_b_IBS3_SOC_FD3TO: provided-interface=VeCANR_b_IBS3_SOC_FD3TO
      VeCANR_b_IBS3_SOC_Accuracy_FD3TO: provided-interface=VeCANR_b_IBS3_SOC_Accuracy_FD3TO
      VeCANR_b_IBS3_SOF_V_Acrcy_FD3TO: provided-interface=VeCANR_b_IBS3_SOF_V_Acrcy_FD3TO
      VeCANR_b_IBS3_SOF_VC_FD3TO: provided-interface=VeCANR_b_IBS3_SOF_VC_FD3TO
      VeCANR_b_IBS3_SOH_Q_FD3TO: provided-interface=VeCANR_b_IBS3_SOH_Q_FD3TO
      VeCANR_b_IBS3_SOH_Q_Acrcy_FD3TO: provided-interface=VeCANR_b_IBS3_SOH_Q_Acrcy_FD3TO
      VeCANR_b_IBS3_T_BATT_FD3TO: provided-interface=VeCANR_b_IBS3_T_BATT_FD3TO
      VeCANR_b_IBS3_TempFailStatusFD3TO: provided-interface=VeCANR_b_IBS3_TempFailStatusFD3TO
      VeCANR_b_IBS3_Vbatt_FD3TO: provided-interface=VeCANR_b_IBS3_Vbatt_FD3TO
      VeCANR_b_OilChgRst_FD3TO: provided-interface=VeCANR_b_OilChgRst_FD3TO
      VeCANR_b_PE_CoolTempIn_FD3TO: provided-interface=VeCANR_b_PE_CoolTempIn_FD3TO
      VeCANR_b_PE_CoolTempOut_FD3TO: provided-interface=VeCANR_b_PE_CoolTempOut_FD3TO
      VeCANR_b_RadiatorFanSts_FD3TO: provided-interface=VeCANR_b_RadiatorFanSts_FD3TO
      VeCANR_b_RsErrIBS3_FD3TO: provided-interface=VeCANR_b_RsErrIBS3_FD3TO
      VeCANR_b_Speed_Unit_FD3TO: provided-interface=VeCANR_b_Speed_Unit_FD3TO
      VeCANR_b_SpSt_Pad1_FD3TO: provided-interface=VeCANR_b_SpSt_Pad1_FD3TO
      VeCANR_b_StopStartClimateInfFD3TO: provided-interface=VeCANR_b_StopStartClimateInfFD3TO
      VeCANR_b_TCASERANGESTATUS_FD3TO: provided-interface=VeCANR_b_TCASERANGESTATUS_FD3TO
      VeCANR_b_TotalOdometer_FD3TO: provided-interface=VeCANR_b_TotalOdometer_FD3TO
      VeCANR_b_VoltageMax_FD3TO: provided-interface=VeCANR_b_VoltageMax_FD3TO
      VeCANR_b_VoltageMin_FD3TO: provided-interface=VeCANR_b_VoltageMin_FD3TO
      VeCANR_b_VoltBattFailStatus_FD3TO: provided-interface=VeCANR_b_VoltBattFailStatus_FD3TO
      VeCANR_b_Set_Speed_KPH_FD3TO: provided-interface=VeCANR_b_Set_Speed_KPH_FD3TO
      VeCANR_b_TSRSts_FD3TO: provided-interface=VeCANR_b_TSRSts_FD3TO
      VeCANR_b_ASCM_Stat_FD3TO: provided-interface=VeCANR_b_ASCM_Stat_FD3TO
      VeCANR_b_AcOutputCurrentSts_FD3TO: provided-interface=VeCANR_b_AcOutputCurrentSts_FD3TO
      VeCANR_b_Parallel_PrkAstPad1FD3TO: provided-interface=VeCANR_b_Parallel_PrkAstPad1FD3TO
      VeCANR_b_A2D_DRV_TEMP_DR_POSFD3TO: provided-interface=VeCANR_b_A2D_DRV_TEMP_DR_POSFD3TO
      VeCANR_b_Sport_Request_FD3TO: provided-interface=VeCANR_b_Sport_Request_FD3TO
      VeCANR_b_TerrainSwStat_FD3TO: provided-interface=VeCANR_b_TerrainSwStat_FD3TO
      VeCANR_b_DRV_TEMP_DR_PSPCTFD3TO: provided-interface=VeCANR_b_DRV_TEMP_DR_PSPCTFD3TO
      VeCANR_b_HAS_OnOffSts_FD3TO: provided-interface=VeCANR_b_HAS_OnOffSts_FD3TO
      VeCANR_b_HVAC_CLNT_FLW_MIN_FD3TO: provided-interface=VeCANR_b_HVAC_CLNT_FLW_MIN_FD3TO
      VeCANR_b_BlowerDiagnosticsFD3TO: provided-interface=VeCANR_b_BlowerDiagnosticsFD3TO
      VeCANR_b_Blower_Speed_FD3TO: provided-interface=VeCANR_b_Blower_Speed_FD3TO
      VeCANR_b_Battery_Volt_1_FD3TO: provided-interface=VeCANR_b_Battery_Volt_1_FD3TO
      VeCANR_b_AM_ECM_Trace_FD3TO: provided-interface=VeCANR_b_AM_ECM_Trace_FD3TO
      VeCANR_b_ChkFuelLevelSts_FD3TO: provided-interface=VeCANR_b_ChkFuelLevelSts_FD3TO
      VeCANR_b_IgnitionOnCounter_FD3TO: provided-interface=VeCANR_b_IgnitionOnCounter_FD3TO
      VeCANR_b_SPMControlSts_FD3TO: provided-interface=VeCANR_b_SPMControlSts_FD3TO
      VeCANR_b_GPF_T1_Status_FD3TO: provided-interface=VeCANR_b_GPF_T1_Status_FD3TO
      VeCANR_b_GPF_T1_TEMP_FD3TO: provided-interface=VeCANR_b_GPF_T1_TEMP_FD3TO
      VeCANR_b_GPF_T2_Status_FD3TO: provided-interface=VeCANR_b_GPF_T2_Status_FD3TO
      VeCANR_b_GPF_T2_TEMP_FD3TO: provided-interface=VeCANR_b_GPF_T2_TEMP_FD3TO
      VeCANR_b_CODE_CLR_IDCM_FD3TO: provided-interface=VeCANR_b_CODE_CLR_IDCM_FD3TO
      VeCANR_b_REPRGDPFCCLR_IDCM_FD3TO: provided-interface=VeCANR_b_REPRGDPFCCLR_IDCM_FD3TO
      VeCANR_b_CODE_CLR_BPCM_FD3TO: provided-interface=VeCANR_b_CODE_CLR_BPCM_FD3TO
      VeCANR_b_REPRGDPFCCLR_BPCM_FD3TO: provided-interface=VeCANR_b_REPRGDPFCCLR_BPCM_FD3TO
      VeCANR_b_HVBatteryMILReq_FD3TO: provided-interface=VeCANR_b_HVBatteryMILReq_FD3TO
      VeCANR_b_HVBatterySOC_FD3TO: provided-interface=VeCANR_b_HVBatterySOC_FD3TO
      VeCANR_b_HVBatterySOCV_FD3TO: provided-interface=VeCANR_b_HVBatterySOCV_FD3TO
      VeCANR_b_HVBatChargePwrInstantTO: provided-interface=VeCANR_b_HVBatChargePwrInstantTO
      VeCANR_b_HVBatChargePwrInstantV_TO: provided-interface=VeCANR_b_HVBatChargePwrInstantV_TO
      VeCANR_b_HVBatChargePwrLongTO: provided-interface=VeCANR_b_HVBatChargePwrLongTO
      VeCANR_b_HVBatChargePwrLongV_TO: provided-interface=VeCANR_b_HVBatChargePwrLongV_TO
      VeCANR_b_HVBatChargePwrShortTO: provided-interface=VeCANR_b_HVBatChargePwrShortTO
      VeCANR_b_HVBatChargePwrShortV_TO: provided-interface=VeCANR_b_HVBatChargePwrShortV_TO
      VeCANR_b_HVBatDischargePwrLongV_TO: provided-interface=VeCANR_b_HVBatDischargePwrLongV_TO
      VeCANR_b_HybridMILRequest_FD3TO: provided-interface=VeCANR_b_HybridMILRequest_FD3TO
      VeCANR_b_ElecClntHtrInletTemFD3TO: provided-interface=VeCANR_b_ElecClntHtrInletTemFD3TO
      VeCANR_b_ElecCoolantHtrPwr_FD3TO: provided-interface=VeCANR_b_ElecCoolantHtrPwr_FD3TO
      VeCANR_b_HeaterCoreInletTempFD3TO: provided-interface=VeCANR_b_HeaterCoreInletTempFD3TO
      VeCANR_b_HTAuxPmpMontrngRPM_FD3TO: provided-interface=VeCANR_b_HTAuxPmpMontrngRPM_FD3TO
      VeCANR_b_HTShtOffVlvReq_FD3TO: provided-interface=VeCANR_b_HTShtOffVlvReq_FD3TO
      VeCANR_b_PECP2_PumpSpdAct_FD3TO: provided-interface=VeCANR_b_PECP2_PumpSpdAct_FD3TO
      VeCANR_b_PECP_PumpSpdAct_FD3TO: provided-interface=VeCANR_b_PECP_PumpSpdAct_FD3TO
      VeCANR_b_IBS3_Ibatt_FD3TO: provided-interface=VeCANR_b_IBS3_Ibatt_FD3TO
      VeCANR_b_IBS3_FLAG_DISCONNCTFD3TO: provided-interface=VeCANR_b_IBS3_FLAG_DISCONNCTFD3TO
      VeCANR_b_IMMO_SOP_REQUEST_FD3TO: provided-interface=VeCANR_b_IMMO_SOP_REQUEST_FD3TO
      VeCANR_b_IMPACTCommand_FD3TO: provided-interface=VeCANR_b_IMPACTCommand_FD3TO
      VeCANR_b_IMPACTConfirm_FD3TO: provided-interface=VeCANR_b_IMPACTConfirm_FD3TO
      VeCANR_b_IMPACTThreshold_FD3TO: provided-interface=VeCANR_b_IMPACTThreshold_FD3TO
      VeCANR_b_DisplayedSpdLimSts_FD3TO: provided-interface=VeCANR_b_DisplayedSpdLimSts_FD3TO
      VeCANR_b_New_Spd_Zone_Ind_FD3TO: provided-interface=VeCANR_b_New_Spd_Zone_Ind_FD3TO
      VeCANR_b_Traffic_Sign_Info_FD3TO: provided-interface=VeCANR_b_Traffic_Sign_Info_FD3TO
      VeCANR_b_Day1_TLM_FD3TO: provided-interface=VeCANR_b_Day1_TLM_FD3TO
      VeCANR_b_Day2_TLM_FD3TO: provided-interface=VeCANR_b_Day2_TLM_FD3TO
      VeCANR_b_Hour1_TLM_FD3TO: provided-interface=VeCANR_b_Hour1_TLM_FD3TO
      VeCANR_b_Hour2_TLM_FD3TO: provided-interface=VeCANR_b_Hour2_TLM_FD3TO
      VeCANR_b_Minute1_TLM_FD3TO: provided-interface=VeCANR_b_Minute1_TLM_FD3TO
      VeCANR_b_Minute2_TLM_FD3TO: provided-interface=VeCANR_b_Minute2_TLM_FD3TO
      VeCANR_b_Month1_TLM_FD3TO: provided-interface=VeCANR_b_Month1_TLM_FD3TO
      VeCANR_b_Month2_TLM_FD3TO: provided-interface=VeCANR_b_Month2_TLM_FD3TO
      VeCANR_b_Year{1..4}_TLM_FD3TO: provided-interface=VeCANR_b_Year{1..4}_TLM_FD3TO
      VeCANR_b_Tow_Request_FD3TO: provided-interface=VeCANR_b_Tow_Request_FD3TO
      VeCANR_b_FL_Lvl_RawAD_Src_FD3TO: provided-interface=VeCANR_b_FL_Lvl_RawAD_Src_FD3TO
      VeCANR_b_FL_Lvl_Stat_Src_FD3TO: provided-interface=VeCANR_b_FL_Lvl_Stat_Src_FD3TO
      VeCANR_b_FL_Z_Accel_Stat_SrcFD3TO: provided-interface=VeCANR_b_FL_Z_Accel_Stat_SrcFD3TO
      VeCANR_b_FR_Lvl_RawAD_Src_FD3TO: provided-interface=VeCANR_b_FR_Lvl_RawAD_Src_FD3TO
      VeCANR_b_FR_Lvl_Stat_Src_FD3TO: provided-interface=VeCANR_b_FR_Lvl_Stat_Src_FD3TO
      VeCANR_b_FR_Z_Accel_Stat_SrcFD3TO: provided-interface=VeCANR_b_FR_Z_Accel_Stat_SrcFD3TO
      VeCANR_b_RC_Z_Accel_Stat_SrcFD3TO: provided-interface=VeCANR_b_RC_Z_Accel_Stat_SrcFD3TO
      VeCANR_b_RL_Lvl_RawAD_Src_FD3TO: provided-interface=VeCANR_b_RL_Lvl_RawAD_Src_FD3TO
      VeCANR_b_RL_Lvl_Stat_Src_FD3TO: provided-interface=VeCANR_b_RL_Lvl_Stat_Src_FD3TO
      VeCANR_b_RR_Lvl_RawAD_Src_FD3TO: provided-interface=VeCANR_b_RR_Lvl_RawAD_Src_FD3TO
      VeCANR_b_RR_Lvl_Stat_Src_FD3TO: provided-interface=VeCANR_b_RR_Lvl_Stat_Src_FD3TO
      VeCANR_b_Z_Aclrn_FL_Src_FD3TO: provided-interface=VeCANR_b_Z_Aclrn_FL_Src_FD3TO
      VeCANR_b_Z_Aclrn_FR_Src_FD3TO: provided-interface=VeCANR_b_Z_Aclrn_FR_Src_FD3TO
      VeCANR_b_Z_Aclrn_RC_Src_FD3TO: provided-interface=VeCANR_b_Z_Aclrn_RC_Src_FD3TO
      VeCANR_b_ExternalTempC_FD3TO: provided-interface=VeCANR_b_ExternalTempC_FD3TO
      VeCANR_b_PARK_BRK_EGD_FD3TO: provided-interface=VeCANR_b_PARK_BRK_EGD_FD3TO
      VeCANR_b_GlobDrvMdRq_BCM_FD3TO: provided-interface=VeCANR_b_GlobDrvMdRq_BCM_FD3TO
      VeCANR_b_Left_Button_BCM_FD3TO: provided-interface=VeCANR_b_Left_Button_BCM_FD3TO
      VeCANR_b_PowerShot_BCM_FD3TO: provided-interface=VeCANR_b_PowerShot_BCM_FD3TO
      VeCANR_b_Right_Button_BCM_FD3TO: provided-interface=VeCANR_b_Right_Button_BCM_FD3TO
      VeCANR_b_TerrainMdInfcBtnBCMFD3TO: provided-interface=VeCANR_b_TerrainMdInfcBtnBCMFD3TO
      VeCANR_b_Trns_DrvMdReq_BCM_FD3TO: provided-interface=VeCANR_b_Trns_DrvMdReq_BCM_FD3TO
      VeCANR_b_Command_15Sts_FD3TO: provided-interface=VeCANR_b_Command_15Sts_FD3TO
      VeCANR_b_PowerDraw_FD3TO: provided-interface=VeCANR_b_PowerDraw_FD3TO
      VeCANR_b_WorksitInverterActvFD3TO: provided-interface=VeCANR_b_WorksitInverterActvFD3TO
      VeCANR_b_ITBM_DSP_RQ_FD3TO: provided-interface=VeCANR_b_ITBM_DSP_RQ_FD3TO
      VeCANR_b_ITBM_TrlrStat_FD3TO: provided-interface=VeCANR_b_ITBM_TrlrStat_FD3TO
      VeCANR_b_Battery_Volt_2_FD3TO: provided-interface=VeCANR_b_Battery_Volt_2_FD3TO
      VeCANR_b_CRC_BCM4_FD3TO: provided-interface=VeCANR_b_CRC_BCM4_FD3TO
      VeCANR_b_MessageCounter_BCM4FD3TO: provided-interface=VeCANR_b_MessageCounter_BCM4FD3TO
      VeCANR_b_ChkFuelLevelSts2_FD3TO: provided-interface=VeCANR_b_ChkFuelLevelSts2_FD3TO
      VeCANR_b_Not_OK_To_Race_FD3TO: provided-interface=VeCANR_b_Not_OK_To_Race_FD3TO
      VeCANR_b_EPS_Warn_Disp_Rq_FD3TO: provided-interface=VeCANR_b_EPS_Warn_Disp_Rq_FD3TO
      VeCANR_b_FOTA_Install_Type_FD3TO: provided-interface=VeCANR_b_FOTA_Install_Type_FD3TO
      VeCANR_b_FOTA_Status_FD3TO: provided-interface=VeCANR_b_FOTA_Status_FD3TO
      VeCANR_b_HVBatteryCurrent_FD3TO: provided-interface=VeCANR_b_HVBatteryCurrent_FD3TO
      VeCANR_b_LTR_PumpFlowReq_FD3TO: provided-interface=VeCANR_b_LTR_PumpFlowReq_FD3TO
      VeCANR_b_CRC_IBS3DATA1_FD3TO: provided-interface=VeCANR_b_CRC_IBS3DATA1_FD3TO
      VeCANR_b_MC_IBS3DATA1_FD3TO: provided-interface=VeCANR_b_MC_IBS3DATA1_FD3TO
      VeCANR_b_WTS_LmpRqOn_FD3TO: provided-interface=VeCANR_b_WTS_LmpRqOn_FD3TO
      VeCANR_b_CFG_Manual_DPF_FD3TO: provided-interface=VeCANR_b_CFG_Manual_DPF_FD3TO
      VeCANR_b_FuelFltrRst_FD3TO: provided-interface=VeCANR_b_FuelFltrRst_FD3TO
      VeCANR_b_Dist_Unit_FD3TO: provided-interface=VeCANR_b_Dist_Unit_FD3TO
      VeCANR_b_AlternatorFail_PT_FD3TO: provided-interface=VeCANR_b_AlternatorFail_PT_FD3TO
      VeCANR_b_APCM_Rq_PT_FD3TO: provided-interface=VeCANR_b_APCM_Rq_PT_FD3TO
      VeCANR_b_AtmPressure_PT_FD3TO: provided-interface=VeCANR_b_AtmPressure_PT_FD3TO
      VeCANR_b_AWD_Status_PT_FD3TO: provided-interface=VeCANR_b_AWD_Status_PT_FD3TO
      VeCANR_b_CrankEnable_PT_FD3TO: provided-interface=VeCANR_b_CrankEnable_PT_FD3TO
      VeCANR_b_CRC_PT_SYSTEM_FD_1_FD3TO: provided-interface=VeCANR_b_CRC_PT_SYSTEM_FD_1_FD3TO
      VeCANR_b_DriveReady_PT_FD3TO: provided-interface=VeCANR_b_DriveReady_PT_FD3TO
      VeCANR_b_DriverPowerReq_PT_FD3TO: provided-interface=VeCANR_b_DriverPowerReq_PT_FD3TO
      VeCANR_b_DrvAway_Alert_PT_FD3TO: provided-interface=VeCANR_b_DrvAway_Alert_PT_FD3TO
      VeCANR_b_DrvAway_Inhibit_PT_FD3TO: provided-interface=VeCANR_b_DrvAway_Inhibit_PT_FD3TO
      VeCANR_b_ESS_RqShftPark_PT_FD3TO: provided-interface=VeCANR_b_ESS_RqShftPark_PT_FD3TO
      VeCANR_b_EVCU2_THA_Resp_FD3TO: provided-interface=VeCANR_b_EVCU2_THA_Resp_FD3TO
      VeCANR_b_GasPdlPsnPT_FD3TO: provided-interface=VeCANR_b_GasPdlPsnPT_FD3TO
      VeCANR_b_GasPdlPsnFailStsPT_FD3TO: provided-interface=VeCANR_b_GasPdlPsnFailStsPT_FD3TO
      VeCANR_b_GearEngaged_PT_FD3TO: provided-interface=VeCANR_b_GearEngaged_PT_FD3TO
      VeCANR_b_GearEngdForDispPT_FD3TO: provided-interface=VeCANR_b_GearEngdForDispPT_FD3TO
      VeCANR_b_GearIndcnSts_PT_FD3TO: provided-interface=VeCANR_b_GearIndcnSts_PT_FD3TO
      VeCANR_b_HAS_SoH_PT_FD3TO: provided-interface=VeCANR_b_HAS_SoH_PT_FD3TO
      VeCANR_b_MsgCtr_PT_SYS_FD_1_FD3TO: provided-interface=VeCANR_b_MsgCtr_PT_SYS_FD_1_FD3TO
      VeCANR_b_ParkingFailSts_PT_FD3TO: provided-interface=VeCANR_b_ParkingFailSts_PT_FD3TO
      VeCANR_b_ParkingSts_PT_FD3TO: provided-interface=VeCANR_b_ParkingSts_PT_FD3TO
      VeCANR_b_PdlPosActual_PT_FD3TO: provided-interface=VeCANR_b_PdlPosActual_PT_FD3TO
      VeCANR_b_PtPrplsnActv_PT_FD3TO: provided-interface=VeCANR_b_PtPrplsnActv_PT_FD3TO
      VeCANR_b_R_SHFT_LOCK_PT_FD3TO: provided-interface=VeCANR_b_R_SHFT_LOCK_PT_FD3TO
      VeCANR_b_RawPVS1_PT_FD3TO: provided-interface=VeCANR_b_RawPVS1_PT_FD3TO
      VeCANR_b_RawPVS2_PT_FD3TO: provided-interface=VeCANR_b_RawPVS2_PT_FD3TO
      VeCANR_b_ShiftLvrLockReqPT_FD3TO: provided-interface=VeCANR_b_ShiftLvrLockReqPT_FD3TO
      VeCANR_b_ShiftLeverPosn_PT_FD3TO: provided-interface=VeCANR_b_ShiftLeverPosn_PT_FD3TO
      VeCANR_b_TargetGear_PT_FD3TO: provided-interface=VeCANR_b_TargetGear_PT_FD3TO
      VeCANR_b_TerrainModeStat_PT_FD3TO: provided-interface=VeCANR_b_TerrainModeStat_PT_FD3TO
      VeCANR_b_TransFailSts_PT_FD3TO: provided-interface=VeCANR_b_TransFailSts_PT_FD3TO
      VeCANR_b_TransWarnings_PT_FD3TO: provided-interface=VeCANR_b_TransWarnings_PT_FD3TO
      VeCANR_b_TurtleModeSts_PT_FD3TO: provided-interface=VeCANR_b_TurtleModeSts_PT_FD3TO
      VeCANR_b_VehSpdOverriddenPT_FD3TO: provided-interface=VeCANR_b_VehSpdOverriddenPT_FD3TO
      VeCANR_b_Warn_BTO_PT_FD3TO: provided-interface=VeCANR_b_Warn_BTO_PT_FD3TO
      VeCANR_b_IgnPosSts_FD3TO: provided-interface=VeCANR_b_IgnPosSts_FD3TO
      VeCANR_b_LwsAngle_SCCM_FD3TO: provided-interface=VeCANR_b_LwsAngle_SCCM_FD3TO
      VeCANR_b_LwsSpeed_SCCM_FD3TO: provided-interface=VeCANR_b_LwsSpeed_SCCM_FD3TO
      VeCANR_b_LaunchRPM_Sel_Sett2FD3TO: provided-interface=VeCANR_b_LaunchRPM_Sel_Sett2FD3TO
      VeCANR_b_Launch_SftBtnstatusFD3TO: provided-interface=VeCANR_b_Launch_SftBtnstatusFD3TO
      VeCANR_b_PSI_Gr{1..5}_RPM_SET_FD3TO: provided-interface=VeCANR_b_PSI_Gr{1..5}_RPM_SET_FD3TO
      VeCANR_b_PSI_RPM_Reset_FD3TO: provided-interface=VeCANR_b_PSI_RPM_Reset_FD3TO
      VeCANR_b_PSI_Rq_FD3TO: provided-interface=VeCANR_b_PSI_Rq_FD3TO
      VeCANR_b_R_CLDWN_ON_OFF_REQFD3TO: provided-interface=VeCANR_b_R_CLDWN_ON_OFF_REQFD3TO
      VeCANR_b_GlobDrvMdRq_FD3TO: provided-interface=VeCANR_b_GlobDrvMdRq_FD3TO
      VeCANR_b_IdleShutDown_Dsbl_FD3TO: provided-interface=VeCANR_b_IdleShutDown_Dsbl_FD3TO
      VeCANR_b_HTAuxPmpRPMAct_FD3TO: provided-interface=VeCANR_b_HTAuxPmpRPMAct_FD3TO
      VeCANR_b_AirflowRequest_FD3TO: provided-interface=VeCANR_b_AirflowRequest_FD3TO
      VeCANR_b_CRC_IPC1_FD3TO: provided-interface=VeCANR_b_CRC_IPC1_FD3TO
      VeCANR_b_MessageCounter_IPC1FD3TO: provided-interface=VeCANR_b_MessageCounter_IPC1FD3TO
      VeCANR_b_J1939_RPM_RQ_FD3TO: provided-interface=VeCANR_b_J1939_RPM_RQ_FD3TO
      VeCANR_b_PosEngdSwStat_FD3TO: provided-interface=VeCANR_b_PosEngdSwStat_FD3TO
      VeCANR_b_PTO_IdleSpd{1..3}_FD3TO: provided-interface=VeCANR_b_PTO_IdleSpd{1..3}_FD3TO
      VeCANR_b_CRC_BRAKE_FD_6_FD3TO: provided-interface=VeCANR_b_CRC_BRAKE_FD_6_FD3TO
      VeCANR_b_DrvrRqAxTrqEnbdBSM_FD3TO: provided-interface=VeCANR_b_DrvrRqAxTrqEnbdBSM_FD3TO
      VeCANR_b_DrvrRqdAxTrqBSM_FD3TO: provided-interface=VeCANR_b_DrvrRqdAxTrqBSM_FD3TO
      VeCANR_b_MsgCtr_BRAKE_FD_6_FD3TO: provided-interface=VeCANR_b_MsgCtr_BRAKE_FD_6_FD3TO
      VeCANR_b_TotalAxle_Rq_BSM_FD3TO: provided-interface=VeCANR_b_TotalAxle_Rq_BSM_FD3TO
      VeCANR_b_TotalAxleMaxRq_BSM_FD3TO: provided-interface=VeCANR_b_TotalAxleMaxRq_BSM_FD3TO
      VeCANR_b_TotalAxleMinRq_BSM_FD3TO: provided-interface=VeCANR_b_TotalAxleMinRq_BSM_FD3TO
      VeCANR_b_CRC_DRIVETRAIN3_FD3TO: provided-interface=VeCANR_b_CRC_DRIVETRAIN3_FD3TO
      VeCANR_b_MC_DRIVETRAIN3_FD3TO: provided-interface=VeCANR_b_MC_DRIVETRAIN3_FD3TO
      VeCANR_b_CRC_ADAS_FD_HMI_FD3TO: provided-interface=VeCANR_b_CRC_ADAS_FD_HMI_FD3TO
      VeCANR_b_MC_ADAS_FD_HMI_FD3TO: provided-interface=VeCANR_b_MC_ADAS_FD_HMI_FD3TO
      VeCANR_e_FL_Lvl_Stat_Src_FD3: provided-interface=VeCANR_e_FL_Lvl_Stat_Src_FD3
      GetRPMR_n_EngSpdFastRate: provided-interface=GetRPMR_n_EngSpdFastRate
    require port VeLTIR_b_L2_EngSpdFaild: required-interface=VeLTIR_b_L2_EngSpdFaild
    provide port VeLISR_h_DigIonSnsRes3: provided-interface=VeLISR_h_DigIonSnsRes
    provide port VeLISR_h_DigIonSnsRes4: provided-interface=VeLISR_h_DigIonSnsRes
